VERSION "HNNBNNNYNNNNNNNNNNNNNNNNNNNNNNNNNNNNNNNNNN/4/%%%/4/'%**4NNN///"

NS_ :

BS_:

BU_: BAP_Tester BedienDisp_vo BedienSG_hi CGS DDA Gateway Gateway_PAG GurtMikrofon OTA_FC ZR_High ZR_LIMU ZR_MIB_TOP_ab_Gen3 ZR_Standard

BO_ 2589283621 Klima_17: 8 Gateway
 SG_ KL_NV_Energie_Anf : 12|8@1+ (10,0) [0|2530] "Unit_WattHour"  Vector__XXX
 SG_ KL_FlHz_Soll_VL : 20|3@1+ (1,0) [0|6] "Unit_None"  ZR_High
 SG_ KL_FlHz_Soll_HL : 23|3@1+ (1,0) [0|6] "Unit_None"  ZR_High
 SG_ KL_FlHz_Soll_VR : 26|3@1+ (1,0) [0|6] "Unit_None"  ZR_High
 SG_ KL_FlHz_Soll_HR : 29|3@1+ (1,0) [0|6] "Unit_None"  ZR_High
 SG_ KL_Umluft_Connect_status : 32|3@1+ (1.0,0.0) [0.0|7] ""  ZR_High,ZR_Standard
 SG_ KL_ECO_PRO_Aktiv : 35|1@1+ (1.0,0.0) [0.0|1] ""  OTA_FC,ZR_High
 SG_ KL_QBit_Sonnenintensitaet : 36|1@1+ (1.0,0.0) [0.0|1] ""  Vector__XXX
 SG_ KL_ZR_Anforderung : 37|2@1+ (1.0,0.0) [0.0|3] ""  ZR_High,ZR_LIMU,ZR_MIB_TOP_ab_Gen3,ZR_Standard
 SG_ KL_ACmax_Aktiv : 39|1@1+ (1.0,0.0) [0.0|1] ""  OTA_FC,ZR_High
 SG_ KL_Defrost_Aktiv : 40|1@1+ (1.0,0.0) [0.0|1] ""  OTA_FC,ZR_High
 SG_ KL_ECO_Aktiv : 41|1@1+ (1.0,0.0) [0.0|1] ""  OTA_FC,ZR_High
 SG_ KL_Status_Klimastil : 42|2@1+ (1.0,0.0) [0.0|3] ""  OTA_FC,ZR_High
 SG_ KL_Kundeneingriff_Geblaese : 44|1@1+ (1.0,0.0) [0.0|1] ""  OTA_FC,ZR_High
 SG_ KL_Thermischer_Bedarf : 45|3@1+ (1.0,0.0) [0.0|7] ""  Vector__XXX
 SG_ KL_Eps_Innen : 48|8@1+ (0.5,-50) [-50.0|50.0] "Unit_DegreCelsi"  OTA_FC,ZR_High
 SG_ KL_Sonnenintensitaet : 56|8@1+ (10,0) [0|1000] "Unit_WattPerMeterSquar"  OTA_FC,ZR_High

BO_ 992 Klima_hinten_01: 8 Gateway
 SG_ KL_Fond_Fuss_Temp_hl : 0|10@1+ (0.1,-5) [-5.0|97.1] "Unit_DegreCelsi"  ZR_High
 SG_ KL_SL_Soll_hl : 10|3@1+ (1.0,0.0) [0.0|7] ""  ZR_High
 SG_ KL_SL_Soll_hr : 13|3@1+ (1.0,0.0) [0.0|7] ""  ZR_High
 SG_ KL_Fond_Fuss_Temp_hr : 16|10@1+ (0.1,-5) [-5.0|97.1] "Unit_DegreCelsi"  ZR_High
 SG_ KL_SH_Soll_hl : 26|3@1+ (1.0,0.0) [0.0|7] ""  ZR_High
 SG_ KL_SH_Soll_hr : 29|3@1+ (1.0,0.0) [0.0|7] ""  ZR_High
 SG_ KL_MA_Temp_hl : 32|10@1+ (0.1,-5) [-5.0|97.1] "Unit_DegreCelsi"  ZR_High
 SG_ KL_SIH_Takt_hl : 42|1@1+ (1.0,0.0) [0.0|1] ""  Vector__XXX
 SG_ KL_SIH_Takt_hr : 43|1@1+ (1.0,0.0) [0.0|1] ""  Vector__XXX
 SG_ KL_Fehler_Umluft : 44|1@1+ (1.0,0.0) [0.0|1] ""  ZR_High
 SG_ KL_RAB : 45|1@1+ (1.0,0.0) [0.0|1] ""  Vector__XXX
 SG_ KL_Fond_Absperrventil : 46|1@1+ (1.0,0.0) [0.0|1] ""  Vector__XXX
 SG_ KL_Fond_KD_Fehler : 47|1@1+ (1.0,0.0) [0.0|1] ""  Vector__XXX
 SG_ KL_MA_Temp_hr : 48|10@1+ (0.1,-5) [-5.0|97.1] "Unit_DegreCelsi"  ZR_High
 SG_ KL_Fehler_Fussraum_Klappen : 58|2@1+ (1.0,0.0) [0.0|3] ""  ZR_High
 SG_ KL_Fehler_Temp_Klappen : 60|2@1+ (1.0,0.0) [0.0|3] ""  ZR_High
 SG_ KL_Fehler_Temp_MA_Klappen : 62|2@1+ (1.0,0.0) [0.0|3] ""  ZR_High

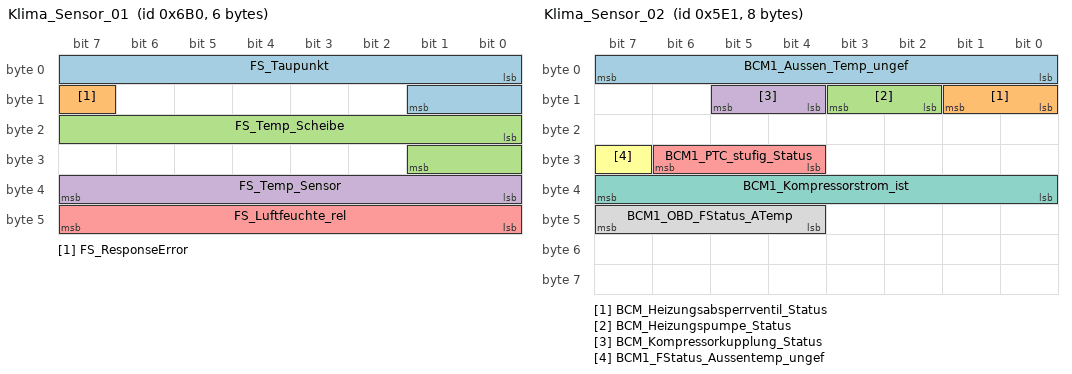
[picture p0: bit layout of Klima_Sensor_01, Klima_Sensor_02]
BO_ 1712 Klima_Sensor_01: 6 Gateway
 SG_ FS_Taupunkt : 0|10@1+ (0.1,-39.6) [-39.5|60.4] "Unit_DegreCelsi"  ZR_High
 SG_ FS_ResponseError : 15|1@1+ (1.0,0.0) [0.0|1] ""  Vector__XXX
 SG_ FS_Temp_Scheibe : 16|10@1+ (0.1,-39.6) [-39.5|60.4] "Unit_DegreCelsi"  OTA_FC,ZR_High
 SG_ FS_Temp_Sensor : 32|8@1+ (0.5,-40) [-39.5|87.0] "Unit_DegreCelsi"  ZR_High
 SG_ FS_Luftfeuchte_rel : 40|8@1+ (0.5,-0.5) [0.0|100.0] "Unit_PerCent"  OTA_FC

BO_ 1505 Klima_Sensor_02: 8 Gateway
 SG_ BCM1_Aussen_Temp_ungef : 0|8@1+ (0.5,-50) [-50.0|76.0] "Unit_DegreCelsi"  ZR_LIMU,ZR_MIB_TOP_ab_Gen3
 SG_ BCM_Heizungsabsperrventil_Status : 8|2@1+ (1.0,0.0) [0.0|3] ""  Vector__XXX
 SG_ BCM_Heizungspumpe_Status : 10|2@1+ (1.0,0.0) [0.0|3] ""  Vector__XXX
 SG_ BCM_Kompressorkupplung_Status : 12|2@1+ (1.0,0.0) [0.0|3] ""  Vector__XXX
 SG_ BCM1_PTC_stufig_Status : 28|3@1+ (1.0,0.0) [0.0|7] ""  Vector__XXX
 SG_ BCM1_FStatus_Aussentemp_ungef : 31|1@1+ (1.0,0.0) [0.0|1] ""  Vector__XXX
 SG_ BCM1_Kompressorstrom_ist : 32|8@1+ (4,0) [0|1000] "Unit_MilliAmper"  Vector__XXX
 SG_ BCM1_OBD_FStatus_ATemp : 44|4@1+ (1.0,0.0) [0.0|15] ""  Vector__XXX

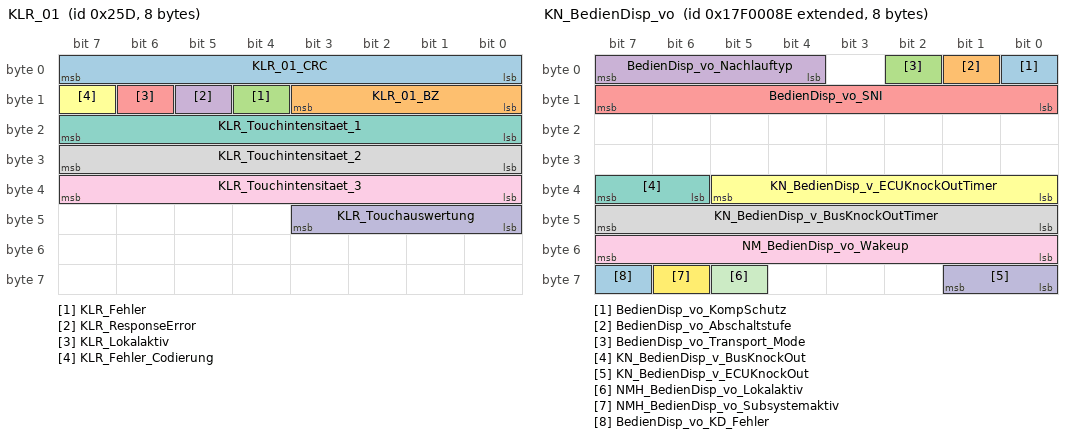
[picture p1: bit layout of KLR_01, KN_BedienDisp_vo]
BO_ 605 KLR_01: 8 Gateway
 SG_ KLR_01_CRC : 0|8@1+ (1,0) [0|255] ""  Vector__XXX
 SG_ KLR_01_BZ : 8|4@1+ (1,0) [0|15] ""  Vector__XXX
 SG_ KLR_Fehler : 12|1@1+ (1.0,0.0) [0.0|1] ""  Vector__XXX
 SG_ KLR_ResponseError : 13|1@1+ (1.0,0.0) [0.0|1] ""  Vector__XXX
 SG_ KLR_Lokalaktiv : 14|1@1+ (1.0,0.0) [0.0|1] ""  Vector__XXX
 SG_ KLR_Fehler_Codierung : 15|1@1+ (1.0,0.0) [0.0|1] ""  Vector__XXX
 SG_ KLR_Touchintensitaet_1 : 16|8@1+ (1,0) [0|250] "Unit_None"  Vector__XXX
 SG_ KLR_Touchintensitaet_2 : 24|8@1+ (1,0) [0|250] "Unit_None"  Vector__XXX
 SG_ KLR_Touchintensitaet_3 : 32|8@1+ (1,0) [0|250] "Unit_None"  Vector__XXX
 SG_ KLR_Touchauswertung : 40|4@1+ (1.0,0.0) [0.0|15] ""  ZR_High

BO_ 2549088398 KN_BedienDisp_vo: 8 BedienDisp_vo
 SG_ BedienDisp_vo_KompSchutz : 0|1@1+ (1.0,0.0) [0.0|1] ""  Vector__XXX
 SG_ BedienDisp_vo_Abschaltstufe : 1|1@1+ (1.0,0.0) [0.0|1] ""  Vector__XXX
 SG_ BedienDisp_vo_Transport_Mode : 2|1@1+ (1.0,0.0) [0.0|1] ""  Vector__XXX
 SG_ BedienDisp_vo_Nachlauftyp : 4|4@1+ (1.0,0.0) [0.0|15] ""  Gateway,Gateway_PAG
 SG_ BedienDisp_vo_SNI : 8|8@1+ (1.0,0.0) [0.0|255] ""  Gateway,Gateway_PAG
 SG_ KN_BedienDisp_v_ECUKnockOutTimer : 32|6@1+ (1,0) [0|62] "Unit_Minut"  Gateway,Gateway_PAG
 SG_ KN_BedienDisp_v_BusKnockOut : 38|2@1+ (1.0,0.0) [0.0|3] ""  Gateway,Gateway_PAG
 SG_ KN_BedienDisp_v_BusKnockOutTimer : 40|8@1+ (1,0) [0|62] "Unit_Minut"  Gateway,Gateway_PAG
 SG_ NM_BedienDisp_vo_Wakeup : 48|8@1+ (1.0,0.0) [0.0|255] ""  Vector__XXX
 SG_ KN_BedienDisp_v_ECUKnockOut : 56|2@1+ (1.0,0.0) [0.0|3] ""  Gateway,Gateway_PAG
 SG_ NMH_BedienDisp_vo_Lokalaktiv : 61|1@1+ (1.0,0.0) [0.0|1] ""  Gateway,Gateway_PAG
 SG_ NMH_BedienDisp_vo_Subsystemaktiv : 62|1@1+ (1.0,0.0) [0.0|1] ""  Vector__XXX
 SG_ BedienDisp_vo_KD_Fehler : 63|1@1+ (1.0,0.0) [0.0|1] ""  Gateway,Gateway_PAG

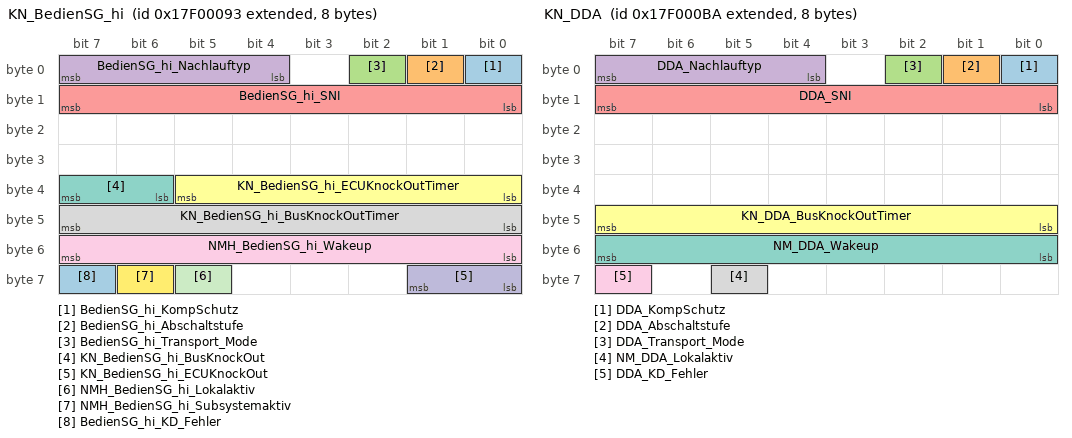
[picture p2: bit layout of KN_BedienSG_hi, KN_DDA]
BO_ 2549088403 KN_BedienSG_hi: 8 BedienSG_hi
 SG_ BedienSG_hi_KompSchutz : 0|1@1+ (1.0,0.0) [0.0|1] ""  Vector__XXX
 SG_ BedienSG_hi_Abschaltstufe : 1|1@1+ (1.0,0.0) [0.0|1] ""  Vector__XXX
 SG_ BedienSG_hi_Transport_Mode : 2|1@1+ (1.0,0.0) [0.0|1] ""  Vector__XXX
 SG_ BedienSG_hi_Nachlauftyp : 4|4@1+ (1.0,0.0) [0.0|15] ""  Gateway,Gateway_PAG
 SG_ BedienSG_hi_SNI : 8|8@1+ (1.0,0.0) [0.0|255] ""  Gateway,Gateway_PAG
 SG_ KN_BedienSG_hi_ECUKnockOutTimer : 32|6@1+ (1,0) [0|62] "Unit_Minut"  Gateway,Gateway_PAG
 SG_ KN_BedienSG_hi_BusKnockOut : 38|2@1+ (1.0,0.0) [0.0|3] ""  Gateway,Gateway_PAG
 SG_ KN_BedienSG_hi_BusKnockOutTimer : 40|8@1+ (1,0) [0|62] "Unit_Minut"  Gateway,Gateway_PAG
 SG_ NMH_BedienSG_hi_Wakeup : 48|8@1+ (1.0,0.0) [0.0|255] ""  Vector__XXX
 SG_ KN_BedienSG_hi_ECUKnockOut : 56|2@1+ (1.0,0.0) [0.0|3] ""  Gateway,Gateway_PAG
 SG_ NMH_BedienSG_hi_Lokalaktiv : 61|1@1+ (1.0,0.0) [0.0|1] ""  Gateway,Gateway_PAG
 SG_ NMH_BedienSG_hi_Subsystemaktiv : 62|1@1+ (1.0,0.0) [0.0|1] ""  Gateway,Gateway_PAG
 SG_ BedienSG_hi_KD_Fehler : 63|1@1+ (1.0,0.0) [0.0|1] ""  Gateway,Gateway_PAG

BO_ 2549088442 KN_DDA: 8 DDA
 SG_ DDA_KompSchutz : 0|1@1+ (1.0,0.0) [0.0|1] ""  Vector__XXX
 SG_ DDA_Abschaltstufe : 1|1@1+ (1.0,0.0) [0.0|1] ""  Vector__XXX
 SG_ DDA_Transport_Mode : 2|1@1+ (1.0,0.0) [0.0|1] ""  Vector__XXX
 SG_ DDA_Nachlauftyp : 4|4@1+ (1.0,0.0) [0.0|15] ""  Gateway,Gateway_PAG
 SG_ DDA_SNI : 8|8@1+ (1.0,0.0) [0.0|255] ""  Gateway,Gateway_PAG
 SG_ KN_DDA_BusKnockOutTimer : 40|8@1+ (1,0) [0|254] ""  Gateway,Gateway_PAG
 SG_ NM_DDA_Wakeup : 48|8@1+ (1.0,0.0) [0.0|255] ""  Vector__XXX
 SG_ NM_DDA_Lokalaktiv : 61|1@1+ (1.0,0.0) [0.0|1] ""  Gateway,Gateway_PAG
 SG_ DDA_KD_Fehler : 63|1@1+ (1.0,0.0) [0.0|1] ""  Gateway,Gateway_PAG

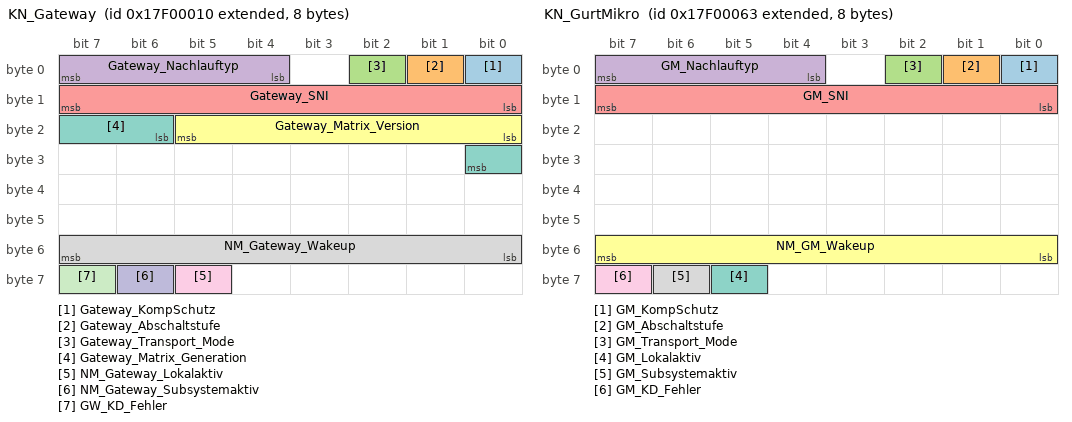
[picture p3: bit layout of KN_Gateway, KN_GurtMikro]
BO_ 2549088272 KN_Gateway: 8 Gateway
 SG_ Gateway_KompSchutz : 0|1@1+ (1.0,0.0) [0.0|1] ""  Vector__XXX
 SG_ Gateway_Abschaltstufe : 1|1@1+ (1.0,0.0) [0.0|1] ""  Vector__XXX
 SG_ Gateway_Transport_Mode : 2|1@1+ (1.0,0.0) [0.0|1] ""  Vector__XXX
 SG_ Gateway_Nachlauftyp : 4|4@1+ (1.0,0.0) [0.0|15] ""  Vector__XXX
 SG_ Gateway_SNI : 8|8@1+ (1.0,0.0) [0.0|255] ""  Vector__XXX
 SG_ Gateway_Matrix_Version : 16|6@1+ (1,0) [0|63] "Unit_None"  Vector__XXX
 SG_ Gateway_Matrix_Generation : 22|3@1+ (1,0) [0|7] "Unit_None"  Vector__XXX
 SG_ NM_Gateway_Wakeup : 48|8@1+ (1.0,0.0) [0.0|255] ""  Vector__XXX
 SG_ NM_Gateway_Lokalaktiv : 61|1@1+ (1.0,0.0) [0.0|1] ""  Vector__XXX
 SG_ NM_Gateway_Subsystemaktiv : 62|1@1+ (1.0,0.0) [0.0|1] ""  Vector__XXX
 SG_ GW_KD_Fehler : 63|1@1+ (1.0,0.0) [0.0|1] ""  Vector__XXX

BO_ 2549088355 KN_GurtMikro: 8 GurtMikrofon
 SG_ GM_KompSchutz : 0|1@1+ (1.0,0.0) [0.0|1] ""  Vector__XXX
 SG_ GM_Abschaltstufe : 1|1@1+ (1.0,0.0) [0.0|1] ""  Vector__XXX
 SG_ GM_Transport_Mode : 2|1@1+ (1.0,0.0) [0.0|1] ""  Vector__XXX
 SG_ GM_Nachlauftyp : 4|4@1+ (1.0,0.0) [0.0|15] ""  Gateway
 SG_ GM_SNI : 8|8@1+ (1.0,0.0) [0.0|255] ""  Gateway
 SG_ NM_GM_Wakeup : 48|8@1+ (1.0,0.0) [0.0|255] ""  Vector__XXX
 SG_ GM_Lokalaktiv : 61|1@1+ (1.0,0.0) [0.0|1] ""  Gateway
 SG_ GM_Subsystemaktiv : 62|1@1+ (1.0,0.0) [0.0|1] ""  Vector__XXX
 SG_ GM_KD_Fehler : 63|1@1+ (1.0,0.0) [0.0|1] ""  Gateway

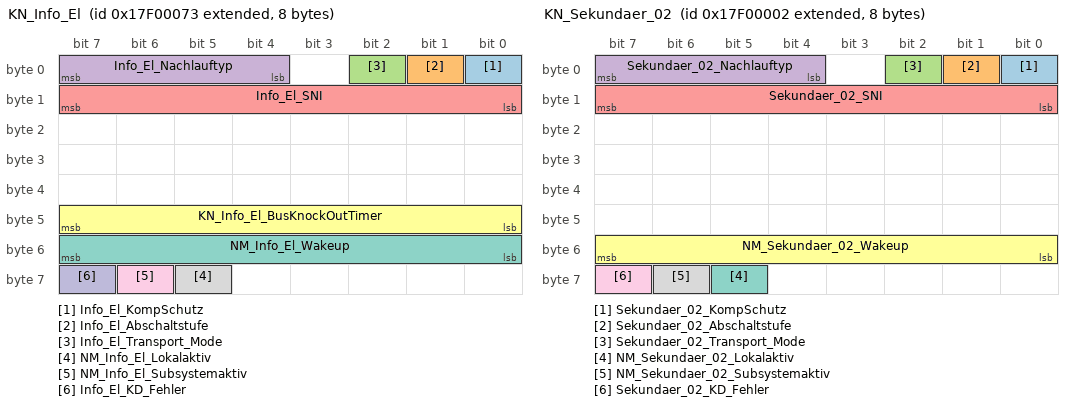
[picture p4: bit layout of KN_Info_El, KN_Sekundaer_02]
BO_ 2549088371 KN_Info_El: 8 ZR_High
 SG_ Info_El_KompSchutz : 0|1@1+ (1.0,0.0) [0.0|1] ""  Vector__XXX
 SG_ Info_El_Abschaltstufe : 1|1@1+ (1.0,0.0) [0.0|1] ""  Vector__XXX
 SG_ Info_El_Transport_Mode : 2|1@1+ (1.0,0.0) [0.0|1] ""  Vector__XXX
 SG_ Info_El_Nachlauftyp : 4|4@1+ (1.0,0.0) [0.0|15] ""  Gateway,Gateway_PAG
 SG_ Info_El_SNI : 8|8@1+ (1.0,0.0) [0.0|255] ""  Gateway,Gateway_PAG
 SG_ KN_Info_El_BusKnockOutTimer : 40|8@1+ (1,0) [0|254] "Unit_Minut"  Gateway
 SG_ NM_Info_El_Wakeup : 48|8@1+ (1.0,0.0) [0.0|255] ""  Vector__XXX
 SG_ NM_Info_El_Lokalaktiv : 61|1@1+ (1.0,0.0) [0.0|1] ""  Gateway,Gateway_PAG
 SG_ NM_Info_El_Subsystemaktiv : 62|1@1+ (1.0,0.0) [0.0|1] ""  Gateway,Gateway_PAG
 SG_ Info_El_KD_Fehler : 63|1@1+ (1.0,0.0) [0.0|1] ""  Gateway,Gateway_PAG

BO_ 2549088258 KN_Sekundaer_02: 8 OTA_FC
 SG_ Sekundaer_02_KompSchutz : 0|1@1+ (1.0,0.0) [0.0|1] ""  Vector__XXX
 SG_ Sekundaer_02_Abschaltstufe : 1|1@1+ (1.0,0.0) [0.0|1] ""  Vector__XXX
 SG_ Sekundaer_02_Transport_Mode : 2|1@1+ (1.0,0.0) [0.0|1] ""  Vector__XXX
 SG_ Sekundaer_02_Nachlauftyp : 4|4@1+ (1.0,0.0) [0.0|15] ""  Gateway_PAG
 SG_ Sekundaer_02_SNI : 8|8@1+ (1.0,0.0) [0.0|255] ""  Gateway_PAG
 SG_ NM_Sekundaer_02_Wakeup : 48|8@1+ (1.0,0.0) [0.0|255] ""  Vector__XXX
 SG_ NM_Sekundaer_02_Lokalaktiv : 61|1@1+ (1.0,0.0) [0.0|1] ""  Vector__XXX
 SG_ NM_Sekundaer_02_Subsystemaktiv : 62|1@1+ (1.0,0.0) [0.0|1] ""  Vector__XXX
 SG_ Sekundaer_02_KD_Fehler : 63|1@1+ (1.0,0.0) [0.0|1] ""  Gateway_PAG

BO_ 779 Kombi_01: 8 Gateway
 SG_ KBI_ABS_Lampe : 0|1@1+ (1.0,0.0) [0.0|1] ""  ZR_High
 SG_ KBI_ESP_Lampe : 1|1@1+ (1.0,0.0) [0.0|1] ""  ZR_High
 SG_ KBI_BKL_Lampe : 2|1@1+ (1.0,0.0) [0.0|1] ""  ZR_High
 SG_ KBI_Airbag_Lampe : 3|1@1+ (1.0,0.0) [0.0|1] ""  ZR_High
 SG_ KBI_SILA_gueltig : 4|1@1+ (1.0,0.0) [0.0|1] ""  Vector__XXX
 SG_ KBI_Lenkung_Lampe : 5|1@1+ (1,0) [0|1] ""  Vector__XXX
 SG_ KBI_Vorglueh_System_Lampe : 6|1@1+ (1.0,0.0) [0.0|1] ""  ZR_High
 SG_ KBI_NV_in_Anzeige : 7|1@1+ (1.0,0.0) [0.0|1] ""  ZR_High
 SG_ Kombi_01_BZ : 8|4@1+ (1,0) [0|15] ""  Vector__XXX
 SG_ KBI_Anzeigestatus_ACC : 12|1@1+ (1.0,0.0) [0.0|1] ""  ZR_High
 SG_ KBI_Anzeigestatus_GRA : 13|2@1+ (1.0,0.0) [0.0|3] ""  ZR_High
 SG_ KBI_Tankwarnung : 16|1@1+ (1.0,0.0) [0.0|1] ""  ZR_High,ZR_LIMU,ZR_MIB_TOP_ab_Gen3,ZR_Standard
 SG_ KBI_MFA_v_Einheit_01 : 17|1@1+ (1.0,0.0) [0.0|1] ""  BedienSG_hi,ZR_High,ZR_LIMU,ZR_MIB_TOP_ab_Gen3,ZR_Standard
 SG_ KBI_im_Stellgliedtest : 18|1@1+ (1.0,0.0) [0.0|1] ""  Vector__XXX
 SG_ KBI_Anzeigefehler_LDW : 19|2@1+ (1.0,0.0) [0.0|3] ""  Vector__XXX
 SG_ KBI_Tankwarnung_ungueltig : 21|1@1+ (1.0,0.0) [0.0|1] ""  ZR_High,ZR_LIMU,ZR_MIB_TOP_ab_Gen3,ZR_Standard
 SG_ KBI_Handbremse : 23|1@1+ (1.0,0.0) [0.0|1] ""  Vector__XXX
 SG_ KBI_V_Digital : 24|9@1+ (1,0) [0|511] ""  BedienSG_hi,ZR_High,ZR_LIMU,ZR_MIB_TOP_ab_Gen3,ZR_Standard
 SG_ KBI_PLA_in_Anzeige : 33|1@1+ (1.0,0.0) [0.0|1] ""  ZR_High
 SG_ KBI_Anzeigefehler_NV : 34|1@1+ (1.0,0.0) [0.0|1] ""  Vector__XXX
 SG_ KBI_Anzeigestatus_LIM : 35|2@1+ (1.0,0.0) [0.0|3] ""  Vector__XXX
 SG_ KBI_ARA_in_Anzeige : 37|1@1+ (1.0,0.0) [0.0|1] ""  ZR_High
 SG_ KBI_Taster_Lift : 38|1@1+ (1.0,0.0) [0.0|1] ""  Vector__XXX
 SG_ KBI_Taster_Fahrwerk : 39|1@1+ (1.0,0.0) [0.0|1] ""  Vector__XXX
 SG_ KBI_GRA_Hauptschalter : 40|2@1+ (1.0,0.0) [0.0|3] ""  Vector__XXX
 SG_ KBI_angez_Geschw : 48|10@1+ (0.32,0) [0.00|325.12] "Unit_KiloMeterPerHour"  BedienSG_hi,OTA_FC,ZR_High,ZR_LIMU,ZR_MIB_TOP_ab_Gen3,ZR_Standard
 SG_ KBI_Einheit_Tacho : 58|1@1+ (1.0,0.0) [0.0|1] ""  BedienSG_hi,ZR_High
 SG_ KBI_Konsistenz_ACC : 59|1@1+ (1.0,0.0) [0.0|1] ""  Vector__XXX
 SG_ KBI_Fehler_Anzeige_ACC : 60|1@1+ (1.0,0.0) [0.0|1] ""  ZR_High
 SG_ KBI_Anzeigefehler_SWA : 61|2@1+ (1.0,0.0) [0.0|3] ""  ZR_High
 SG_ KBI_Systemstatus : 63|1@1+ (1.0,0.0) [0.0|1] ""  Vector__XXX

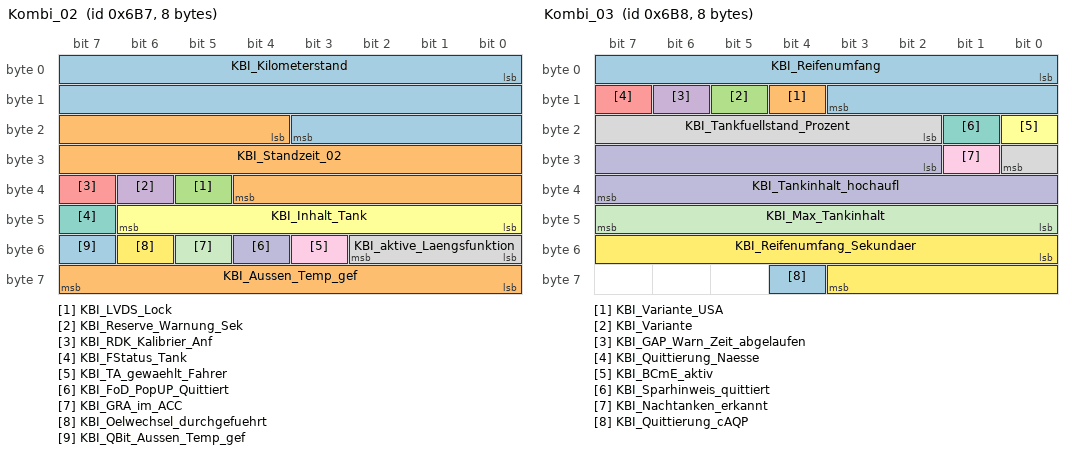
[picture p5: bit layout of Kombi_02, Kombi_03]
BO_ 1719 Kombi_02: 8 Gateway
 SG_ KBI_Kilometerstand : 0|20@1+ (1,0) [0|1048573] "Unit_KiloMeter"  Vector__XXX
 SG_ KBI_Standzeit_02 : 20|17@1+ (1,0) [0|131068] "Unit_Secon"  BedienDisp_vo,BedienSG_hi,ZR_High,ZR_Standard
 SG_ KBI_LVDS_Lock : 37|1@1+ (1.0,0.0) [0.0|1] ""  ZR_High
 SG_ KBI_Reserve_Warnung_Sek : 38|1@1+ (1.0,0.0) [0.0|1] ""  ZR_High,ZR_LIMU,ZR_MIB_TOP_ab_Gen3,ZR_Standard
 SG_ KBI_RDK_Kalibrier_Anf : 39|1@1+ (1.0,0.0) [0.0|1] ""  Vector__XXX
 SG_ KBI_Inhalt_Tank : 40|7@1+ (1,0) [0|125] "Unit_Liter"  Vector__XXX
 SG_ KBI_FStatus_Tank : 47|1@1+ (1.0,0.0) [0.0|1] ""  ZR_High,ZR_LIMU,ZR_MIB_TOP_ab_Gen3,ZR_Standard
 SG_ KBI_aktive_Laengsfunktion : 48|3@1+ (1.0,0.0) [0.0|7] ""  OTA_FC,ZR_High
 SG_ KBI_TA_gewaehlt_Fahrer : 51|1@1+ (1.0,0.0) [0.0|1] ""  Vector__XXX
 SG_ KBI_FoD_PopUP_Quittiert : 52|1@1+ (1.0,0.0) [0.0|1] ""  Vector__XXX
 SG_ KBI_GRA_im_ACC : 53|1@1+ (1.0,0.0) [0.0|1] ""  Vector__XXX
 SG_ KBI_Oelwechsel_durchgefuehrt : 54|1@1+ (1.0,0.0) [0.0|1] ""  ZR_High
 SG_ KBI_QBit_Aussen_Temp_gef : 55|1@1+ (1.0,0.0) [0.0|1] ""  BedienDisp_vo,BedienSG_hi,ZR_High
 SG_ KBI_Aussen_Temp_gef : 56|8@1+ (0.5,-50) [-50.0|75.0] "Unit_DegreCelsi"  BedienDisp_vo,BedienSG_hi,OTA_FC,ZR_Standard

BO_ 1720 Kombi_03: 8 Gateway
 SG_ KBI_Reifenumfang : 0|12@1+ (1,0) [0|4095] "Unit_MilliMeter"  ZR_High,ZR_Standard
 SG_ KBI_Variante_USA : 12|1@1+ (1.0,0.0) [0.0|1] ""  BedienSG_hi,ZR_High
 SG_ KBI_Variante : 13|1@1+ (1.0,0.0) [0.0|1] ""  BedienSG_hi
 SG_ KBI_GAP_Warn_Zeit_abgelaufen : 14|1@1+ (1.0,0.0) [0.0|1] ""  Vector__XXX
 SG_ KBI_Quittierung_Naesse : 15|1@1+ (1.0,0.0) [0.0|1] ""  Vector__XXX
 SG_ KBI_BCmE_aktiv : 16|1@1+ (1.0,0.0) [0.0|1] ""  Vector__XXX
 SG_ KBI_Sparhinweis_quittiert : 17|1@1+ (1.0,0.0) [0.0|1] ""  Vector__XXX
 SG_ KBI_Tankfuellstand_Prozent : 18|7@1+ (1,0) [0|100] "Unit_PerCent"  BedienSG_hi,ZR_High
 SG_ KBI_Nachtanken_erkannt : 25|1@1+ (1.0,0.0) [0.0|1] ""  ZR_High,ZR_MIB_TOP_ab_Gen3
 SG_ KBI_Tankinhalt_hochaufl : 26|14@1+ (0.01,0) [0.00|163.81] "Unit_Liter"  Vector__XXX
 SG_ KBI_Max_Tankinhalt : 40|8@1+ (0.5,0) [0.0|126.5] ""  ZR_High
 SG_ KBI_Reifenumfang_Sekundaer : 48|12@1+ (1,0) [0|4095] "Unit_MilliMeter"  Vector__XXX
 SG_ KBI_Quittierung_cAQP : 60|1@1+ (1.0,0.0) [0.0|1] ""  Vector__XXX

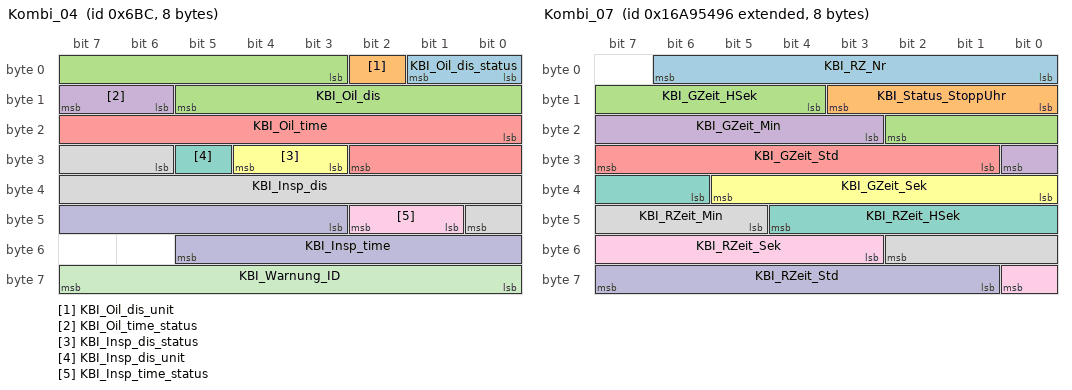
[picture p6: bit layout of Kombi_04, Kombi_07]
BO_ 1724 Kombi_04: 8 Gateway
 SG_ KBI_Oil_dis_status : 0|2@1+ (1.0,0.0) [0.0|3] ""  ZR_High
 SG_ KBI_Oil_dis_unit : 2|1@1+ (1.0,0.0) [0.0|1] ""  ZR_High
 SG_ KBI_Oil_dis : 3|11@1+ (100,0) [0|204700] ""  ZR_High
 SG_ KBI_Oil_time_status : 14|2@1+ (1.0,0.0) [0.0|3] ""  ZR_High
 SG_ KBI_Oil_time : 16|11@1+ (1,0) [0|2047] ""  ZR_High
 SG_ KBI_Insp_dis_status : 27|2@1+ (1.0,0.0) [0.0|3] ""  ZR_High
 SG_ KBI_Insp_dis_unit : 29|1@1+ (1.0,0.0) [0.0|1] ""  ZR_High
 SG_ KBI_Insp_dis : 30|11@1+ (100,0) [0|204700] ""  ZR_High
 SG_ KBI_Insp_time_status : 41|2@1+ (1.0,0.0) [0.0|3] ""  ZR_High
 SG_ KBI_Insp_time : 43|11@1+ (1,0) [0|2047] ""  ZR_High
 SG_ KBI_Warnung_ID : 56|8@1+ (1,0) [0|255] ""  ZR_High

BO_ 2527679638 Kombi_07: 8 Gateway
 SG_ KBI_RZ_Nr : 0|7@1+ (1,0) [0|99] ""  ZR_High,ZR_LIMU,ZR_MIB_TOP_ab_Gen3
 SG_ KBI_Status_StoppUhr : 8|4@1+ (1.0,0.0) [0.0|15] ""  BedienDisp_vo,ZR_High,ZR_LIMU,ZR_MIB_TOP_ab_Gen3
 SG_ KBI_GZeit_HSek : 12|7@1+ (1,0) [0|99] "Unit_MilliSecon"  BedienDisp_vo,ZR_High,ZR_LIMU,ZR_MIB_TOP_ab_Gen3
 SG_ KBI_GZeit_Min : 19|6@1+ (1,0) [0|59] "Unit_Minut"  BedienDisp_vo,ZR_High,ZR_LIMU,ZR_MIB_TOP_ab_Gen3
 SG_ KBI_GZeit_Std : 25|7@1+ (1,0) [0|99] "Unit_Hours"  BedienDisp_vo,ZR_High,ZR_LIMU,ZR_MIB_TOP_ab_Gen3
 SG_ KBI_GZeit_Sek : 32|6@1+ (1,0) [0|59] "Unit_Secon"  BedienDisp_vo,ZR_High,ZR_LIMU,ZR_MIB_TOP_ab_Gen3
 SG_ KBI_RZeit_HSek : 38|7@1+ (1,0) [0|99] ""  ZR_High,ZR_LIMU,ZR_MIB_TOP_ab_Gen3
 SG_ KBI_RZeit_Min : 45|6@1+ (1,0) [0|59] "Unit_Minut"  ZR_High,ZR_LIMU,ZR_MIB_TOP_ab_Gen3
 SG_ KBI_RZeit_Sek : 51|6@1+ (1,0) [0|59] "Unit_Secon"  ZR_High,ZR_LIMU,ZR_MIB_TOP_ab_Gen3
 SG_ KBI_RZeit_Std : 57|7@1+ (1,0) [0|99] "Unit_Hours"  ZR_High,ZR_LIMU,ZR_MIB_TOP_ab_Gen3

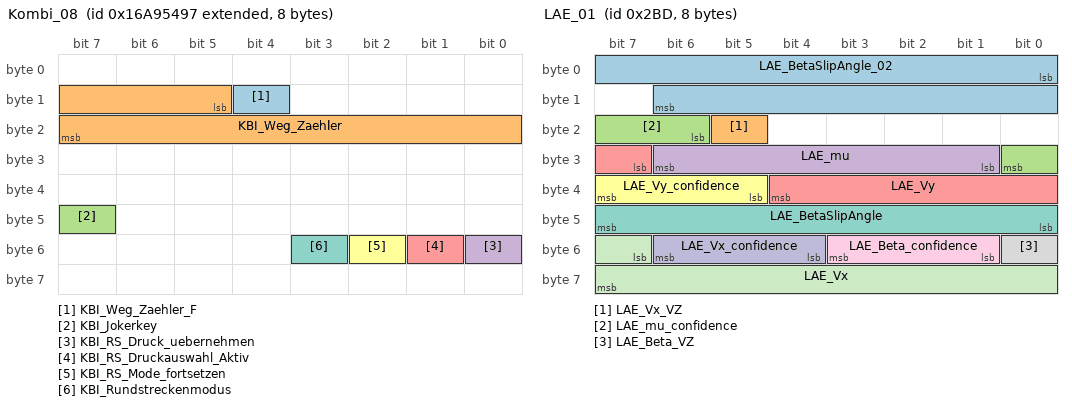
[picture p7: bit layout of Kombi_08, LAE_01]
BO_ 2527679639 Kombi_08: 8 Gateway
 SG_ KBI_Weg_Zaehler_F : 12|1@1+ (1.0,0.0) [0.0|1] ""  ZR_High,ZR_LIMU,ZR_MIB_TOP_ab_Gen3
 SG_ KBI_Weg_Zaehler : 13|11@1+ (1,0) [0|2047] "Unit_Meter"  ZR_High,ZR_LIMU,ZR_MIB_TOP_ab_Gen3
 SG_ KBI_Jokerkey : 47|1@1+ (1.0,0.0) [0.0|1] ""  ZR_LIMU,ZR_MIB_TOP_ab_Gen3
 SG_ KBI_RS_Druck_uebernehmen : 48|1@1+ (1.0,0.0) [0.0|1] ""  Vector__XXX
 SG_ KBI_RS_Druckauswahl_Aktiv : 49|1@1+ (1.0,0.0) [0.0|1] ""  Vector__XXX
 SG_ KBI_RS_Mode_fortsetzen : 50|1@1+ (1.0,0.0) [0.0|1] ""  Vector__XXX
 SG_ KBI_Rundstreckenmodus : 51|1@1+ (1.0,0.0) [0.0|1] ""  Vector__XXX

BO_ 2527679656 Kombi_23: 8 Gateway
 SG_ KBI_StartupAnimation : 61|3@1+ (1.0,0.0) [0.0|7] ""  ZR_High

BO_ 2549875055 KS_AMP_Req: 8 Gateway
 SG_ KS_AMP_Req_Data : 0|64@1+ (1.0,0.0) [0.0|18446744073709551615] ""  ZR_High,ZR_MIB_TOP_ab_Gen3,ZR_Standard

BO_ 2550006127 KS_AMP_Resp: 8 ZR_High
 SG_ KS_AMP_Resp_Data : 0|64@1+ (1.0,0.0) [0.0|18446744073709551615] ""  Gateway,Gateway_PAG

BO_ 2549875059 KS_Info_El_Req: 8 Gateway
 SG_ KS_Info_El_Req_Data : 0|64@1+ (1.0,0.0) [0.0|18446744073709551615] ""  ZR_High,ZR_MIB_TOP_ab_Gen3,ZR_Standard

BO_ 2550006131 KS_Info_El_Resp: 8 ZR_High
 SG_ KS_Info_El_Resp_Data : 0|64@1+ (1.0,0.0) [0.0|18446744073709551615] ""  Gateway,Gateway_PAG

BO_ 2549875056 KS_Laufwerke_Req: 8 Gateway
 SG_ KS_Laufwerke_Req_Data : 0|64@1+ (1.0,0.0) [0.0|18446744073709551615] ""  ZR_High,ZR_MIB_TOP_ab_Gen3,ZR_Standard

BO_ 2550006128 KS_Laufwerke_Resp: 8 ZR_High
 SG_ KS_Laufwerke_Resp_Data : 0|64@1+ (1.0,0.0) [0.0|18446744073709551615] ""  Gateway,Gateway_PAG

BO_ 2549875053 KS_TV_Tuner_Req: 8 Gateway
 SG_ KS_TV_Tuner_Req_Data : 0|64@1+ (1.0,0.0) [0.0|18446744073709551615] ""  ZR_High,ZR_MIB_TOP_ab_Gen3,ZR_Standard

BO_ 2550006125 KS_TV_Tuner_Resp: 8 ZR_High
 SG_ KS_TV_Tuner_Resp_Data : 0|64@1+ (1.0,0.0) [0.0|18446744073709551615] ""  Gateway,Gateway_PAG

BO_ 701 LAE_01: 8 Gateway
 SG_ LAE_BetaSlipAngle_02 : 0|15@1+ (0.01,0) [0.00|327.65] "Unit_DegreOfArc"  ZR_LIMU
 SG_ LAE_Vx_VZ : 21|1@1+ (1.0,0.0) [0.0|1] ""  ZR_LIMU
 SG_ LAE_mu_confidence : 22|3@1+ (1.0,0.0) [0.0|7] ""  ZR_LIMU
 SG_ LAE_mu : 25|6@1+ (0.05,0) [0.00|3.05] "Unit_None"  ZR_LIMU
 SG_ LAE_Vy : 31|6@1+ (0.491803,0) [0.000000|29.999983] "Unit_MeterPerSecon"  ZR_LIMU
 SG_ LAE_Vy_confidence : 37|3@1+ (1.0,0.0) [0.0|7] ""  ZR_LIMU
 SG_ LAE_BetaSlipAngle : 40|8@1+ (0.711462451,0) [0E-9|180.000000103] "Unit_DegreOfArc"  ZR_LIMU
 SG_ LAE_Beta_VZ : 48|1@1+ (1.0,0.0) [0.0|1] ""  ZR_LIMU
 SG_ LAE_Beta_confidence : 49|3@1+ (1.0,0.0) [0.0|7] ""  ZR_LIMU
 SG_ LAE_Vx_confidence : 52|3@1+ (1.0,0.0) [0.0|7] ""  ZR_LIMU
 SG_ LAE_Vx : 55|9@1+ (0.25540275,0) [0E-8|129.99999975] "Unit_MeterPerSecon"  ZR_LIMU

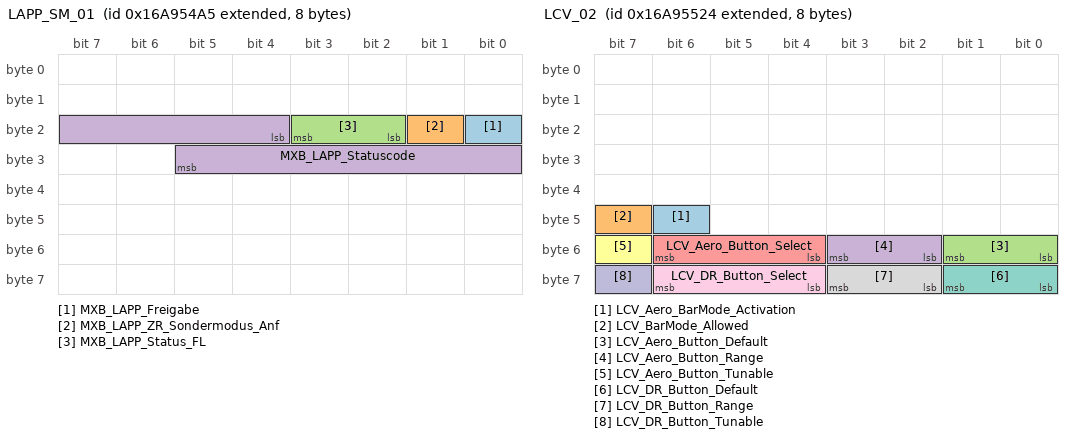
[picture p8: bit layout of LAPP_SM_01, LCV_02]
BO_ 2527679653 LAPP_SM_01: 8 Gateway
 SG_ MXB_LAPP_Freigabe : 16|1@1+ (1.0,0.0) [0.0|1] ""  DDA
 SG_ MXB_LAPP_ZR_Sondermodus_Anf : 17|1@1+ (1.0,0.0) [0.0|1] ""  DDA,ZR_High,ZR_Standard
 SG_ MXB_LAPP_Status_FL : 18|2@1+ (1.0,0.0) [0.0|3] ""  DDA
 SG_ MXB_LAPP_Statuscode : 20|10@1+ (1,0) [0|1023] "Unit_None"  DDA

BO_ 2463978818 LCV_01: 8 Gateway
 SG_ LCV_01_CRC : 0|8@1+ (1,0) [0|255] ""  Vector__XXX
 SG_ LCV_01_BZ : 8|4@1+ (1,0) [0|15] ""  Vector__XXX
 SG_ LCV_ESP_Zuschaltung : 12|1@1+ (1.0,0.0) [0.0|1] ""  Vector__XXX
 SG_ LCV_BrakeGongTemp : 13|1@1+ (1.0,0.0) [0.0|1] ""  Vector__XXX
 SG_ BTM_BrakeSystem_Status : 14|4@1+ (1.0,0.0) [0.0|15] ""  ZR_LIMU
 SG_ BTM_BrakeSystem_Text : 18|4@1+ (1.0,0.0) [0.0|15] ""  ZR_LIMU
 SG_ BTM_BrakeSystem_Warnlampe : 22|1@1+ (1.0,0.0) [0.0|1] ""  ZR_LIMU
 SG_ LCV_Aero_EngineBay_Cooling : 23|1@1+ (1.0,0.0) [0.0|1] ""  Vector__XXX
 SG_ LCV_Aero_Front_System_Status : 24|3@1+ (1.0,0.0) [0.0|7] ""  Vector__XXX
 SG_ LCV_Aero_Rear_System_Status : 27|3@1+ (1.0,0.0) [0.0|7] ""  Vector__XXX
 SG_ LCV_DR_Systemstatus : 30|3@1+ (1.0,0.0) [0.0|7] ""  Vector__XXX
 SG_ LCV_DR_Text : 33|3@1+ (1.0,0.0) [0.0|7] ""  Vector__XXX
 SG_ LCV_DR_Warnlampe : 36|2@1+ (1.0,0.0) [0.0|3] ""  Vector__XXX
 SG_ LCV_Lift_Status : 38|4@1+ (1.0,0.0) [0.0|15] ""  ZR_LIMU
 SG_ LCV_Lift_Text : 42|3@1+ (1.0,0.0) [0.0|7] ""  Vector__XXX
 SG_ LCV_Lift_Warnlampe_Status : 45|2@1+ (1.0,0.0) [0.0|3] ""  Vector__XXX
 SG_ LCV_Aero_Perf_Limit_Speed : 47|8@1+ (1,100) [100|353] "Unit_KiloMeterPerHour"  Vector__XXX
 SG_ LCV_Aero_Perf_Limit : 55|1@1+ (1.0,0.0) [0.0|1] ""  Vector__XXX
 SG_ LCV_HD_offen : 56|1@1+ (1.0,0.0) [0.0|1] ""  ZR_LIMU

BO_ 2527679780 LCV_02: 8 Gateway
 SG_ LCV_Aero_BarMode_Activation : 46|1@1+ (1.0,0.0) [0.0|1] ""  ZR_LIMU
 SG_ LCV_BarMode_Allowed : 47|1@1+ (1.0,0.0) [0.0|1] ""  Vector__XXX
 SG_ LCV_Aero_Button_Default : 48|2@1+ (1.0,0.0) [0.0|3] ""  ZR_LIMU
 SG_ LCV_Aero_Button_Range : 50|2@1+ (1.0,0.0) [0.0|3] ""  ZR_LIMU
 SG_ LCV_Aero_Button_Select : 52|3@1+ (1.0,0.0) [0.0|7] ""  ZR_LIMU
 SG_ LCV_Aero_Button_Tunable : 55|1@1+ (1.0,0.0) [0.0|1] ""  ZR_LIMU
 SG_ LCV_DR_Button_Default : 56|2@1+ (1.0,0.0) [0.0|3] ""  ZR_LIMU
 SG_ LCV_DR_Button_Range : 58|2@1+ (1.0,0.0) [0.0|3] ""  ZR_LIMU
 SG_ LCV_DR_Button_Select : 60|3@1+ (1.0,0.0) [0.0|7] ""  ZR_LIMU
 SG_ LCV_DR_Button_Tunable : 63|1@1+ (1.0,0.0) [0.0|1] ""  ZR_LIMU

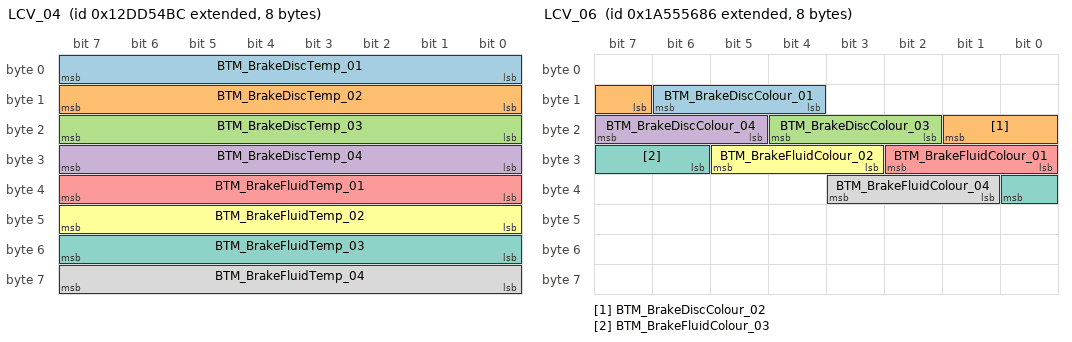
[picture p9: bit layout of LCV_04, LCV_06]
BO_ 2463978684 LCV_04: 8 Gateway
 SG_ BTM_BrakeDiscTemp_01 : 0|8@1+ (10,-30) [-30|2500] "Unit_DegreCelsi"  ZR_LIMU
 SG_ BTM_BrakeDiscTemp_02 : 8|8@1+ (10,-30) [-30|2500] "Unit_DegreCelsi"  ZR_LIMU
 SG_ BTM_BrakeDiscTemp_03 : 16|8@1+ (10,-30) [-30|2500] "Unit_DegreCelsi"  ZR_LIMU
 SG_ BTM_BrakeDiscTemp_04 : 24|8@1+ (10,-30) [-30|2500] "Unit_DegreCelsi"  ZR_LIMU
 SG_ BTM_BrakeFluidTemp_01 : 32|8@1+ (2,-30) [-30|476] "Unit_DegreCelsi"  ZR_LIMU
 SG_ BTM_BrakeFluidTemp_02 : 40|8@1+ (2,-30) [-30|476] "Unit_DegreCelsi"  ZR_LIMU
 SG_ BTM_BrakeFluidTemp_03 : 48|8@1+ (2,-30) [-30|476] "Unit_DegreCelsi"  ZR_LIMU
 SG_ BTM_BrakeFluidTemp_04 : 56|8@1+ (2,-30) [-30|476] "Unit_DegreCelsi"  ZR_LIMU

BO_ 548 LCV_05: 8 Gateway
 SG_ LCV_Aero_Front_Ratio : 12|7@1+ (1,0) [0|125] "Unit_None"  ZR_LIMU
 SG_ LCV_Aero_Long_Ratio : 19|7@1+ (1,0) [0|125] "Unit_None"  ZR_LIMU

BO_ 2589283974 LCV_06: 8 Gateway
 SG_ BTM_BrakeDiscColour_01 : 12|3@1+ (1.0,0.0) [0.0|7] ""  ZR_LIMU
 SG_ BTM_BrakeDiscColour_02 : 15|3@1+ (1.0,0.0) [0.0|7] ""  ZR_LIMU
 SG_ BTM_BrakeDiscColour_03 : 18|3@1+ (1.0,0.0) [0.0|7] ""  ZR_LIMU
 SG_ BTM_BrakeDiscColour_04 : 21|3@1+ (1.0,0.0) [0.0|7] ""  ZR_LIMU
 SG_ BTM_BrakeFluidColour_01 : 24|3@1+ (1.0,0.0) [0.0|7] ""  ZR_LIMU
 SG_ BTM_BrakeFluidColour_02 : 27|3@1+ (1.0,0.0) [0.0|7] ""  ZR_LIMU
 SG_ BTM_BrakeFluidColour_03 : 30|3@1+ (1.0,0.0) [0.0|7] ""  ZR_LIMU
 SG_ BTM_BrakeFluidColour_04 : 33|3@1+ (1.0,0.0) [0.0|7] ""  ZR_LIMU

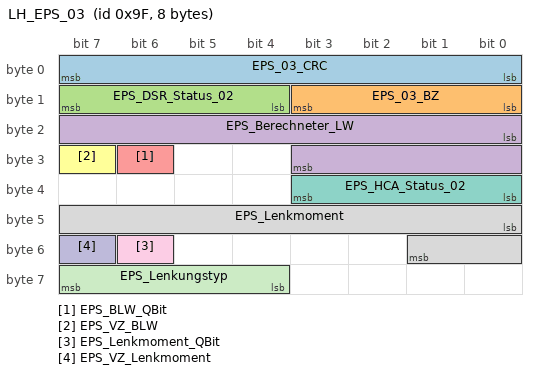
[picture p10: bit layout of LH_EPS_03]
BO_ 159 LH_EPS_03: 8 Gateway
 SG_ EPS_03_CRC : 0|8@1+ (1,0) [0|255] ""  Vector__XXX
 SG_ EPS_03_BZ : 8|4@1+ (1,0) [0|15] ""  Vector__XXX
 SG_ EPS_DSR_Status_02 : 12|4@1+ (1.0,0.0) [0.0|15] ""  Vector__XXX
 SG_ EPS_Berechneter_LW : 16|12@1+ (0.15,0) [0.00|613.95] "Unit_DegreOfArc"  ZR_MIB_TOP_ab_Gen3
 SG_ EPS_BLW_QBit : 30|1@1+ (1.0,0.0) [0.0|1] ""  Vector__XXX
 SG_ EPS_VZ_BLW : 31|1@1+ (1.0,0.0) [0.0|1] ""  Vector__XXX
 SG_ EPS_HCA_Status_02 : 32|4@1+ (1.0,0.0) [0.0|15] ""  Vector__XXX
 SG_ EPS_Lenkmoment : 40|10@1+ (0.01,0) [0.00|8.00] "Unit_NewtoMeter"  Vector__XXX
 SG_ EPS_Lenkmoment_QBit : 54|1@1+ (1.0,0.0) [0.0|1] ""  Vector__XXX
 SG_ EPS_VZ_Lenkmoment : 55|1@1+ (1.0,0.0) [0.0|1] ""  Vector__XXX
 SG_ EPS_Lenkungstyp : 60|4@1+ (1.0,0.0) [0.0|15] ""  Vector__XXX

BO_ 981 Licht_Anf_01: 8 Gateway
 SG_ Licht_Anf_01_CRC : 0|8@1+ (1,0) [0|255] ""  Vector__XXX
 SG_ Licht_Anf_01_BZ : 8|4@1+ (1,0) [0|15] ""  Vector__XXX
 SG_ BCM1_Kurvenlicht_links_Anf : 12|1@1+ (1.0,0.0) [0.0|1] ""  ZR_High
 SG_ BCM1_Kurvenlicht_rechts_Anf : 13|1@1+ (1.0,0.0) [0.0|1] ""  ZR_High
 SG_ BCM1_Standlicht_Anf : 14|1@1+ (1.0,0.0) [0.0|1] ""  ZR_High
 SG_ BCM1_Abblendlicht_Anf : 15|1@1+ (1.0,0.0) [0.0|1] ""  OTA_FC,ZR_High
 SG_ BCM1_Fernlicht_Anf : 16|1@1+ (1.0,0.0) [0.0|1] ""  ZR_High
 SG_ BCM1_Nebellicht_Anf : 17|1@1+ (1.0,0.0) [0.0|1] ""  ZR_High
 SG_ BCM1_Parklicht_li_Anf : 18|1@1+ (1.0,0.0) [0.0|1] ""  ZR_High
 SG_ BCM1_Parklicht_re_Anf : 19|1@1+ (1.0,0.0) [0.0|1] ""  ZR_High
 SG_ BCM1_Nebelschluss_Ahg_Anf : 20|1@1+ (1.0,0.0) [0.0|1] ""  ZR_High
 SG_ BCM1_Nebelschluss_Fzg_Anf : 21|1@1+ (1.0,0.0) [0.0|1] ""  ZR_High
 SG_ BCM1_Schlusslicht_Anf : 22|1@1+ (1.0,0.0) [0.0|1] ""  ZR_High
 SG_ BCM_Rueckfahrlicht_Anf : 23|1@1+ (1.0,0.0) [0.0|1] ""  ZR_High,ZR_MIB_TOP_ab_Gen3,ZR_Standard
 SG_ BCM1_Signaturlicht_Anf : 24|1@1+ (1.0,0.0) [0.0|1] ""  Vector__XXX
 SG_ BCM1_Umfeldleuchten_Anf : 25|1@1+ (1.0,0.0) [0.0|1] ""  ZR_High
 SG_ BCM1_Tagfahrlicht_Anf : 26|1@1+ (1.0,0.0) [0.0|1] ""  ZR_High
 SG_ BCM1_Regenlicht_Anf : 27|1@1+ (1.0,0.0) [0.0|1] ""  ZR_High
 SG_ BCM1_Autobahnlicht_Anf : 28|1@1+ (1.0,0.0) [0.0|1] ""  ZR_High
 SG_ BCM1_Touristen_Licht_Anf : 29|1@1+ (1.0,0.0) [0.0|1] ""  ZR_High
 SG_ BCM1_CH_aktiv : 30|1@1+ (1.0,0.0) [0.0|1] ""  ZR_High
 SG_ BCM1_LH_aktiv : 31|1@1+ (1.0,0.0) [0.0|1] ""  ZR_High
 SG_ BCM1_Gleitende_Leuchtw_Anf : 32|1@1+ (1.0,0.0) [0.0|1] ""  ZR_High
 SG_ BCM1_GLW_Fernlicht_Anf : 33|1@1+ (1.0,0.0) [0.0|1] ""  ZR_High
 SG_ BCM1_Adaptive_Lichtvert_Anf : 34|1@1+ (1.0,0.0) [0.0|1] ""  ZR_High
 SG_ BCM1_FoD_Sperrung_WiBli : 35|2@1+ (1.0,0.0) [0.0|3] ""  Vector__XXX
 SG_ BCM1_FOD_Sperrung_Animationen_HL : 37|2@1+ (1.0,0.0) [0.0|3] ""  Vector__XXX
 SG_ BCM1_Animationssperrung : 39|1@1+ (1.0,0.0) [0.0|1] ""  Vector__XXX
 SG_ BCM1_CH_LH_aktiv : 40|1@1+ (1.0,0.0) [0.0|1] ""  ZR_High
 SG_ BCM1_Allwetterlicht_Anf : 41|1@1+ (1.0,0.0) [0.0|1] ""  ZR_High
 SG_ BCM1_Schlusslicht_Signatur : 60|4@1+ (1.0,0.0) [0.0|15] ""  Vector__XXX

BO_TX_BU_ 2589283621 :Gateway,Gateway_PAG;
BO_TX_BU_ 992 :Gateway,Gateway_PAG;
BO_TX_BU_ 1712 :Gateway,Gateway_PAG;
BO_TX_BU_ 1505 :Gateway,Gateway_PAG;
BO_TX_BU_ 605 :Gateway,Gateway_PAG;
BO_TX_BU_ 2549088272 :Gateway,Gateway_PAG;
BO_TX_BU_ 2549088371 :ZR_High,ZR_LIMU,ZR_MIB_TOP_ab_Gen3,ZR_Standard;
BO_TX_BU_ 779 :Gateway,Gateway_PAG;
BO_TX_BU_ 1719 :Gateway,Gateway_PAG;
BO_TX_BU_ 1720 :Gateway,Gateway_PAG;
BO_TX_BU_ 1724 :Gateway,Gateway_PAG;
BO_TX_BU_ 2527679638 :Gateway,Gateway_PAG;
BO_TX_BU_ 2527679639 :Gateway,Gateway_PAG;
BO_TX_BU_ 2527679656 :Gateway,Gateway_PAG;
BO_TX_BU_ 2549875055 :Gateway,Gateway_PAG;
BO_TX_BU_ 2550006127 :ZR_High,ZR_MIB_TOP_ab_Gen3,ZR_Standard;
BO_TX_BU_ 2549875059 :Gateway,Gateway_PAG;
BO_TX_BU_ 2550006131 :ZR_High,ZR_MIB_TOP_ab_Gen3,ZR_Standard;
BO_TX_BU_ 2549875056 :Gateway,Gateway_PAG;
BO_TX_BU_ 2550006128 :ZR_High,ZR_MIB_TOP_ab_Gen3,ZR_Standard;
BO_TX_BU_ 2549875053 :Gateway,Gateway_PAG;
BO_TX_BU_ 2550006125 :ZR_High,ZR_MIB_TOP_ab_Gen3,ZR_Standard;
BO_TX_BU_ 2527679653 :Gateway,Gateway_PAG;
BO_TX_BU_ 2589283974 :Gateway,Gateway_PAG;
BO_TX_BU_ 159 :Gateway,Gateway_PAG;
BO_TX_BU_ 981 :Gateway,Gateway_PAG;
CM_ BO_ 1712 "D4 und B8-PA

1:1 LIN-CAN Botschaft, nur bei Kl.15 EIN gesendet";
CM_ BO_ 1505 "ab MQB 7.3";
CM_ BO_ 779 "MQB";
CM_ BO_ 159 "C7 und B8

Zykluszeit 10ms zyklisch";

CM_ SG_ 2589283621 KL_ACmax_Aktiv "Funktion ACmax durch Kundeneingriff aktiviert";
CM_ SG_ 2589283621 KL_Defrost_Aktiv "Funktion Defrost durch Kundeneingriff aktiviert";
CM_ SG_ 2589283621 KL_ECO_Aktiv "Funktion Eco durch Kundeneingriff aktiviert";
CM_ SG_ 2589283621 KL_ECO_PRO_Aktiv "Funktion ECO-PRO durch Kundeneingriff aktiviert";
CM_ SG_ 2589283621 KL_Eps_Innen "mittlerer Wert der Klima Regelabweichung";
CM_ SG_ 2589283621 KL_FlHz_Soll_HL "Sollwertvorgabe für Flächenheizung hinten links";
CM_ SG_ 2589283621 KL_FlHz_Soll_HR "Sollwertvorgabe für Flächenheizung hinten rechts";
CM_ SG_ 2589283621 KL_FlHz_Soll_VL "Sollwertvorgabe für Flächenheizung vorne links";
CM_ SG_ 2589283621 KL_FlHz_Soll_VR "Sollwertvorgabe für Flächenheizung vorne rechts";
CM_ SG_ 2589283621 KL_Kundeneingriff_Geblaese "Manueller Kundeneingriff in die Geblaeseregelung";
CM_ SG_ 2589283621 KL_NV_Energie_Anf "Benötigte Energie (12V) für die Erweiterte Vorkonditionierung";
CM_ SG_ 2589283621 KL_QBit_Sonnenintensitaet "Gültigkeitsbit für Signal KL_Sonenintensität
Gesetzt bei Ersatzwert, Init oder Fehler.";
CM_ SG_ 2589283621 KL_Sonnenintensitaet "gemittelte eingestrahlte Leistung in W/m2";
CM_ SG_ 2589283621 KL_Status_Klimastil "Signal für aktuelles Programm des KBT";
CM_ SG_ 2589283621 KL_Thermischer_Bedarf "Temperierungsbedarf zur Innenraumklimatisierung";
CM_ SG_ 2589283621 KL_Umluft_Connect_status "Umluft Status zum Backend Server";
CM_ SG_ 2589283621 KL_ZR_Anforderung "Anforderung an MIB die Displays zu aktivieren";

CM_ SG_ 992 KL_Fehler_Fussraum_Klappen "Fehler in den Fußraumklappen werden gemeldet";
CM_ SG_ 992 KL_Fehler_Temp_Klappen "Fehler in den Temperaturklappen werden gemeldet";
CM_ SG_ 992 KL_Fehler_Temp_MA_Klappen "Fehler in den MA-Klappen werden gemeldet";
CM_ SG_ 992 KL_Fehler_Umluft "Status Umluftklappe";
CM_ SG_ 992 KL_Fond_Absperrventil "Absperrventil";
CM_ SG_ 992 KL_Fond_Fuss_Temp_hl "Fussraumtemperatur hinten links";
CM_ SG_ 992 KL_Fond_Fuss_Temp_hr "Fussraumtemperatur hinten rechts";
CM_ SG_ 992 KL_Fond_KD_Fehler "Status Kundendienstfehlerspeichereinträge

";
CM_ SG_ 992 KL_MA_Temp_hl "Mannanstroemer hinten links Temperatur";
CM_ SG_ 992 KL_MA_Temp_hr "Mannanstroemer hinten rechts Temperatur";
CM_ SG_ 992 KL_RAB "Risiko-Abschätzungs- und Bewertungs-Bit";
CM_ SG_ 992 KL_SH_Soll_hl "Einstellung Sitzheizung hinten links (0...6)";
CM_ SG_ 992 KL_SH_Soll_hr "Einstellung Sitzheizung hinten rechts (0...6)";
CM_ SG_ 992 KL_SIH_Takt_hl "Ein-Aus Taktung Sitzheizung hinten links";
CM_ SG_ 992 KL_SIH_Takt_hr "Ein-Aus Taktung Sitzheizung hinten rechts";
CM_ SG_ 992 KL_SL_Soll_hl "Einstellung Sitzlüftung hinten links (0...6)";
CM_ SG_ 992 KL_SL_Soll_hr "Einstellung Sitzlüftung hinten rechts (0...6)";

CM_ SG_ 1712 FS_Luftfeuchte_rel "gemessene relative Luftfeuchte";
CM_ SG_ 1712 FS_ResponseError "siehe LIN2.0-Specification
(Darf nicht über ein Fehlergueltigkeitsbit abgesichtert werden!)";
CM_ SG_ 1712 FS_Taupunkt "berechneter Taupunkt";
CM_ SG_ 1712 FS_Temp_Scheibe "gemessene Frontscheibentemperatur";
CM_ SG_ 1712 FS_Temp_Sensor "gemessene Sensortemperatur";

CM_ SG_ 1505 BCM1_Aussen_Temp_ungef "ungefilterter Wert des Aussentemperatursensors
";
CM_ SG_ 1505 BCM1_FStatus_Aussentemp_ungef "Fehlerstatus für Aussentemperatur (Kombianzeige)";
CM_ SG_ 1505 BCM1_Kompressorstrom_ist "IST-Strom vom Klima-Kompressor";
CM_ SG_ 1505 BCM1_OBD_FStatus_ATemp "Fehlerstatus Umgebungstemperatursensor (OBD relevanter Sensor)
";
CM_ SG_ 1505 BCM1_PTC_stufig_Status "Status des BCM1-Heizverbrauchers PTC (stufig)";
CM_ SG_ 1505 BCM_Heizungsabsperrventil_Status "Das Signal beschreibt den Zustand des Heizungsabsperrventils, welches als Portexpander vom BCM1 elektrisch angesteuert wird.";
CM_ SG_ 1505 BCM_Heizungspumpe_Status "Das Signal beschreibt den Zustand der Heizungspumpe, welche als Portexpander vom BCM1 elektrisch angesteuert wird.";
CM_ SG_ 1505 BCM_Kompressorkupplung_Status "Das Signal beschreibt den Zustand der Klimakompressorkupplung, welche als Portexpander vom BCM1 elektrisch angesteuert wird.";

CM_ SG_ 605 KLR_01_BZ "Botschaftszähler
Botschaft asynchron geroutet. Zählerwert kann springen.";
CM_ SG_ 605 KLR_01_CRC "'Berechnung siehe Lastenheft 'End-to-End Kommunikationsabsicherung''

Endwerte siehe Begleitdokument 'S-PDU Kennungsfolgen'";
CM_ SG_ 605 KLR_Fehler "Fehler im KLR System";
CM_ SG_ 605 KLR_Fehler_Codierung "Erkennung eines Fehlers in der Codierung der Datensatzauswahl im KLR";
CM_ SG_ 605 KLR_Lokalaktiv "Zeigt an ob das SG nach Klemme15 AUS und nach entsprechender MAX Aktivzeit noch aktiv war";
CM_ SG_ 605 KLR_ResponseError "siehe LIN2.0-Specification
(Darf nicht über ein Fehlergueltigkeitsbit abgesichtert werden!)";
CM_ SG_ 605 KLR_Touchauswertung "Touchauswertung der KLR-Elektronik";
CM_ SG_ 605 KLR_Touchintensitaet_1 "Diskreter Wert der Touchintensität von 0 bis 250 für Sensor 1";
CM_ SG_ 605 KLR_Touchintensitaet_2 "Diskreter Wert der Touchintensität von 0 bis 250 für Sensor 2";
CM_ SG_ 605 KLR_Touchintensitaet_3 "Diskreter Wert der Touchintensität von 0 bis 250 für Sensor 3";

CM_ SG_ 2549088398 BedienDisp_vo_Abschaltstufe "Funktionseinschränkung aufgrund aktiver Abschaltstufe";
CM_ SG_ 2549088398 BedienDisp_vo_KD_Fehler "Status Kundendienstfehlerspeichereinträge";
CM_ SG_ 2549088398 BedienDisp_vo_KompSchutz "Funktionseinschränkung aufgrund Komponentenschutz aktiv";
CM_ SG_ 2549088398 BedienDisp_vo_Nachlauftyp "Abgebildet wird die von der Hardware vorgegebene Möglichkeit, die Kommunikation nach Klemme 15 = AUS aufrecht zu erhalten. Es wird ein Init-Wert gesendet.
0 = Kommunikation nur bei KL15=EIN (kein Nachlauf, nicht weckfähig)
1 = Kommunikation nach KL15=AU";
CM_ SG_ 2549088398 BedienDisp_vo_SNI "Das Signal beinhaltet den Source Node Identifier (Knotenadresse, die auch in der Abbildungsvorschrift zur CAN-ID für die NM-High Botschaft verwendet wird).";
CM_ SG_ 2549088398 BedienDisp_vo_Transport_Mode "Funktionseinschränkung aufgrund aktivem Transport Mode und/oder Transport Schutz";
CM_ SG_ 2549088398 KN_BedienDisp_v_BusKnockOut "Ausgabe des BusKnockout-Status in der Knotenbotschaft";
CM_ SG_ 2549088398 KN_BedienDisp_v_BusKnockOutTimer "Ausgabe des BusKnockOut-Timer in der Knotenbotschaft";
CM_ SG_ 2549088398 KN_BedienDisp_v_ECUKnockOut "Ausgabe des ECUKnockout-Status in der Knotenbotschaft";
CM_ SG_ 2549088398 KN_BedienDisp_v_ECUKnockOutTimer "Ausgabe des ECUKnockOut-Timer in der Knotenbotschaft";
CM_ SG_ 2549088398 NM_BedienDisp_vo_Wakeup "enthält die Weckursache; stehen mehrere Weckursachen parallel an, dann muss der kleinste Wert übertragen werden";
CM_ SG_ 2549088398 NMH_BedienDisp_vo_Lokalaktiv "Zeigt an ob das SG nach Klemme15 AUS und nach entsprechender MAX Aktivzeit noch aktiv war";
CM_ SG_ 2549088398 NMH_BedienDisp_vo_Subsystemaktiv "Zeigt an ob ein Subsystem des SGs nach Klemme15 AUS und nach entsprechender MAX Aktivzeit noch aktiv war";

CM_ SG_ 2549088403 BedienSG_hi_Abschaltstufe "Funktionseinschränkung aufgrund aktiver Abschaltstufe";
CM_ SG_ 2549088403 BedienSG_hi_KD_Fehler "Status Kundendienstfehlerspeichereinträge";
CM_ SG_ 2549088403 BedienSG_hi_KompSchutz "Funktionseinschränkung aufgrund Komponentenschutz aktiv";
CM_ SG_ 2549088403 BedienSG_hi_Nachlauftyp "Abgebildet wird die von der Hardware vorgegebene Möglichkeit, die Kommunikation nach Klemme 15 = AUS aufrecht zu erhalten. Es wird ein Init-Wert gesendet.
0 = Kommunikation nur bei KL15=EIN (kein Nachlauf, nicht weckfähig)
1 = Kommunikation nach KL15=AU";
CM_ SG_ 2549088403 BedienSG_hi_SNI "Das Signal beinhaltet den Source Node Identifier (Knotenadresse, die auch in der Abbildungsvorschrift zur CAN-ID für die NM-High Botschaft verwendet wird).";
CM_ SG_ 2549088403 BedienSG_hi_Transport_Mode "Funktionseinschränkung aufgrund aktivem Transport Mode und/oder Transport Schutz";
CM_ SG_ 2549088403 KN_BedienSG_hi_BusKnockOut "Ausgabe des BusKnockout-Status in der Knotenbotschaft";
CM_ SG_ 2549088403 KN_BedienSG_hi_BusKnockOutTimer "Ausgabe des BusKnockOut-Timer in der Knotenbotschaft";
CM_ SG_ 2549088403 KN_BedienSG_hi_ECUKnockOut "Ausgabe des ECUKnockout-Status in der Knotenbotschaft";
CM_ SG_ 2549088403 KN_BedienSG_hi_ECUKnockOutTimer "Ausgabe des ECUKnockOut-Timer in der Knotenbotschaft";
CM_ SG_ 2549088403 NMH_BedienSG_hi_Lokalaktiv "Zeigt an ob das SG nach Klemme15 AUS und nach entsprechender MAX Aktivzeit noch aktiv war";
CM_ SG_ 2549088403 NMH_BedienSG_hi_Subsystemaktiv "Zeigt an ob ein Subsystem des SGs nach Klemme15 AUS und nach entsprechender MAX Aktivzeit noch aktiv war";
CM_ SG_ 2549088403 NMH_BedienSG_hi_Wakeup "enthält die Weckursache; stehen mehrere Weckursachen parallel an, dann muss der kleinste Wert übertragen werden";

CM_ SG_ 2549088442 DDA_Abschaltstufe "Funktionseinschränkung aufgrund aktiver Abschaltstufe";
CM_ SG_ 2549088442 DDA_KD_Fehler "Bei gesetztem Bit ist mindestens ein Kundendienstfehler eingetragen";
CM_ SG_ 2549088442 DDA_KompSchutz "Funktionseinschränkung aufgrund Komponentenschutz aktiv";
CM_ SG_ 2549088442 DDA_Nachlauftyp "Abgebildet wird die von der Hardware vorgegebene Möglichkeit, die Kommunikation nach Klemme 15 = AUS aufrecht zu erhalten. Es wird ein Init-Wert gesendet.
0 = Kommunikation nur bei KL15=EIN (kein Nachlauf, nicht weckfähig)
1 = Kommunikation nach KL15=AU";
CM_ SG_ 2549088442 DDA_SNI "Das Signal beinhaltet den Source Node Identifier (Knotenadresse, die auch in der Abbildungsvorschrift zur CAN-ID für die NM-High Botschaft verwendet wird).";
CM_ SG_ 2549088442 DDA_Transport_Mode "Funktionseinschränkung aufgrund aktivem Transport Mode und/oder Transport Schutz";
CM_ SG_ 2549088442 KN_DDA_BusKnockOutTimer "Ausgabe des BusKnockOut-Timer in der Knotenbotschaft";
CM_ SG_ 2549088442 NM_DDA_Lokalaktiv "Zeigt an, ob das SG nach Klemme15 AUS noch aktiv war. LAH.DUM.907.T.1_Abschaltungen Ruhestrommgm MLBevo";
CM_ SG_ 2549088442 NM_DDA_Wakeup "enthält die Weckursache; stehen mehrere Weckursachen parallel an, dann muss der kleinste Wert übertragen werden";

CM_ SG_ 2549088272 Gateway_Abschaltstufe "Funktionseinschränkung aufgrund aktiver Abschaltstufe";
CM_ SG_ 2549088272 Gateway_KompSchutz "Funktionseinschränkung aufgrund Komponentenschutz aktiv";
CM_ SG_ 2549088272 Gateway_Matrix_Generation "Signal gibt an welche Matrix-Generation umgesetzt ist";
CM_ SG_ 2549088272 Gateway_Matrix_Version "Signal gibt an welche Matrix-Version des Baukasten umgesetzt ist.
z.B. V.08.xx, das Signal gibt den Wert für xx an";
CM_ SG_ 2549088272 Gateway_Nachlauftyp "Abgebildet wird die von der Hardware vorgegebene Möglichkeit, die Kommunikation nach Klemme 15 = AUS aufrecht zu erhalten. Es wird ein Init-Wert gesendet.";
CM_ SG_ 2549088272 Gateway_SNI "Das Signal beinhaltet den Source Node Identifier (Knotenadresse, die auch in der Abbildungsvorschrift zur CAN-ID für die NM-High Botschaft verwendet wird).";
CM_ SG_ 2549088272 Gateway_Transport_Mode "Funktionseinschränkung aufgrund aktivem Transport Mode und/oder Transport Schutz";
CM_ SG_ 2549088272 GW_KD_Fehler "Kundendienstfehlerbit Gateway zur Anzeige eines im Gateway abgelegten Fehlerspeichereintrages.";
CM_ SG_ 2549088272 NM_Gateway_Lokalaktiv "Zeigt an ob das SG nach Klemme15 AUS und nach entsprechender MAX Aktivzeit noch aktiv war.";
CM_ SG_ 2549088272 NM_Gateway_Subsystemaktiv "Zeigt an ob ein Subsystem des SGs nach Klemme15 AUS und nach entsprechender MAX Aktivzeit noch aktiv war";
CM_ SG_ 2549088272 NM_Gateway_Wakeup "enthält die Weckursache; stehen mehrere Weckursachen parallel an, dann muss der kleinste Wert übertragen werden";

CM_ SG_ 2549088355 GM_Abschaltstufe "Funktionseinschränkung aufgrund aktiver Abschaltstufe";
CM_ SG_ 2549088355 GM_KD_Fehler "Bei gesetztem Bit ist mindestens ein Kundendienstfehler eingetragen
";
CM_ SG_ 2549088355 GM_KompSchutz "Funktionseinschränkung aufgrund Komponentenschutz aktiv";
CM_ SG_ 2549088355 GM_Lokalaktiv "Zeigt an ob das SG nach Klemme15 AUS und nach entsprechender MAX Aktivzeit noch aktiv war";
CM_ SG_ 2549088355 GM_Nachlauftyp "Abgebildet wird die von der Hardware vorgegebene Möglichkeit, die Kommunikation nach Klemme 15 = AUS aufrecht zu erhalten. Es wird ein Init-Wert gesendet.
0 = Kommunikation nur bei KL15=EIN (kein Nachlauf, nicht weckfähig)
1 = Kommunikation nach KL15=AU";
CM_ SG_ 2549088355 GM_SNI "Das Signal beinhaltet den Source Node Identifier (Knotenadresse, die auch in der Abbildungsvorschrift zur CAN-ID für die NM-High Botschaft verwendet wird).";
CM_ SG_ 2549088355 GM_Subsystemaktiv "Zeigt an ob ein Subsystem des SGs nach Klemme15 AUS und nach entsprechender MAX Aktivzeit noch aktiv war";
CM_ SG_ 2549088355 GM_Transport_Mode "Funktionseinschränkung aufgrund aktivem Transport Mode und/oder Transport Schutz";
CM_ SG_ 2549088355 NM_GM_Wakeup "enthält die Weckursache; stehen mehrere Weckursachen parallel an, dann muss der kleinste Wert übertragen werden";

CM_ SG_ 2549088371 Info_El_Abschaltstufe "Funktionseinschränkung aufgrund aktiver Abschaltstufe";
CM_ SG_ 2549088371 Info_El_KD_Fehler "Bei gesetztem Bit ist mindestens ein Kundendienstfehler eingetragen";
CM_ SG_ 2549088371 Info_El_KompSchutz "Funktionseinschränkung aufgrund Komponentenschutz aktiv";
CM_ SG_ 2549088371 Info_El_Nachlauftyp "Abgebildet wird die von der Hardware vorgegebene Möglichkeit, die Kommunikation nach Klemme 15 = AUS aufrecht zu erhalten. Es wird ein Init-Wert gesendet.";
CM_ SG_ 2549088371 Info_El_SNI "Das Signal beinhaltet den Source Node Identifier (Knotenadresse, die auch in der Abbildungsvorschrift zur CAN-ID für die NM-High Botschaft verwendet wird).";
CM_ SG_ 2549088371 Info_El_Transport_Mode "Funktionseinschränkung aufgrund aktivem Transport Mode und/oder Transport Schutz";
CM_ SG_ 2549088371 KN_Info_El_BusKnockOutTimer "Ausgabe des BusKnockOut-Timer";
CM_ SG_ 2549088371 NM_Info_El_Lokalaktiv "Zeigt an ob das SG nach Klemme15 AUS und nach entsprechender MAX Aktivzeit noch aktiv war.";
CM_ SG_ 2549088371 NM_Info_El_Subsystemaktiv "Zeigt an ob ein Subsystem des SGs nach Klemme15 AUS und nach entsprechender MAX Aktivzeit noch aktiv war";
CM_ SG_ 2549088371 NM_Info_El_Wakeup "enthält die Weckursache; stehen mehrere Weckursachen parallel an, dann muss der kleinste Wert übertragen werden";

CM_ SG_ 2549088258 NM_Sekundaer_02_Lokalaktiv "Zeigt an ob das SG nach Klemme15 AUS und nach entsprechender MAX Aktivzeit noch aktiv war";
CM_ SG_ 2549088258 NM_Sekundaer_02_Subsystemaktiv "Zeigt an ob ein Subsystem des SGs nach Klemme15 AUS und nach entsprechender MAX Aktivzeit noch aktiv war";
CM_ SG_ 2549088258 NM_Sekundaer_02_Wakeup "enthält die Weckursache; stehen mehrere Weckursachen parallel an, dann muss der kleinste Wert übertragen werden";
CM_ SG_ 2549088258 Sekundaer_02_Abschaltstufe "Funktionseinschränkung aufgrund aktiver Abschaltstufe";
CM_ SG_ 2549088258 Sekundaer_02_KD_Fehler "Status Kundendienst-Fehlerspeicher";
CM_ SG_ 2549088258 Sekundaer_02_KompSchutz "Funktionseinschränkung aufgrund Komponentenschutz aktiv";
CM_ SG_ 2549088258 Sekundaer_02_Nachlauftyp "Abgebildet wird die von der Hardware vorgegebene Möglichkeit, die Kommunikation nach Klemme 15 = AUS aufrecht zu erhalten. Es wird ein Init-Wert gesendet.
0 = Kommunikation nur bei KL15=EIN (kein Nachlauf, nicht weckfähig)
1 = Kommunikation nach KL15=AU";
CM_ SG_ 2549088258 Sekundaer_02_SNI "Das Signal beinhaltet den Source Node Identifier (Knotenadresse, die auch in der Abbildungsvorschrift zur CAN-ID für die NM-High Botschaft verwendet wird).";
CM_ SG_ 2549088258 Sekundaer_02_Transport_Mode "Funktionseinschränkung aufgrund aktivem Transport Mode und/oder Transport Schutz";

CM_ SG_ 779 KBI_ABS_Lampe "ABS-Sicherheits-Lampe wurde eingeschaltet.";
CM_ SG_ 779 KBI_Airbag_Lampe "Airbag Sicherheits-Lampe wurde eingeschaltet ";
CM_ SG_ 779 KBI_angez_Geschw "Im Tacho angezeigte Geschwindigkeit inklusive der Voreilung

";
CM_ SG_ 779 KBI_Anzeigefehler_NV "Über dieses Signal teilt das Kombiinstrument dem Nightvision-Steuergerät mit, dass ein Fehler vom Kombiinstrument diagnostiziert wurde, der zur Abschaltung der Nightvision-Funktion führen muss.";
CM_ SG_ 779 KBI_Anzeigefehler_SWA "Signal bezieht sich nur auf die SWA-Lampe, Vorhalt für Kombis mit SWA-Lampe. ";
CM_ SG_ 779 KBI_Anzeigestatus_ACC "Status der ACC-Anzeige im nicht permanenten Displaybereich";
CM_ SG_ 779 KBI_Anzeigestatus_GRA "Anzeigestatus der GRA High Wunschgeschwindigkeitsanzeige im Kombiinstrument.
Bei VW bedeutet 'nicht vorhanden' GRA-low fähig (LED immer verbaut).
0 = nicht vorhanden
1 = Wunschgeschwindigkeits-Anzeigemöglichkeit vorhanden
2 = reserviert
3 = Fehler (B";
CM_ SG_ 779 KBI_Anzeigestatus_LIM "Anzeigestatus der Speedlimiter Wunschgeschwindigkeitsanzeige im Kombiinstrument (permanenter Anzeigebereich)
0 = nicht vorhanden
1 = Wunschgeschwindigkeits-Anzeigemöglichkeit vorhanden
2 = reserviert
3 = Fehler (Botschaftsüberwachung, Timeout, Akustik";
CM_ SG_ 779 KBI_ARA_in_Anzeige "Anzeige von ARA im Kombi aktiv";
CM_ SG_ 779 KBI_BKL_Lampe "Sicherheits-Lampe Bremskontrolle wurde eingeschaltet;
";
CM_ SG_ 779 KBI_Einheit_Tacho "Information, ob es sich um Meilen- oder Kmh-Kombi handelt, Einheit des Tachos entspricht dem Zifferblatt, Grösse ist nicht veränderlich";
CM_ SG_ 779 KBI_ESP_Lampe "ESP-Sicherheits-Lampe wurde eingeschaltet ";
CM_ SG_ 779 KBI_Fehler_Anzeige_ACC "Rückmeldung an ACC, dass mindestens eine der ACC-relevanten Anzeigen -rote Fahrerübernahme, Mitteldisplay, Gong - fehlerhaft sind.";
CM_ SG_ 779 KBI_GRA_Hauptschalter "Hauptschalter der Fahrerassistenzsysteme basierend auf dem FAS-Menu im Kombi.";
CM_ SG_ 779 KBI_Handbremse "Handbremsen-Information vom Kombi.
Das Signal bezieht sich ausschließlich auf den Zustand der konventionellen Handbremse.";
CM_ SG_ 779 KBI_im_Stellgliedtest "Kombi im Stellgliedtest, Signal muss eingelesen werden, um Fehlfunktion aufgrund der Bewegung der Stellglieder (Drehzahlmesser, Tacho) des Kombis zu verhindern";
CM_ SG_ 779 KBI_Konsistenz_ACC "Rückmeldung an ACC, dass die Botschaften zur Ansteuerung von Anzeigen nicht bzw. nicht konsistent empfangen wurden (Timeout-, BZ-, CHK- und DLC-Fehler)                                                                                                        ";
CM_ SG_ 779 KBI_Lenkung_Lampe "Sicherheits-Lampe der Lenkung (Lenkhilfe EPS, Audi-Dynamic-Steering ...) wurde eingeschaltet.

0x0 = Lenkungs-Lampe aus
0x1 = Lenkungs-Lampe ein";
CM_ SG_ 779 KBI_MFA_v_Einheit_01 "Einheit der Geschwindigkeit, die vom Fahrer im Car-Menü gewählt wurde. Veränderliche Grösse, im Gegensatz zur Einheit des Tachokranzes.";
CM_ SG_ 779 KBI_NV_in_Anzeige "Das Bit gibt dem NV die Information, ob NV-Bild im Kombi in der Anzeige ist. (Information ist notwendig um Kontrasverstellungen nur dann zuzulassen, wenn der Fahrer das Feedback über das  Kombidisplay bekommt.)";
CM_ SG_ 779 KBI_PLA_in_Anzeige "Das Signal wird als aktive Rückmeldung genutzt, ob die Info des PLA im Kombi angezeigt wird. Wenn nach Anforderung des Displays das Signal zweimal auf 0 ist, wird der Parkvorgang abgebrochen.
Ein Kombi, dass PLA Anzeige nicht unterstützt, schickt dauerha";
CM_ SG_ 779 KBI_SILA_gueltig "Rückmeldeinformation (Bit 1-6) ist gültig";
CM_ SG_ 779 KBI_Systemstatus "Signalisiert erkannte FuSi-relevante Fehler im Kombi
(keinen Ausfall der Akustik oder des Displays)";
CM_ SG_ 779 KBI_Tankwarnung "Fahrer wird gewarnt, dass er den Reservebereich erreicht hat. Fzg.spezifische Warnschwelle";
CM_ SG_ 779 KBI_Tankwarnung_ungueltig "Validiert den Inhalt des Signales KBI_Tankwarnung";
CM_ SG_ 779 KBI_Taster_Fahrwerk "Betätigung Taster 'Fahrwerk' im Kombi";
CM_ SG_ 779 KBI_Taster_Lift "Betätigung Taster 'Lift' im Kombi J1 zur Verarbeitung im Porsche EFP Steuergerät";
CM_ SG_ 779 KBI_V_Digital "Ausgabe der im Kombi angezeigten digitalen Geschwindigkeit.

Einheit ist im KBI_MFA_v_Einheit_01 definiert";
CM_ SG_ 779 KBI_Vorglueh_System_Lampe "Rückmeldung der Vorglühlampe bzw. Motor Systemlampe (MO_Systemlampe) an den Motor (bei Diesel und Otto!). Hardwaremässig gleiche LED im Kombi (EPC- oder Glühwendel), Unterscheidung nur über Ziffernblatt.";

CM_ SG_ 1719 KBI_aktive_Laengsfunktion "Auswahl, der vom Fahrer gewünschten Laengsregelfunktion";
CM_ SG_ 1719 KBI_FoD_PopUP_Quittiert "Angezeigte FoD-Warnung im Kombi wurde vom Fahrer quittiert; 
Signal wird für die Dauer von 2 Sekunden gesendet";
CM_ SG_ 1719 KBI_FStatus_Tank "Signal wird gesetzt:

a) Während der Fehlerentprellzeit (20 s Entprellung)

b) Bei erkanntem Fehler wird der Tankinhalt während der laufenden KL15-Phase über den 
    Verbrauch zurückgerechnet. In dieser Zeit ist das Bit ebenfalls gesetzt. Nach einem";
CM_ SG_ 1719 KBI_GRA_im_ACC "Gibt den vom Fahrer ausgewählten Modus (ACC oder GRA_im_ACC) an.";
CM_ SG_ 1719 KBI_Inhalt_Tank "Restmenge 2 bzw. 2,5l nicht auflösbar

";
CM_ SG_ 1719 KBI_Kilometerstand "Fehler wird ausgegeben, falls Kilometerstand nicht restaurierbar
";
CM_ SG_ 1719 KBI_LVDS_Lock "Dient zur Synchronisation der Anzeige zwischen Kombi und ZR";
CM_ SG_ 1719 KBI_Oelwechsel_durchgefuehrt "Nach einen Ölwechsel (Service) ist die Ethanol Warmfahrwarnung zu unterdrücken.";
CM_ SG_ 1719 KBI_QBit_Aussen_Temp_gef "0x0 = gültiger Wert
0x1 = Ersatz-, Init- oder Fehlerwert";
CM_ SG_ 1719 KBI_RDK_Kalibrier_Anf "Bei gesetztem Bit soll die RDK die aktuellen Istdrücke zu Solldrücken übernehmen (nur bei Nichtverbau einer Headunit erforderlich).";
CM_ SG_ 1719 KBI_Reserve_Warnung_Sek "Signalisiert die Reservewarnung für die Energiespeicher CNG, LPG, HV-Batterie.
Fahrer wird gewarnt, dass er den Reservebereich erreicht hat. Fzg.spezifische Warnschwelle.";
CM_ SG_ 1719 KBI_Standzeit_02 "Zähler welcher die Standzeit des Motors wiedergibt.
Das Signal beschreibt den Anteil der Motor-Standzeit zwischen Zündung aus und nächstem Motorstart.";
CM_ SG_ 1719 KBI_TA_gewaehlt_Fahrer "Rueckmeldung, dass der TA vom Fahrer gewaehlt wurde";

CM_ SG_ 1720 KBI_BCmE_aktiv "Anzeige BCmE aktiv (BCmE-Screen oder Einsparhinweis in der Anzeige)";
CM_ SG_ 1720 KBI_GAP_Warn_Zeit_abgelaufen "Die Zeit, z.B. 1460 Tage, bis zur finalen Warnstufe der Gasanlagenprüfung wurde berechnet. Berechnung erfolgt auf Basis der aktuellen Uhrzeit mit einem Tageszähler. Keine Berechnung des Zählers bei Kl.30 AUS.";
CM_ SG_ 1720 KBI_Max_Tankinhalt "Mitteilung des maximalen Tankinhalts an das Reichweitenmodul";
CM_ SG_ 1720 KBI_Nachtanken_erkannt "Statusinformation Nachtankmodus";
CM_ SG_ 1720 KBI_Quittierung_cAQP "Quittierungsbestätigung vom Fahrer für Funktion cAQP";
CM_ SG_ 1720 KBI_Quittierung_Naesse "Quittierungsbestätigung vom Fahrer";
CM_ SG_ 1720 KBI_Reifenumfang "Mittlerer Radumfang aus der K-Zahl gerechnet in Millimeter.  Byte 2 Bit 5,4 reserviert, Byte 2 Bit 3..0 und Byte 1 Bit 7..0; Wertebereich 0..4096 mm
";
CM_ SG_ 1720 KBI_Reifenumfang_Sekundaer "Fahrzeuge mit unterschiedlichen Reifenumfängen Vorderachse / Hinterachse:

Primärachse: KBI_Reifenumfang
Sekundärachse: KBI_Reifenumfang_Sekundaer
";
CM_ SG_ 1720 KBI_Sparhinweis_quittiert "angezeigter Sparhinweis ist quittiert. Signal wird nach zwei Sendebotschaften wieder auf '0' gesetzt.";
CM_ SG_ 1720 KBI_Tankfuellstand_Prozent "Tankfüllstand in %";
CM_ SG_ 1720 KBI_Tankinhalt_hochaufl "angezeigter Tankinhalt hochauflösend zur Restreichweitenberechnung";
CM_ SG_ 1720 KBI_Variante "Zeigt an ob es sich um ein konventionelles Zeiger-Kombiinstrument handelt oder um eine Volldisplay-Kombiinstrument";
CM_ SG_ 1720 KBI_Variante_USA "In diesem Signal wird die HW-Variante des Kombis ausgegeben, ACC plausibilisiert auf dieses Signal hin seine US-Codierung";

CM_ SG_ 1724 KBI_Insp_dis "Distanz bis zur Inspektion:

Einheitenloser Wert. Einheit im Signal 'KBI_Inspection_distance_unit'";
CM_ SG_ 1724 KBI_Insp_dis_status "Einheit Distanz bis zur Inspektion:";
CM_ SG_ 1724 KBI_Insp_dis_unit "Einheit Distanz bis zur Inspektion:";
CM_ SG_ 1724 KBI_Insp_time "Zeit bis zur Inspektion:

Angabe in Tagen";
CM_ SG_ 1724 KBI_Insp_time_status "Inspektionsstatus Zeit:";
CM_ SG_ 1724 KBI_Oil_dis "Distanz bis zum Ölwechsel:

Einheitenloser Wert. Einheit im Signal 'KBI_Oil_distance_unit'";
CM_ SG_ 1724 KBI_Oil_dis_status "Ölwechselstatus Distanz:";
CM_ SG_ 1724 KBI_Oil_dis_unit "Einheit Distanz bis zum Ölwechsel:";
CM_ SG_ 1724 KBI_Oil_time "Zeit bis zum Ölwechsel:

Angabe in Tagen";
CM_ SG_ 1724 KBI_Oil_time_status "Ölwechselstatus Zeit:";
CM_ SG_ 1724 KBI_Warnung_ID "ID, die einer Warnung im Kombi entspricht und entsprechend der Anzeige im Kombi gesetzt wird.";

CM_ SG_ 2527679638 KBI_GZeit_HSek "Stoppuhr-Gesamtzeit laufend - 1/100 Sekunden


PAG-Plattform:
Sendeart: Cyclic
Zykluszeit: 20ms

MLBevo_Konzern:
Sendeart: OnChange
Zykluszeit: 1000ms
Inhibitzeit: 100ms";
CM_ SG_ 2527679638 KBI_GZeit_Min "Stoppuhr-Gesamtzeit laufend Minuten

PAG-Plattform:
Sendeart: Cyclic
Zykluszeit: 20ms

MLBevo_Konzern:
Sendeart: OnChange
Zykluszeit: 1000ms
Inhibitzeit: 100ms";
CM_ SG_ 2527679638 KBI_GZeit_Sek "Stoppuhr-Gesamtzeit laufend - Sekunden

PAG-Plattform:
Sendeart: Cyclic
Zykluszeit: 20ms

MLBevo_Konzern:
Sendeart: OnChange
Zykluszeit: 1000ms
Inhibitzeit: 100ms";
CM_ SG_ 2527679638 KBI_GZeit_Std "Stoppuhr-Gesamtzeit laufend - Stunden

PAG-Plattform:
Sendeart: Cyclic
Zykluszeit: 20ms

MLBevo_Konzern:
Sendeart: OnChange
Zykluszeit: 1000ms
Inhibitzeit: 100ms
";
CM_ SG_ 2527679638 KBI_RZ_Nr "Nr. der aktuellen Runde

PAG-Plattform:
Sendeart: Cyclic
Zykluszeit: 250ms

MLBevo_Konzern:
Sendeart: OnChange
Zykluszeit: 1000ms
Inhibitzeit: 100ms";
CM_ SG_ 2527679638 KBI_RZeit_HSek "Stoppuhr -Rundenzeit - 1/100 Sekunden

PAG-Plattform:
Sendeart: Cyclic
Zykluszeit: 250ms

MLBevo_Konzern:
Sendeart: OnChange
Zykluszeit: 1000ms
Inhibitzeit: 100ms
";
CM_ SG_ 2527679638 KBI_RZeit_Min "Stoppuhr - Rundenzeit - Minuten

PAG-Plattform:
Sendeart: Cyclic
Zykluszeit: 250ms

MLBevo_Konzern:
Sendeart: OnChange
Zykluszeit: 1000ms
Inhibitzeit: 100ms
";
CM_ SG_ 2527679638 KBI_RZeit_Sek "Stoppuhr - Rundenzeit - Sekunden

PAG-Plattform:
Sendeart: Cyclic
Zykluszeit: 250ms

MLBevo_Konzern:
Sendeart: OnChange
Zykluszeit: 1000ms
Inhibitzeit: 100ms";
CM_ SG_ 2527679638 KBI_RZeit_Std "Stoppuhr - Rundenzeit - Stunden

PAG-Plattform:
Sendeart: Cyclic
Zykluszeit: 250ms

MLBevo_Konzern:
Sendeart: OnChange
Zykluszeit: 1000ms
Inhibitzeit: 100ms
";
CM_ SG_ 2527679638 KBI_Status_StoppUhr "This signal contains the status of the laptimer.";

CM_ SG_ 2527679639 KBI_Jokerkey "Betaetigung KBI Jokertaste";
CM_ SG_ 2527679639 KBI_RS_Druck_uebernehmen "Druck für Rundstreckenmodus übernehmen";
CM_ SG_ 2527679639 KBI_RS_Druckauswahl_Aktiv "Menue Druckauswahl aktiv";
CM_ SG_ 2527679639 KBI_RS_Mode_fortsetzen "Kombi fordert Fortsetzung des Rundstreckenmodus";
CM_ SG_ 2527679639 KBI_Rundstreckenmodus "Rundstreckenmodus Anforderung";
CM_ SG_ 2527679639 KBI_Weg_Zaehler "Inkrementaler Zähler des Kombis

PAG-Plattform:
Sendeart: Cyclic
Zykluszeit: 100ms

MLBevo_Konzern:
Sendeart: OnChange
Zykluszeit: 1000ms
Inhibitzeit: 100ms
";
CM_ SG_ 2527679639 KBI_Weg_Zaehler_F "Fehlerbit für den Inkrementalzähler Weg

PAG-Plattform:
Sendeart: Cyclic
Zykluszeit: 100ms

MLBevo_Konzern:
Sendeart: OnChange
Zykluszeit: 1000ms
Inhibitzeit: 100ms";

CM_ SG_ 2527679656 KBI_StartupAnimation "Synchronisierung der StartupAnimation zwischen Kombi und MMI.";

CM_ SG_ 2549875055 KS_AMP_Req_Data "Komponentenschutz (Funktion 01h). Request mit NA des Slaves.";

CM_ SG_ 2550006127 KS_AMP_Resp_Data "Komponentenschutz (Funktion 01h). Response mit eigener NA.";

CM_ SG_ 2549875059 KS_Info_El_Req_Data "Komponentenschutz (Funktion 01h). Request mit NA des Slaves.";

CM_ SG_ 2550006131 KS_Info_El_Resp_Data "Komponentenschutz (Funktion 01h). Response mit eigener NA.";

CM_ SG_ 2549875056 KS_Laufwerke_Req_Data "Komponentenschutz (Funktion 01h). Request mit NA des Slaves.";

CM_ SG_ 2550006128 KS_Laufwerke_Resp_Data "Komponentenschutz (Funktion 01h). Response mit eigener NA.";

CM_ SG_ 2549875053 KS_TV_Tuner_Req_Data "Komponentenschutz (Funktion 01h). Request mit NA des Slaves.";

CM_ SG_ 2550006125 KS_TV_Tuner_Resp_Data "Komponentenschutz (Funktion 01h). Response mit eigener NA.";

CM_ SG_ 701 LAE_Beta_confidence "Confidence factor for Beta";
CM_ SG_ 701 LAE_Beta_VZ "Sign of Beta angle";
CM_ SG_ 701 LAE_BetaSlipAngle "Estimated vehicle side slip angle
by LAE controller";
CM_ SG_ 701 LAE_BetaSlipAngle_02 "Estimated side slip angle by LAE controller";
CM_ SG_ 701 LAE_mu "Estimated grip coefficient
unsigned value";
CM_ SG_ 701 LAE_mu_confidence "Confidence factor for estimated grip
unsigned Value";
CM_ SG_ 701 LAE_Vx "Estimated longitudinal vehicle speed (m/s)";
CM_ SG_ 701 LAE_Vx_confidence "Confidence factor for longitudinal vehicle speed";
CM_ SG_ 701 LAE_Vx_VZ "Sign of longitudinal vehicle speed";
CM_ SG_ 701 LAE_Vy "Estimated lateral vehicle speed (m/s)";
CM_ SG_ 701 LAE_Vy_confidence "Confidence factor for lateral vehicle speed";

CM_ SG_ 2527679653 MXB_LAPP_Freigabe "Freigabe des Advertising durch die DDA";
CM_ SG_ 2527679653 MXB_LAPP_Status_FL "Gibt den Aktivierungsstatus des Fernlichts (FL) durch die Licht-App an.";
CM_ SG_ 2527679653 MXB_LAPP_Statuscode "Gibt den Bereitschaftsstatus der Licht-App an.

Der Wert des Signals ergibt sich aus den Stati der fahrzeugspezifischen Vorbedingungen und dient der Licht-App als Grundlage für Anweisungen an den Kunden.";
CM_ SG_ 2527679653 MXB_LAPP_ZR_Sondermodus_Anf "Anforderung des ZR Sondermodus (BT-Abschaltung)";

CM_ SG_ 2463978818 BTM_BrakeSystem_Status "Brake_system_status for Brake temperature estimation function:
includes status of brake disc and fluid overheating and aged fluid status";
CM_ SG_ 2463978818 BTM_BrakeSystem_Text "Brake temperature management text message to be visualized on kombi";
CM_ SG_ 2463978818 BTM_BrakeSystem_Warnlampe "Activation of warning lamp for brake temperature management";
CM_ SG_ 2463978818 LCV_01_BZ "4bit Botschaftszähler, wird mit jeder Sendebotschaft inkrementiert";
CM_ SG_ 2463978818 LCV_01_CRC "Für MLB:
Berechnung siehe Lastenheft 'Kommunikationsabsicherung für FlexRay und CAN'
Ab MQB und MLBevo:
Berechnung siehe Lastenheft 'End-to-End Kommunikationsabsicherung'

Endwerte siehe Begleitdokument 'S-PDU Kennungsfolgen'";
CM_ SG_ 2463978818 LCV_Aero_EngineBay_Cooling "Status of Engine Bay Cooling strategy";
CM_ SG_ 2463978818 LCV_Aero_Front_System_Status "Status of the front active aerodinamic system";
CM_ SG_ 2463978818 LCV_Aero_Perf_Limit "Status of Performance Limiter strategy";
CM_ SG_ 2463978818 LCV_Aero_Perf_Limit_Speed "Speed value for Performance Limiter strategy";
CM_ SG_ 2463978818 LCV_Aero_Rear_System_Status "Status of the rear active aerodinamic system";
CM_ SG_ 2463978818 LCV_BrakeGongTemp "Brake temperature management gong activation";
CM_ SG_ 2463978818 LCV_DR_Systemstatus "Status of Damper Control system";
CM_ SG_ 2463978818 LCV_DR_Text "Pop-Up Text on Kombi for Damper Control";
CM_ SG_ 2463978818 LCV_DR_Warnlampe "Operative and warning lamps on the Kombi for Damper Control";
CM_ SG_ 2463978818 LCV_ESP_Zuschaltung "Zwangsweise Aktivierung ESP-Funktionalität durch die Dämpferregelung, Anforderung erfolgt auch bei Passivtastung.";
CM_ SG_ 2463978818 LCV_HD_offen "Status Heckdeckel";
CM_ SG_ 2463978818 LCV_Lift_Status "Status of Lifting System";
CM_ SG_ 2463978818 LCV_Lift_Text "Pop-Up Text on Kombi for Lifting System";
CM_ SG_ 2463978818 LCV_Lift_Warnlampe_Status "Operative and warning lamps on the Kombi for Lifting System";

CM_ SG_ 2527679780 LCV_Aero_BarMode_Activation "Status of the Aero Bar Mode";
CM_ SG_ 2527679780 LCV_Aero_Button_Default "Default value for aero tuning switch";
CM_ SG_ 2527679780 LCV_Aero_Button_Range "Number of available choices of the Aero switch that shall be active";
CM_ SG_ 2527679780 LCV_Aero_Button_Select "Feedback from LCV to LIMU for button selection of Aero";
CM_ SG_ 2527679780 LCV_Aero_Button_Tunable "Aero Tuning switch active or not";
CM_ SG_ 2527679780 LCV_BarMode_Allowed "Bar Mode button availability";
CM_ SG_ 2527679780 LCV_DR_Button_Default "Default value for damper tuning switch";
CM_ SG_ 2527679780 LCV_DR_Button_Range "Number of available choices of the DC switch that shall be active";
CM_ SG_ 2527679780 LCV_DR_Button_Select "Feedback from LCV to LIMU for button selection of Damper Control";
CM_ SG_ 2527679780 LCV_DR_Button_Tunable "DC Tuning switch active or not";

CM_ SG_ 2463978684 BTM_BrakeDiscTemp_01 "Brake disc temperature 01 estimation.";
CM_ SG_ 2463978684 BTM_BrakeDiscTemp_02 "Brake disc temperature 02 estimation.";
CM_ SG_ 2463978684 BTM_BrakeDiscTemp_03 "Brake disc temperature 03 estimation.";
CM_ SG_ 2463978684 BTM_BrakeDiscTemp_04 "Brake disc temperature 04 estimation.";
CM_ SG_ 2463978684 BTM_BrakeFluidTemp_01 "Brake fluid temperature 01 estimation.";
CM_ SG_ 2463978684 BTM_BrakeFluidTemp_02 "Brake fluid temperature 02 estimation.";
CM_ SG_ 2463978684 BTM_BrakeFluidTemp_03 "Brake fluid temperature 03 estimation.";
CM_ SG_ 2463978684 BTM_BrakeFluidTemp_04 "Brake fluid temperature 04 estimation.";

CM_ SG_ 548 LCV_Aero_Front_Ratio "Front ratio of the aerodynamic load distribution ( value indicates the percentage of front left/right)";
CM_ SG_ 548 LCV_Aero_Long_Ratio "Longitudinal ratio of the aerodynamic load distribution ( value indicates the percentage of rear )";

CM_ SG_ 2589283974 BTM_BrakeDiscColour_01 "Brake disc visualization colour";
CM_ SG_ 2589283974 BTM_BrakeDiscColour_02 "Brake disc visualization colour";
CM_ SG_ 2589283974 BTM_BrakeDiscColour_03 "Brake disc visualization colour";
CM_ SG_ 2589283974 BTM_BrakeDiscColour_04 "Brake disc visualization colour";
CM_ SG_ 2589283974 BTM_BrakeFluidColour_01 "Brake fluid visualization colour";
CM_ SG_ 2589283974 BTM_BrakeFluidColour_02 "Brake fluid visualization colour";
CM_ SG_ 2589283974 BTM_BrakeFluidColour_03 "Brake fluid visualization colour";
CM_ SG_ 2589283974 BTM_BrakeFluidColour_04 "Brake fluid visualization colour";

CM_ SG_ 159 EPS_03_BZ "Botschaft asynchron geroutet. Zählerwert kann springen.";
CM_ SG_ 159 EPS_03_CRC "Für MLB:
'Berechnung siehe Lastenheft 'Kommunikationsabsicherung für FlexRay und CAN''

Ab MQB und MLBevo:
'Berechnung siehe Lastenheft 'End-to-End Kommunikationsabsicherung''

Endwerte siehe Begleitdokument 'S-PDU Kennungsfolgen'";
CM_ SG_ 159 EPS_Berechneter_LW "Berechneter Lenkradwinkel (BLW)
MLB: Ausgabe des berechneten Lenkwinkels mit Geradeauslaufkorrektur aus der Position des Lenkmotors (Absolutwert)
MQB: Ausgabe des berechneten Lenkwinkels aus der Position des Lenkmotors (Absolutwert) und ggf. unter Berüc";
CM_ SG_ 159 EPS_BLW_QBit "beschreibt die Qualität/Vertrauenswürdigkeit des berechneten LW";
CM_ SG_ 159 EPS_DSR_Status_02 "0 DSR deaktiviert;
1 DSR Anforderung nicht ausführbar (ESP Fehlerstatus);
2 Kommunikation zum ESP-SG gestört;
3 EPS bzgl. DSR funktionsbereit;
4 DSR Anforderung abgewiesen;
5 externer Momenteneingriff aktiv;
6 externer Lenkwinkeleingriff aktiv;
7 e";
CM_ SG_ 159 EPS_HCA_Status_02 "beschreibt den Status der HCA-Funktion im EPS-Steuergerät.

Bedeutung der Status-Indices:
0: HCA in der EPS deaktiviert;
1: HCA Anforderung nicht ausführbar (HCA Fehlerstatus, Initialisierung, Ausschaltphase);
2: Kommunikation zum HCA-SG gestört;
3:";
CM_ SG_ 159 EPS_Lenkmoment "Gibt das durch den Momentensensor detektiertes Lenkhandmoment (Absolutmoment) aus

Wertebereich von 0x321 - 0x3FD reserviert (z.Zt. nicht bedient)";
CM_ SG_ 159 EPS_Lenkungstyp "Signal beschreibt den eingebauten Lenkungstyp. Enthält z. B. implizit auch die Information, welche Ritzelübersetzung verbaut ist. Wichtig für die Regelsysteme HCA und DSR.
Im MQB gilt das 'EPS LH CAN-Schnittstelle'.";
CM_ SG_ 159 EPS_VZ_BLW "Vorzeichen Berechneter Lenkwinkel

(für EPS_Berechneter_LW)";
CM_ SG_ 159 EPS_VZ_Lenkmoment "Vorzeichen Lenkhandmoment";

CM_ SG_ 981 BCM1_Abblendlicht_Anf "Anforderung Abblendlicht
";
CM_ SG_ 981 BCM1_Adaptive_Lichtvert_Anf "Funktion 'Adaptive Lichtverteilung' im AFS-SG  Ein- und Ausschalten";
CM_ SG_ 981 BCM1_Allwetterlicht_Anf "Anforderung eines Allwetterlichts (über AFS-SG realisiert): Licht für schlechte Sichtverhältnisse";
CM_ SG_ 981 BCM1_Animationssperrung "Sperrung der Scheinwerfer- und Heckleuchten-Animationen. Grund für Sperrung sind allgemeine Rahmenbedingungen, wie beispielseweise eine LDS-Stellung ungleich 'Auto'";
CM_ SG_ 981 BCM1_Autobahnlicht_Anf "Anforderung Autobahnlicht
";
CM_ SG_ 981 BCM1_CH_aktiv "Coming Home (zusätzlich zum Signal 'BCM1_CH_LH_aktiv' in der Botschaft BCM1_01)";
CM_ SG_ 981 BCM1_CH_LH_aktiv "Status Comming / Leaving Home
";
CM_ SG_ 981 BCM1_Fernlicht_Anf "Anforderung Fernlicht
";
CM_ SG_ 981 BCM1_FOD_Sperrung_Animationen_HL "Sperrung Heckleuchten-Animationen durch FoD.";
CM_ SG_ 981 BCM1_FoD_Sperrung_WiBli "Sperrung Wischeffekt des dynamischen Blinkers (Front & Heck) durch FoD";
CM_ SG_ 981 BCM1_Gleitende_Leuchtw_Anf "Funktion 'Gleitende Leuchtweite' im AFS-SG  freischalten";
CM_ SG_ 981 BCM1_GLW_Fernlicht_Anf "Harte Fernlichtanforderung von BCM1 an die Funktion 'gleitende Leuchtweite' im AFS-SG";
CM_ SG_ 981 BCM1_Kurvenlicht_links_Anf "Ansteuerung linkes Kurvenlicht/Abbiegelicht duch BCM1";
CM_ SG_ 981 BCM1_Kurvenlicht_rechts_Anf "Ansteuerung rechtes Kurvenlicht/Abbiegelicht duch BCM1";
CM_ SG_ 981 BCM1_LH_aktiv "Leaving Home (zusätzlich zum Signal 'BCM1_CH_LH_aktiv' in der Botschaft BCM1_01)";
CM_ SG_ 981 BCM1_Nebellicht_Anf "Anforderung Nebellicht
";
CM_ SG_ 981 BCM1_Nebelschluss_Ahg_Anf "Anforderung: Nebelschlusslicht Anhänger (Sollzustand)
";
CM_ SG_ 981 BCM1_Nebelschluss_Fzg_Anf "Anforderung: Nebelschlusslicht Fahrzeug (Sollzustand)
";
CM_ SG_ 981 BCM1_Parklicht_li_Anf "Anforderung: Parklicht links (Sollzustand)
";
CM_ SG_ 981 BCM1_Parklicht_re_Anf "Anforderung: Parklicht rechts (Sollzustand)
";
CM_ SG_ 981 BCM1_Regenlicht_Anf "Anforderung: Regenlicht (Sollzustand)
";
CM_ SG_ 981 BCM1_Schlusslicht_Anf "Anforderung: Schlusslicht Fahrzeug (Sollzustand)
";
CM_ SG_ 981 BCM1_Schlusslicht_Signatur "Anforderung der Umschaltung der Schlusslicht-Signatur";
CM_ SG_ 981 BCM1_Signaturlicht_Anf "Signal zur Anforderung des Signaturlichts";
CM_ SG_ 981 BCM1_Standlicht_Anf "Anforderung: Schlusslicht (Sollzustand)";
CM_ SG_ 981 BCM1_Tagfahrlicht_Anf "Anforderung: Tagfahrlicht (Sollzustand)";
CM_ SG_ 981 BCM1_Touristen_Licht_Anf "Anforderung: Touristenlicht (Sollzustand)";
CM_ SG_ 981 BCM1_Umfeldleuchten_Anf "Anforderung für Umfeldleuchten";
CM_ SG_ 981 BCM_Rueckfahrlicht_Anf "Anforderung Rückfahrlicht (Sollzustand). 
Das Signal wird entprellt (typisch 400ms) und bei KL15EIN gesendet. Das Signal ist unabhängig von der Position des Heckdeckels (kein Überhitzungsschutz).";
CM_ SG_ 981 Licht_Anf_01_BZ "4bit Botschaftszaehler, wird mit jeder Sendebotschaft inkrementiert";
CM_ SG_ 981 Licht_Anf_01_CRC "Für MLB:
'Berechnung siehe Lastenheft 'Kommunikationsabsicherung für FlexRay und CAN''

Ab MQB und MLBevo:
'Berechnung siehe Lastenheft 'End-to-End Kommunikationsabsicherung''

Endwerte siehe Begleitdokument 'S-PDU Kennungsfolgen'";
BA_DEF_REL_ BU_SG_REL_  "GenSigTimeoutTime" INT 0 65535;
BA_DEF_ BO_  "DiagRequest" ENUM "No", "Yes";
BA_DEF_ BO_  "DiagResponse" ENUM "No", "Yes";
BA_DEF_ BO_  "DiagState" ENUM "No", "Yes";
BA_DEF_ BO_  "GenMsgChkConstant" HEX 0 4095;
BA_DEF_ BO_  "GenMsgCycleTime" INT 0 65535;
BA_DEF_ BO_  "GenMsgCycleTimeFast" INT 0 65535;
BA_DEF_ BO_  "GenMsgDelayTime" INT 0 100000;
BA_DEF_ BO_  "GenMsgILSupport" ENUM "No", "Yes";
BA_DEF_ BO_  "GenMsgNrOfRepetition" INT 0 100;
BA_DEF_ BO_  "GenMsgPDUConstants" STRING;
BA_DEF_ BO_  "GenMsgSendType" ENUM "Cyclic", "not_used", "not_used", "not_used", "not_used", "not_used", "not_used", "IfActive", "NoMsgSendType";
BA_DEF_ BO_  "GenMsgStartDelayTime" INT 0 100000;
BA_DEF_ BO_  "NmMessage" ENUM "No", "Yes";
BA_DEF_ BO_  "NmhMessage" ENUM "No", "Yes";
BA_DEF_ BO_  "MsgType" ENUM "Application", "NM ", "NMH", "TP2.0", "ISO-TP ", "BAP", "EID", "KS", "XCP_PRE_CONFIGURED", "XCP_RUNTIME_CONFIGURED";
BA_DEF_ BO_  "VAGTP20_API" HEX 0 255;
BA_DEF_ BO_  "VAGTP20_DynConnection" ENUM "No", "Yes";
BA_DEF_ BO_  "VAGTP20_DynSetup" ENUM "No", "Yes";
BA_DEF_ BO_  "VAGTP20_StatConnection" ENUM "No", "Yes";
BA_DEF_ SG_  "GenSigActiveRepetitions" INT -2147483648 2147483647;
BA_DEF_ SG_  "GenSigInactiveValue" INT -2147483648 2147483647;
BA_DEF_ SG_  "GenSigSendType" ENUM "Cyclic", "OnWrite", "OnWriteWithRepetition", "OnChange", "OnChangeWithRepetition", "IfActive", "IfActiveWithRepetition", "NoSigSendType", "OnChangeAndIfActive", "OnChangeAndIfActiveWithRepetition";
BA_DEF_ SG_  "GenSigStartValue" INT -2147483648 2147483647;
BA_DEF_ SG_  "NWM-WakeupAllowed" ENUM "No", "Yes";
BA_DEF_ SG_  "GenSigFuncType" ENUM "NoFunction", "MsgCounter", "CRC-8", "XOR", "XOR-2", "DatedBit", "SW-Kl15", "CHK", "Constant", "Protocol", "CRC-8-SAE_J1850", "CRC-32", "DataLength", "DataID", "MsgCounter16", "SOK-Signatur", "Cluster";
BA_DEF_ SG_  "GenSigSwitchedByIgnition" ENUM "No", "Yes";
BA_DEF_ SG_  "Fehlerwert" HEX 0 2147483647;
BA_DEF_ SG_  "GenSigMissingSourceValue" HEX 0 2147483647;
BA_DEF_DEF_REL_  "GenSigTimeoutTime" 0;
BA_DEF_DEF_  "DiagRequest" "No";
BA_DEF_DEF_  "DiagResponse" "No";
BA_DEF_DEF_  "DiagState" "No";
BA_DEF_DEF_  "GenMsgChkConstant" 0;
BA_DEF_DEF_  "GenMsgCycleTime" 0;
BA_DEF_DEF_  "GenMsgCycleTimeFast" 0;
BA_DEF_DEF_  "GenMsgDelayTime" 0;
BA_DEF_DEF_  "GenMsgILSupport" "No";
BA_DEF_DEF_  "GenMsgNrOfRepetition" 0;
BA_DEF_DEF_  "GenMsgPDUConstants" "";
BA_DEF_DEF_  "GenMsgSendType" "NoMsgSendType";
BA_DEF_DEF_  "GenMsgStartDelayTime" 0;
BA_DEF_DEF_  "NmMessage" "No";
BA_DEF_DEF_  "NmhMessage" "No";
BA_DEF_DEF_  "MsgType" "Application";
BA_DEF_DEF_  "VAGTP20_API" 0;
BA_DEF_DEF_  "VAGTP20_DynConnection" "No";
BA_DEF_DEF_  "VAGTP20_DynSetup" "No";
BA_DEF_DEF_  "VAGTP20_StatConnection" "No";
BA_DEF_DEF_  "GenSigActiveRepetitions" 0;
BA_DEF_DEF_  "GenSigInactiveValue" 0;
BA_DEF_DEF_  "GenSigSendType" "NoSigSendType";
BA_DEF_DEF_  "GenSigStartValue" 0;
BA_DEF_DEF_  "NWM-WakeupAllowed" "No";
BA_DEF_DEF_  "GenSigFuncType" "NoFunction";
BA_DEF_DEF_  "GenSigSwitchedByIgnition" "Yes";
BA_DEF_DEF_  "Fehlerwert" 0;
BA_DEF_DEF_  "GenSigMissingSourceValue" 0;
BA_ "GenMsgCycleTime" BO_ 2589283621 1000;
BA_ "GenMsgDelayTime" BO_ 2589283621 100;
BA_ "GenMsgILSupport" BO_ 2589283621 1;
BA_ "GenMsgSendType" BO_ 2589283621 0;
BA_ "GenMsgCycleTime" BO_ 992 100;
BA_ "GenMsgILSupport" BO_ 992 1;
BA_ "GenMsgSendType" BO_ 992 0;
BA_ "GenMsgCycleTime" BO_ 1712 500;
BA_ "GenMsgILSupport" BO_ 1712 1;
BA_ "GenMsgSendType" BO_ 1712 0;
BA_ "GenMsgCycleTime" BO_ 1505 1000;
BA_ "GenMsgILSupport" BO_ 1505 1;
BA_ "GenMsgSendType" BO_ 1505 0;
BA_ "GenMsgStartDelayTime" BO_ 1505 410;
BA_ "GenMsgCycleTime" BO_ 605 1000;
BA_ "GenMsgILSupport" BO_ 605 1;
BA_ "GenMsgPDUConstants" BO_ 605 "0xda,0x6b,0x0e,0xb2,0x78,0xbd,0x5a,0x81,0x7b,0xd6,0x41,0x39,0x76,0xb6,0xd7,0x35";
BA_ "GenMsgSendType" BO_ 605 0;
BA_ "GenMsgStartDelayTime" BO_ 605 420;
BA_ "GenMsgCycleTime" BO_ 2549088398 500;
BA_ "GenMsgILSupport" BO_ 2549088398 1;
BA_ "GenMsgSendType" BO_ 2549088398 0;
BA_ "GenMsgCycleTime" BO_ 2549088403 500;
BA_ "GenMsgILSupport" BO_ 2549088403 1;
BA_ "GenMsgSendType" BO_ 2549088403 0;
BA_ "GenMsgCycleTime" BO_ 2549088442 500;
BA_ "GenMsgILSupport" BO_ 2549088442 1;
BA_ "GenMsgSendType" BO_ 2549088442 0;
BA_ "GenMsgCycleTime" BO_ 2549088272 500;
BA_ "GenMsgILSupport" BO_ 2549088272 1;
BA_ "GenMsgSendType" BO_ 2549088272 0;
BA_ "GenMsgStartDelayTime" BO_ 2549088272 75;
BA_ "GenMsgCycleTime" BO_ 2549088355 500;
BA_ "GenMsgILSupport" BO_ 2549088355 1;
BA_ "GenMsgSendType" BO_ 2549088355 0;
BA_ "GenMsgCycleTime" BO_ 2549088371 500;
BA_ "GenMsgILSupport" BO_ 2549088371 1;
BA_ "GenMsgSendType" BO_ 2549088371 0;
BA_ "GenMsgCycleTime" BO_ 2549088258 500;
BA_ "GenMsgILSupport" BO_ 2549088258 1;
BA_ "GenMsgSendType" BO_ 2549088258 0;
BA_ "GenMsgCycleTime" BO_ 779 50;
BA_ "GenMsgILSupport" BO_ 779 1;
BA_ "GenMsgSendType" BO_ 779 0;
BA_ "GenMsgCycleTime" BO_ 1719 1000;
BA_ "GenMsgDelayTime" BO_ 1719 100;
BA_ "GenMsgILSupport" BO_ 1719 1;
BA_ "GenMsgSendType" BO_ 1719 0;
BA_ "GenMsgCycleTime" BO_ 1720 500;
BA_ "GenMsgILSupport" BO_ 1720 1;
BA_ "GenMsgSendType" BO_ 1720 0;
BA_ "GenMsgCycleTime" BO_ 1724 1000;
BA_ "GenMsgILSupport" BO_ 1724 1;
BA_ "GenMsgSendType" BO_ 1724 0;
BA_ "GenMsgCycleTime" BO_ 2527679638 1000;
BA_ "GenMsgDelayTime" BO_ 2527679638 100;
BA_ "GenMsgILSupport" BO_ 2527679638 1;
BA_ "GenMsgSendType" BO_ 2527679638 0;
BA_ "GenMsgCycleTime" BO_ 2527679639 1000;
BA_ "GenMsgCycleTimeFast" BO_ 2527679639 100;
BA_ "GenMsgDelayTime" BO_ 2527679639 100;
BA_ "GenMsgILSupport" BO_ 2527679639 1;
BA_ "GenMsgSendType" BO_ 2527679639 0;
BA_ "GenMsgCycleTime" BO_ 2527679656 1000;
BA_ "GenMsgDelayTime" BO_ 2527679656 50;
BA_ "GenMsgILSupport" BO_ 2527679656 1;
BA_ "GenMsgSendType" BO_ 2527679656 0;
BA_ "GenMsgStartDelayTime" BO_ 2527679656 450;
BA_ "MsgType" BO_ 2549875055 4;
BA_ "MsgType" BO_ 2550006127 4;
BA_ "MsgType" BO_ 2549875059 4;
BA_ "MsgType" BO_ 2550006131 4;
BA_ "MsgType" BO_ 2549875056 4;
BA_ "MsgType" BO_ 2550006128 4;
BA_ "MsgType" BO_ 2549875053 4;
BA_ "MsgType" BO_ 2550006125 4;
BA_ "GenMsgCycleTime" BO_ 701 40;
BA_ "GenMsgILSupport" BO_ 701 1;
BA_ "GenMsgSendType" BO_ 701 0;
BA_ "GenMsgCycleTime" BO_ 2527679653 960;
BA_ "GenMsgDelayTime" BO_ 2527679653 80;
BA_ "GenMsgILSupport" BO_ 2527679653 1;
BA_ "GenMsgSendType" BO_ 2527679653 0;
BA_ "GenMsgCycleTime" BO_ 2463978818 320;
BA_ "GenMsgDelayTime" BO_ 2463978818 20;
BA_ "GenMsgILSupport" BO_ 2463978818 1;
BA_ "GenMsgPDUConstants" BO_ 2463978818 "0x96,0xb2,0xc5,0x01,0x2d,0x0c,0xe0,0xf8,0x50,0x8a,0x08,0xd7,0x62,0xf2,0xf5,0x33";
BA_ "GenMsgSendType" BO_ 2463978818 0;
BA_ "GenMsgCycleTime" BO_ 2527679780 1000;
BA_ "GenMsgDelayTime" BO_ 2527679780 50;
BA_ "GenMsgILSupport" BO_ 2527679780 1;
BA_ "GenMsgSendType" BO_ 2527679780 0;
BA_ "GenMsgCycleTime" BO_ 2463978684 100;
BA_ "GenMsgILSupport" BO_ 2463978684 1;
BA_ "GenMsgSendType" BO_ 2463978684 0;
BA_ "GenMsgCycleTime" BO_ 548 20;
BA_ "GenMsgILSupport" BO_ 548 1;
BA_ "GenMsgSendType" BO_ 548 0;
BA_ "GenMsgCycleTime" BO_ 2589283974 1000;
BA_ "GenMsgILSupport" BO_ 2589283974 1;
BA_ "GenMsgSendType" BO_ 2589283974 0;
BA_ "GenMsgChkConstant" BO_ 159 245;
BA_ "GenMsgCycleTime" BO_ 159 100;
BA_ "GenMsgILSupport" BO_ 159 1;
BA_ "GenMsgPDUConstants" BO_ 159 "0xf5,0xf5,0xf5,0xf5,0xf5,0xf5,0xf5,0xf5,0xf5,0xf5,0xf5,0xf5,0xf5,0xf5,0xf5,0xf5";
BA_ "GenMsgSendType" BO_ 159 0;
BA_ "GenMsgCycleTime" BO_ 981 100;
BA_ "GenMsgDelayTime" BO_ 981 50;
BA_ "GenMsgILSupport" BO_ 981 1;
BA_ "GenMsgPDUConstants" BO_ 981 "0xc5,0x39,0xc7,0xf9,0x92,0xd8,0x24,0xce,0xf1,0xb5,0x7a,0xc4,0xbc,0x60,0xe3,0xd1";
BA_ "GenMsgSendType" BO_ 981 0;
BA_ "GenSigSendType" SG_ 2589283621 KL_ACmax_Aktiv 3;
BA_ "GenSigSwitchedByIgnition" SG_ 2589283621 KL_ACmax_Aktiv 0;
BA_ "GenSigSendType" SG_ 2589283621 KL_Defrost_Aktiv 3;
BA_ "GenSigSwitchedByIgnition" SG_ 2589283621 KL_Defrost_Aktiv 0;
BA_ "GenSigSendType" SG_ 2589283621 KL_ECO_Aktiv 3;
BA_ "GenSigSwitchedByIgnition" SG_ 2589283621 KL_ECO_Aktiv 0;
BA_ "GenSigSendType" SG_ 2589283621 KL_ECO_PRO_Aktiv 3;
BA_ "GenSigSwitchedByIgnition" SG_ 2589283621 KL_ECO_PRO_Aktiv 0;
BA_ "GenSigSendType" SG_ 2589283621 KL_Eps_Innen 3;
BA_ "GenSigStartValue" SG_ 2589283621 KL_Eps_Innen 254;
BA_ "GenSigSwitchedByIgnition" SG_ 2589283621 KL_Eps_Innen 0;
BA_ "Fehlerwert" SG_ 2589283621 KL_Eps_Innen 255;
BA_ "GenSigSendType" SG_ 2589283621 KL_FlHz_Soll_HL 3;
BA_ "GenSigSwitchedByIgnition" SG_ 2589283621 KL_FlHz_Soll_HL 0;
BA_ "GenSigSendType" SG_ 2589283621 KL_FlHz_Soll_HR 3;
BA_ "GenSigSwitchedByIgnition" SG_ 2589283621 KL_FlHz_Soll_HR 0;
BA_ "GenSigSendType" SG_ 2589283621 KL_FlHz_Soll_VL 3;
BA_ "GenSigSwitchedByIgnition" SG_ 2589283621 KL_FlHz_Soll_VL 0;
BA_ "GenSigSendType" SG_ 2589283621 KL_FlHz_Soll_VR 3;
BA_ "GenSigSwitchedByIgnition" SG_ 2589283621 KL_FlHz_Soll_VR 0;
BA_ "GenSigSendType" SG_ 2589283621 KL_Kundeneingriff_Geblaese 3;
BA_ "GenSigSwitchedByIgnition" SG_ 2589283621 KL_Kundeneingriff_Geblaese 0;
BA_ "GenSigSendType" SG_ 2589283621 KL_NV_Energie_Anf 3;
BA_ "GenSigStartValue" SG_ 2589283621 KL_NV_Energie_Anf 254;
BA_ "GenSigSwitchedByIgnition" SG_ 2589283621 KL_NV_Energie_Anf 0;
BA_ "Fehlerwert" SG_ 2589283621 KL_NV_Energie_Anf 255;
BA_ "GenSigSendType" SG_ 2589283621 KL_QBit_Sonnenintensitaet 3;
BA_ "GenSigStartValue" SG_ 2589283621 KL_QBit_Sonnenintensitaet 1;
BA_ "GenSigSwitchedByIgnition" SG_ 2589283621 KL_QBit_Sonnenintensitaet 0;
BA_ "GenSigSendType" SG_ 2589283621 KL_Sonnenintensitaet 0;
BA_ "GenSigSwitchedByIgnition" SG_ 2589283621 KL_Sonnenintensitaet 0;
BA_ "Fehlerwert" SG_ 2589283621 KL_Sonnenintensitaet 255;
BA_ "GenSigSendType" SG_ 2589283621 KL_Status_Klimastil 3;
BA_ "GenSigSwitchedByIgnition" SG_ 2589283621 KL_Status_Klimastil 0;
BA_ "GenSigSendType" SG_ 2589283621 KL_Thermischer_Bedarf 3;
BA_ "GenSigStartValue" SG_ 2589283621 KL_Thermischer_Bedarf 6;
BA_ "GenSigSwitchedByIgnition" SG_ 2589283621 KL_Thermischer_Bedarf 0;
BA_ "Fehlerwert" SG_ 2589283621 KL_Thermischer_Bedarf 7;
BA_ "GenSigSendType" SG_ 2589283621 KL_Umluft_Connect_status 3;
BA_ "GenSigSwitchedByIgnition" SG_ 2589283621 KL_Umluft_Connect_status 0;
BA_ "GenSigSendType" SG_ 2589283621 KL_ZR_Anforderung 3;
BA_ "GenSigSwitchedByIgnition" SG_ 2589283621 KL_ZR_Anforderung 0;
BA_ "GenSigSendType" SG_ 992 KL_Fehler_Fussraum_Klappen 0;
BA_ "GenSigSwitchedByIgnition" SG_ 992 KL_Fehler_Fussraum_Klappen 0;
BA_ "GenSigSendType" SG_ 992 KL_Fehler_Temp_Klappen 0;
BA_ "GenSigSwitchedByIgnition" SG_ 992 KL_Fehler_Temp_Klappen 0;
BA_ "GenSigSendType" SG_ 992 KL_Fehler_Temp_MA_Klappen 0;
BA_ "GenSigSwitchedByIgnition" SG_ 992 KL_Fehler_Temp_MA_Klappen 0;
BA_ "GenSigSendType" SG_ 992 KL_Fehler_Umluft 0;
BA_ "GenSigSwitchedByIgnition" SG_ 992 KL_Fehler_Umluft 0;
BA_ "GenSigSendType" SG_ 992 KL_Fond_Absperrventil 0;
BA_ "GenSigSwitchedByIgnition" SG_ 992 KL_Fond_Absperrventil 0;
BA_ "GenSigSendType" SG_ 992 KL_Fond_Fuss_Temp_hl 0;
BA_ "GenSigStartValue" SG_ 992 KL_Fond_Fuss_Temp_hl 1022;
BA_ "GenSigSwitchedByIgnition" SG_ 992 KL_Fond_Fuss_Temp_hl 0;
BA_ "Fehlerwert" SG_ 992 KL_Fond_Fuss_Temp_hl 1023;
BA_ "GenSigSendType" SG_ 992 KL_Fond_Fuss_Temp_hr 0;
BA_ "GenSigStartValue" SG_ 992 KL_Fond_Fuss_Temp_hr 1022;
BA_ "GenSigSwitchedByIgnition" SG_ 992 KL_Fond_Fuss_Temp_hr 0;
BA_ "Fehlerwert" SG_ 992 KL_Fond_Fuss_Temp_hr 1023;
BA_ "GenSigSendType" SG_ 992 KL_Fond_KD_Fehler 0;
BA_ "GenSigSwitchedByIgnition" SG_ 992 KL_Fond_KD_Fehler 0;
BA_ "GenSigSendType" SG_ 992 KL_MA_Temp_hl 0;
BA_ "GenSigStartValue" SG_ 992 KL_MA_Temp_hl 1022;
BA_ "GenSigSwitchedByIgnition" SG_ 992 KL_MA_Temp_hl 0;
BA_ "Fehlerwert" SG_ 992 KL_MA_Temp_hl 1023;
BA_ "GenSigSendType" SG_ 992 KL_MA_Temp_hr 0;
BA_ "GenSigStartValue" SG_ 992 KL_MA_Temp_hr 1022;
BA_ "GenSigSwitchedByIgnition" SG_ 992 KL_MA_Temp_hr 0;
BA_ "Fehlerwert" SG_ 992 KL_MA_Temp_hr 1023;
BA_ "GenSigSendType" SG_ 992 KL_RAB 0;
BA_ "GenSigSwitchedByIgnition" SG_ 992 KL_RAB 0;
BA_ "GenSigSendType" SG_ 992 KL_SH_Soll_hl 0;
BA_ "GenSigSwitchedByIgnition" SG_ 992 KL_SH_Soll_hl 0;
BA_ "GenSigSendType" SG_ 992 KL_SH_Soll_hr 0;
BA_ "GenSigSwitchedByIgnition" SG_ 992 KL_SH_Soll_hr 0;
BA_ "GenSigSendType" SG_ 992 KL_SIH_Takt_hl 0;
BA_ "GenSigSwitchedByIgnition" SG_ 992 KL_SIH_Takt_hl 0;
BA_ "GenSigSendType" SG_ 992 KL_SIH_Takt_hr 0;
BA_ "GenSigSwitchedByIgnition" SG_ 992 KL_SIH_Takt_hr 0;
BA_ "GenSigSendType" SG_ 992 KL_SL_Soll_hl 0;
BA_ "GenSigSwitchedByIgnition" SG_ 992 KL_SL_Soll_hl 0;
BA_ "GenSigSendType" SG_ 992 KL_SL_Soll_hr 0;
BA_ "GenSigSwitchedByIgnition" SG_ 992 KL_SL_Soll_hr 0;
BA_ "GenSigSendType" SG_ 1712 FS_Luftfeuchte_rel 0;
BA_ "Fehlerwert" SG_ 1712 FS_Luftfeuchte_rel 255;
BA_ "GenSigMissingSourceValue" SG_ 1712 FS_Luftfeuchte_rel 255;
BA_ "GenSigSendType" SG_ 1712 FS_ResponseError 0;
BA_ "GenSigSwitchedByIgnition" SG_ 1712 FS_ResponseError 0;
BA_ "Fehlerwert" SG_ 1712 FS_ResponseError 1;
BA_ "GenSigSendType" SG_ 1712 FS_Taupunkt 0;
BA_ "Fehlerwert" SG_ 1712 FS_Taupunkt 1023;
BA_ "GenSigMissingSourceValue" SG_ 1712 FS_Taupunkt 1023;
BA_ "GenSigSendType" SG_ 1712 FS_Temp_Scheibe 0;
BA_ "Fehlerwert" SG_ 1712 FS_Temp_Scheibe 1023;
BA_ "GenSigMissingSourceValue" SG_ 1712 FS_Temp_Scheibe 1023;
BA_ "GenSigSendType" SG_ 1712 FS_Temp_Sensor 0;
BA_ "Fehlerwert" SG_ 1712 FS_Temp_Sensor 255;
BA_ "GenSigMissingSourceValue" SG_ 1712 FS_Temp_Sensor 255;
BA_ "GenSigSendType" SG_ 1505 BCM1_Aussen_Temp_ungef 0;
BA_ "GenSigStartValue" SG_ 1505 BCM1_Aussen_Temp_ungef 254;
BA_ "GenSigSwitchedByIgnition" SG_ 1505 BCM1_Aussen_Temp_ungef 0;
BA_ "Fehlerwert" SG_ 1505 BCM1_Aussen_Temp_ungef 255;
BA_ "GenSigSendType" SG_ 1505 BCM1_FStatus_Aussentemp_ungef 0;
BA_ "GenSigStartValue" SG_ 1505 BCM1_FStatus_Aussentemp_ungef 1;
BA_ "GenSigSwitchedByIgnition" SG_ 1505 BCM1_FStatus_Aussentemp_ungef 0;
BA_ "GenSigSendType" SG_ 1505 BCM1_Kompressorstrom_ist 0;
BA_ "GenSigStartValue" SG_ 1505 BCM1_Kompressorstrom_ist 254;
BA_ "GenSigSwitchedByIgnition" SG_ 1505 BCM1_Kompressorstrom_ist 0;
BA_ "Fehlerwert" SG_ 1505 BCM1_Kompressorstrom_ist 255;
BA_ "GenSigSendType" SG_ 1505 BCM1_OBD_FStatus_ATemp 0;
BA_ "GenSigSwitchedByIgnition" SG_ 1505 BCM1_OBD_FStatus_ATemp 0;
BA_ "GenSigSendType" SG_ 1505 BCM1_PTC_stufig_Status 0;
BA_ "GenSigStartValue" SG_ 1505 BCM1_PTC_stufig_Status 6;
BA_ "GenSigSwitchedByIgnition" SG_ 1505 BCM1_PTC_stufig_Status 0;
BA_ "Fehlerwert" SG_ 1505 BCM1_PTC_stufig_Status 7;
BA_ "GenSigSendType" SG_ 1505 BCM_Heizungsabsperrventil_Status 0;
BA_ "GenSigStartValue" SG_ 1505 BCM_Heizungsabsperrventil_Status 2;
BA_ "GenSigSwitchedByIgnition" SG_ 1505 BCM_Heizungsabsperrventil_Status 0;
BA_ "Fehlerwert" SG_ 1505 BCM_Heizungsabsperrventil_Status 3;
BA_ "GenSigSendType" SG_ 1505 BCM_Heizungspumpe_Status 0;
BA_ "GenSigStartValue" SG_ 1505 BCM_Heizungspumpe_Status 2;
BA_ "GenSigSwitchedByIgnition" SG_ 1505 BCM_Heizungspumpe_Status 0;
BA_ "Fehlerwert" SG_ 1505 BCM_Heizungspumpe_Status 3;
BA_ "GenSigSendType" SG_ 1505 BCM_Kompressorkupplung_Status 0;
BA_ "GenSigStartValue" SG_ 1505 BCM_Kompressorkupplung_Status 2;
BA_ "GenSigSwitchedByIgnition" SG_ 1505 BCM_Kompressorkupplung_Status 0;
BA_ "Fehlerwert" SG_ 1505 BCM_Kompressorkupplung_Status 3;
BA_ "GenSigSendType" SG_ 605 KLR_01_BZ 0;
BA_ "GenSigFuncType" SG_ 605 KLR_01_BZ 1;
BA_ "GenSigSwitchedByIgnition" SG_ 605 KLR_01_BZ 0;
BA_ "GenSigSendType" SG_ 605 KLR_01_CRC 0;
BA_ "GenSigFuncType" SG_ 605 KLR_01_CRC 2;
BA_ "GenSigSwitchedByIgnition" SG_ 605 KLR_01_CRC 0;
BA_ "GenSigSendType" SG_ 605 KLR_Fehler 0;
BA_ "GenSigSwitchedByIgnition" SG_ 605 KLR_Fehler 0;
BA_ "Fehlerwert" SG_ 605 KLR_Fehler 1;
BA_ "GenSigSendType" SG_ 605 KLR_Fehler_Codierung 0;
BA_ "GenSigSwitchedByIgnition" SG_ 605 KLR_Fehler_Codierung 0;
BA_ "Fehlerwert" SG_ 605 KLR_Fehler_Codierung 1;
BA_ "GenSigSendType" SG_ 605 KLR_Lokalaktiv 0;
BA_ "GenSigSwitchedByIgnition" SG_ 605 KLR_Lokalaktiv 0;
BA_ "GenSigSendType" SG_ 605 KLR_ResponseError 0;
BA_ "GenSigSwitchedByIgnition" SG_ 605 KLR_ResponseError 0;
BA_ "Fehlerwert" SG_ 605 KLR_ResponseError 1;
BA_ "GenSigSendType" SG_ 605 KLR_Touchauswertung 0;
BA_ "GenSigStartValue" SG_ 605 KLR_Touchauswertung 14;
BA_ "GenSigSwitchedByIgnition" SG_ 605 KLR_Touchauswertung 0;
BA_ "GenSigSendType" SG_ 605 KLR_Touchintensitaet_1 0;
BA_ "GenSigStartValue" SG_ 605 KLR_Touchintensitaet_1 254;
BA_ "GenSigSwitchedByIgnition" SG_ 605 KLR_Touchintensitaet_1 0;
BA_ "Fehlerwert" SG_ 605 KLR_Touchintensitaet_1 255;
BA_ "GenSigSendType" SG_ 605 KLR_Touchintensitaet_2 0;
BA_ "GenSigStartValue" SG_ 605 KLR_Touchintensitaet_2 254;
BA_ "GenSigSwitchedByIgnition" SG_ 605 KLR_Touchintensitaet_2 0;
BA_ "Fehlerwert" SG_ 605 KLR_Touchintensitaet_2 255;
BA_ "GenSigSendType" SG_ 605 KLR_Touchintensitaet_3 0;
BA_ "GenSigStartValue" SG_ 605 KLR_Touchintensitaet_3 254;
BA_ "GenSigSwitchedByIgnition" SG_ 605 KLR_Touchintensitaet_3 0;
BA_ "Fehlerwert" SG_ 605 KLR_Touchintensitaet_3 255;
BA_ "GenSigSendType" SG_ 2549088398 BedienDisp_vo_Abschaltstufe 0;
BA_ "GenSigSwitchedByIgnition" SG_ 2549088398 BedienDisp_vo_Abschaltstufe 0;
BA_ "GenSigSendType" SG_ 2549088398 BedienDisp_vo_KD_Fehler 0;
BA_ "GenSigSwitchedByIgnition" SG_ 2549088398 BedienDisp_vo_KD_Fehler 0;
BA_ "GenSigSendType" SG_ 2549088398 BedienDisp_vo_KompSchutz 0;
BA_ "GenSigSwitchedByIgnition" SG_ 2549088398 BedienDisp_vo_KompSchutz 0;
BA_ "GenSigSendType" SG_ 2549088398 BedienDisp_vo_Nachlauftyp 0;
BA_ "GenSigStartValue" SG_ 2549088398 BedienDisp_vo_Nachlauftyp 2;
BA_ "GenSigSwitchedByIgnition" SG_ 2549088398 BedienDisp_vo_Nachlauftyp 0;
BA_ "GenSigSendType" SG_ 2549088398 BedienDisp_vo_SNI 0;
BA_ "GenSigStartValue" SG_ 2549088398 BedienDisp_vo_SNI 142;
BA_ "GenSigSwitchedByIgnition" SG_ 2549088398 BedienDisp_vo_SNI 0;
BA_ "GenSigSendType" SG_ 2549088398 BedienDisp_vo_Transport_Mode 0;
BA_ "GenSigSwitchedByIgnition" SG_ 2549088398 BedienDisp_vo_Transport_Mode 0;
BA_ "GenSigSendType" SG_ 2549088398 KN_BedienDisp_v_BusKnockOut 0;
BA_ "GenSigSwitchedByIgnition" SG_ 2549088398 KN_BedienDisp_v_BusKnockOut 0;
BA_ "GenSigSendType" SG_ 2549088398 KN_BedienDisp_v_BusKnockOutTimer 0;
BA_ "GenSigSwitchedByIgnition" SG_ 2549088398 KN_BedienDisp_v_BusKnockOutTimer 0;
BA_ "GenSigSendType" SG_ 2549088398 KN_BedienDisp_v_ECUKnockOut 0;
BA_ "GenSigSwitchedByIgnition" SG_ 2549088398 KN_BedienDisp_v_ECUKnockOut 0;
BA_ "GenSigSendType" SG_ 2549088398 KN_BedienDisp_v_ECUKnockOutTimer 0;
BA_ "GenSigSwitchedByIgnition" SG_ 2549088398 KN_BedienDisp_v_ECUKnockOutTimer 0;
BA_ "GenSigSendType" SG_ 2549088398 NM_BedienDisp_vo_Wakeup 0;
BA_ "GenSigSwitchedByIgnition" SG_ 2549088398 NM_BedienDisp_vo_Wakeup 0;
BA_ "GenSigSendType" SG_ 2549088398 NMH_BedienDisp_vo_Lokalaktiv 0;
BA_ "GenSigSwitchedByIgnition" SG_ 2549088398 NMH_BedienDisp_vo_Lokalaktiv 0;
BA_ "GenSigSendType" SG_ 2549088398 NMH_BedienDisp_vo_Subsystemaktiv 0;
BA_ "GenSigSwitchedByIgnition" SG_ 2549088398 NMH_BedienDisp_vo_Subsystemaktiv 0;
BA_ "GenSigSendType" SG_ 2549088403 BedienSG_hi_Abschaltstufe 0;
BA_ "GenSigSwitchedByIgnition" SG_ 2549088403 BedienSG_hi_Abschaltstufe 0;
BA_ "GenSigSendType" SG_ 2549088403 BedienSG_hi_KD_Fehler 0;
BA_ "GenSigSwitchedByIgnition" SG_ 2549088403 BedienSG_hi_KD_Fehler 0;
BA_ "GenSigSendType" SG_ 2549088403 BedienSG_hi_KompSchutz 0;
BA_ "GenSigSwitchedByIgnition" SG_ 2549088403 BedienSG_hi_KompSchutz 0;
BA_ "GenSigSendType" SG_ 2549088403 BedienSG_hi_Nachlauftyp 0;
BA_ "GenSigStartValue" SG_ 2549088403 BedienSG_hi_Nachlauftyp 2;
BA_ "GenSigSwitchedByIgnition" SG_ 2549088403 BedienSG_hi_Nachlauftyp 0;
BA_ "GenSigSendType" SG_ 2549088403 BedienSG_hi_SNI 0;
BA_ "GenSigStartValue" SG_ 2549088403 BedienSG_hi_SNI 147;
BA_ "GenSigSwitchedByIgnition" SG_ 2549088403 BedienSG_hi_SNI 0;
BA_ "GenSigSendType" SG_ 2549088403 BedienSG_hi_Transport_Mode 0;
BA_ "GenSigSwitchedByIgnition" SG_ 2549088403 BedienSG_hi_Transport_Mode 0;
BA_ "GenSigSendType" SG_ 2549088403 KN_BedienSG_hi_BusKnockOut 0;
BA_ "GenSigSwitchedByIgnition" SG_ 2549088403 KN_BedienSG_hi_BusKnockOut 0;
BA_ "GenSigSendType" SG_ 2549088403 KN_BedienSG_hi_BusKnockOutTimer 0;
BA_ "GenSigSwitchedByIgnition" SG_ 2549088403 KN_BedienSG_hi_BusKnockOutTimer 0;
BA_ "GenSigSendType" SG_ 2549088403 KN_BedienSG_hi_ECUKnockOut 0;
BA_ "GenSigSwitchedByIgnition" SG_ 2549088403 KN_BedienSG_hi_ECUKnockOut 0;
BA_ "GenSigSendType" SG_ 2549088403 KN_BedienSG_hi_ECUKnockOutTimer 0;
BA_ "GenSigSwitchedByIgnition" SG_ 2549088403 KN_BedienSG_hi_ECUKnockOutTimer 0;
BA_ "GenSigSendType" SG_ 2549088403 NMH_BedienSG_hi_Lokalaktiv 0;
BA_ "GenSigSwitchedByIgnition" SG_ 2549088403 NMH_BedienSG_hi_Lokalaktiv 0;
BA_ "GenSigSendType" SG_ 2549088403 NMH_BedienSG_hi_Subsystemaktiv 0;
BA_ "GenSigSwitchedByIgnition" SG_ 2549088403 NMH_BedienSG_hi_Subsystemaktiv 0;
BA_ "GenSigSendType" SG_ 2549088403 NMH_BedienSG_hi_Wakeup 0;
BA_ "GenSigStartValue" SG_ 2549088403 NMH_BedienSG_hi_Wakeup 2;
BA_ "NWM-WakeupAllowed" SG_ 2549088403 NMH_BedienSG_hi_Wakeup 1;
BA_ "GenSigSendType" SG_ 2549088442 DDA_Abschaltstufe 0;
BA_ "GenSigSendType" SG_ 2549088442 DDA_KD_Fehler 0;
BA_ "GenSigSwitchedByIgnition" SG_ 2549088442 DDA_KD_Fehler 0;
BA_ "GenSigSendType" SG_ 2549088442 DDA_KompSchutz 0;
BA_ "GenSigSwitchedByIgnition" SG_ 2549088442 DDA_KompSchutz 0;
BA_ "GenSigSendType" SG_ 2549088442 DDA_Nachlauftyp 0;
BA_ "GenSigStartValue" SG_ 2549088442 DDA_Nachlauftyp 2;
BA_ "GenSigSwitchedByIgnition" SG_ 2549088442 DDA_Nachlauftyp 0;
BA_ "GenSigSendType" SG_ 2549088442 DDA_SNI 0;
BA_ "GenSigStartValue" SG_ 2549088442 DDA_SNI 186;
BA_ "GenSigSwitchedByIgnition" SG_ 2549088442 DDA_SNI 0;
BA_ "GenSigSendType" SG_ 2549088442 DDA_Transport_Mode 0;
BA_ "GenSigSwitchedByIgnition" SG_ 2549088442 DDA_Transport_Mode 0;
BA_ "GenSigSendType" SG_ 2549088442 KN_DDA_BusKnockOutTimer 0;
BA_ "GenSigSwitchedByIgnition" SG_ 2549088442 KN_DDA_BusKnockOutTimer 0;
BA_ "GenSigSendType" SG_ 2549088442 NM_DDA_Lokalaktiv 0;
BA_ "GenSigSwitchedByIgnition" SG_ 2549088442 NM_DDA_Lokalaktiv 0;
BA_ "GenSigSendType" SG_ 2549088442 NM_DDA_Wakeup 0;
BA_ "GenSigSwitchedByIgnition" SG_ 2549088442 NM_DDA_Wakeup 0;
BA_ "GenSigSendType" SG_ 2549088272 Gateway_Abschaltstufe 0;
BA_ "GenSigSwitchedByIgnition" SG_ 2549088272 Gateway_Abschaltstufe 0;
BA_ "GenSigSendType" SG_ 2549088272 Gateway_KompSchutz 0;
BA_ "GenSigSwitchedByIgnition" SG_ 2549088272 Gateway_KompSchutz 0;
BA_ "GenSigSendType" SG_ 2549088272 Gateway_Matrix_Generation 0;
BA_ "GenSigSwitchedByIgnition" SG_ 2549088272 Gateway_Matrix_Generation 0;
BA_ "GenSigSendType" SG_ 2549088272 Gateway_Matrix_Version 0;
BA_ "GenSigSwitchedByIgnition" SG_ 2549088272 Gateway_Matrix_Version 0;
BA_ "GenSigSendType" SG_ 2549088272 Gateway_Nachlauftyp 0;
BA_ "GenSigStartValue" SG_ 2549088272 Gateway_Nachlauftyp 2;
BA_ "GenSigSwitchedByIgnition" SG_ 2549088272 Gateway_Nachlauftyp 0;
BA_ "GenSigSendType" SG_ 2549088272 Gateway_SNI 0;
BA_ "GenSigStartValue" SG_ 2549088272 Gateway_SNI 16;
BA_ "GenSigSwitchedByIgnition" SG_ 2549088272 Gateway_SNI 0;
BA_ "GenSigSendType" SG_ 2549088272 Gateway_Transport_Mode 0;
BA_ "GenSigSwitchedByIgnition" SG_ 2549088272 Gateway_Transport_Mode 0;
BA_ "GenSigSendType" SG_ 2549088272 GW_KD_Fehler 0;
BA_ "GenSigSendType" SG_ 2549088272 NM_Gateway_Lokalaktiv 0;
BA_ "GenSigSwitchedByIgnition" SG_ 2549088272 NM_Gateway_Lokalaktiv 0;
BA_ "GenSigSendType" SG_ 2549088272 NM_Gateway_Subsystemaktiv 0;
BA_ "GenSigSendType" SG_ 2549088272 NM_Gateway_Wakeup 0;
BA_ "NWM-WakeupAllowed" SG_ 2549088272 NM_Gateway_Wakeup 1;
BA_ "GenSigSwitchedByIgnition" SG_ 2549088272 NM_Gateway_Wakeup 0;
BA_ "GenSigSendType" SG_ 2549088355 GM_Abschaltstufe 0;
BA_ "GenSigSendType" SG_ 2549088355 GM_KD_Fehler 0;
BA_ "GenSigSendType" SG_ 2549088355 GM_KompSchutz 0;
BA_ "GenSigSendType" SG_ 2549088355 GM_Lokalaktiv 0;
BA_ "GenSigSendType" SG_ 2549088355 GM_Nachlauftyp 0;
BA_ "GenSigSendType" SG_ 2549088355 GM_SNI 0;
BA_ "GenSigStartValue" SG_ 2549088355 GM_SNI 99;
BA_ "GenSigSendType" SG_ 2549088355 GM_Subsystemaktiv 0;
BA_ "GenSigSendType" SG_ 2549088355 GM_Transport_Mode 0;
BA_ "GenSigSendType" SG_ 2549088355 NM_GM_Wakeup 0;
BA_ "NWM-WakeupAllowed" SG_ 2549088355 NM_GM_Wakeup 1;
BA_ "GenSigSendType" SG_ 2549088371 Info_El_Abschaltstufe 0;
BA_ "GenSigSwitchedByIgnition" SG_ 2549088371 Info_El_Abschaltstufe 0;
BA_ "GenSigSendType" SG_ 2549088371 Info_El_KD_Fehler 0;
BA_ "GenSigSwitchedByIgnition" SG_ 2549088371 Info_El_KD_Fehler 0;
BA_ "GenSigSendType" SG_ 2549088371 Info_El_KompSchutz 0;
BA_ "GenSigSwitchedByIgnition" SG_ 2549088371 Info_El_KompSchutz 0;
BA_ "GenSigSendType" SG_ 2549088371 Info_El_Nachlauftyp 0;
BA_ "GenSigStartValue" SG_ 2549088371 Info_El_Nachlauftyp 2;
BA_ "GenSigSwitchedByIgnition" SG_ 2549088371 Info_El_Nachlauftyp 0;
BA_ "GenSigSendType" SG_ 2549088371 Info_El_SNI 0;
BA_ "GenSigStartValue" SG_ 2549088371 Info_El_SNI 115;
BA_ "GenSigSwitchedByIgnition" SG_ 2549088371 Info_El_SNI 0;
BA_ "GenSigSendType" SG_ 2549088371 Info_El_Transport_Mode 0;
BA_ "GenSigSwitchedByIgnition" SG_ 2549088371 Info_El_Transport_Mode 0;
BA_ "GenSigSendType" SG_ 2549088371 KN_Info_El_BusKnockOutTimer 0;
BA_ "GenSigStartValue" SG_ 2549088371 KN_Info_El_BusKnockOutTimer 255;
BA_ "GenSigSwitchedByIgnition" SG_ 2549088371 KN_Info_El_BusKnockOutTimer 0;
BA_ "GenSigSendType" SG_ 2549088371 NM_Info_El_Lokalaktiv 0;
BA_ "GenSigSwitchedByIgnition" SG_ 2549088371 NM_Info_El_Lokalaktiv 0;
BA_ "GenSigSendType" SG_ 2549088371 NM_Info_El_Subsystemaktiv 0;
BA_ "GenSigSwitchedByIgnition" SG_ 2549088371 NM_Info_El_Subsystemaktiv 0;
BA_ "GenSigSendType" SG_ 2549088371 NM_Info_El_Wakeup 0;
BA_ "NWM-WakeupAllowed" SG_ 2549088371 NM_Info_El_Wakeup 1;
BA_ "GenSigSwitchedByIgnition" SG_ 2549088371 NM_Info_El_Wakeup 0;
BA_ "GenSigSendType" SG_ 2549088258 NM_Sekundaer_02_Lokalaktiv 0;
BA_ "GenSigSwitchedByIgnition" SG_ 2549088258 NM_Sekundaer_02_Lokalaktiv 0;
BA_ "GenSigSendType" SG_ 2549088258 NM_Sekundaer_02_Subsystemaktiv 0;
BA_ "GenSigSwitchedByIgnition" SG_ 2549088258 NM_Sekundaer_02_Subsystemaktiv 0;
BA_ "GenSigSendType" SG_ 2549088258 NM_Sekundaer_02_Wakeup 0;
BA_ "GenSigSwitchedByIgnition" SG_ 2549088258 NM_Sekundaer_02_Wakeup 0;
BA_ "GenSigSendType" SG_ 2549088258 Sekundaer_02_Abschaltstufe 0;
BA_ "GenSigSwitchedByIgnition" SG_ 2549088258 Sekundaer_02_Abschaltstufe 0;
BA_ "GenSigSendType" SG_ 2549088258 Sekundaer_02_KD_Fehler 0;
BA_ "GenSigSwitchedByIgnition" SG_ 2549088258 Sekundaer_02_KD_Fehler 0;
BA_ "GenSigSendType" SG_ 2549088258 Sekundaer_02_KompSchutz 0;
BA_ "GenSigSwitchedByIgnition" SG_ 2549088258 Sekundaer_02_KompSchutz 0;
BA_ "GenSigSendType" SG_ 2549088258 Sekundaer_02_Nachlauftyp 0;
BA_ "GenSigStartValue" SG_ 2549088258 Sekundaer_02_Nachlauftyp 2;
BA_ "GenSigSwitchedByIgnition" SG_ 2549088258 Sekundaer_02_Nachlauftyp 0;
BA_ "GenSigSendType" SG_ 2549088258 Sekundaer_02_SNI 0;
BA_ "GenSigStartValue" SG_ 2549088258 Sekundaer_02_SNI 2;
BA_ "GenSigSwitchedByIgnition" SG_ 2549088258 Sekundaer_02_SNI 0;
BA_ "GenSigSendType" SG_ 2549088258 Sekundaer_02_Transport_Mode 0;
BA_ "GenSigSwitchedByIgnition" SG_ 2549088258 Sekundaer_02_Transport_Mode 0;
BA_ "GenSigSendType" SG_ 779 KBI_ABS_Lampe 0;
BA_ "GenSigSwitchedByIgnition" SG_ 779 KBI_ABS_Lampe 0;
BA_ "GenSigSendType" SG_ 779 KBI_Airbag_Lampe 0;
BA_ "GenSigSwitchedByIgnition" SG_ 779 KBI_Airbag_Lampe 0;
BA_ "GenSigSendType" SG_ 779 KBI_angez_Geschw 0;
BA_ "GenSigSwitchedByIgnition" SG_ 779 KBI_angez_Geschw 0;
BA_ "GenSigSendType" SG_ 779 KBI_Anzeigefehler_LDW 0;
BA_ "GenSigSwitchedByIgnition" SG_ 779 KBI_Anzeigefehler_LDW 0;
BA_ "GenSigSendType" SG_ 779 KBI_Anzeigefehler_NV 0;
BA_ "GenSigSwitchedByIgnition" SG_ 779 KBI_Anzeigefehler_NV 0;
BA_ "GenSigSendType" SG_ 779 KBI_Anzeigefehler_SWA 0;
BA_ "GenSigSwitchedByIgnition" SG_ 779 KBI_Anzeigefehler_SWA 0;
BA_ "GenSigSendType" SG_ 779 KBI_Anzeigestatus_ACC 0;
BA_ "GenSigSwitchedByIgnition" SG_ 779 KBI_Anzeigestatus_ACC 0;
BA_ "GenSigSendType" SG_ 779 KBI_Anzeigestatus_GRA 0;
BA_ "GenSigSwitchedByIgnition" SG_ 779 KBI_Anzeigestatus_GRA 0;
BA_ "Fehlerwert" SG_ 779 KBI_Anzeigestatus_GRA 3;
BA_ "GenSigSendType" SG_ 779 KBI_Anzeigestatus_LIM 0;
BA_ "GenSigSwitchedByIgnition" SG_ 779 KBI_Anzeigestatus_LIM 0;
BA_ "Fehlerwert" SG_ 779 KBI_Anzeigestatus_LIM 3;
BA_ "GenSigSendType" SG_ 779 KBI_ARA_in_Anzeige 0;
BA_ "GenSigSwitchedByIgnition" SG_ 779 KBI_ARA_in_Anzeige 0;
BA_ "GenSigSendType" SG_ 779 KBI_BKL_Lampe 0;
BA_ "GenSigSwitchedByIgnition" SG_ 779 KBI_BKL_Lampe 0;
BA_ "GenSigSendType" SG_ 779 KBI_Einheit_Tacho 0;
BA_ "GenSigSwitchedByIgnition" SG_ 779 KBI_Einheit_Tacho 0;
BA_ "GenSigSendType" SG_ 779 KBI_ESP_Lampe 0;
BA_ "GenSigSwitchedByIgnition" SG_ 779 KBI_ESP_Lampe 0;
BA_ "GenSigSendType" SG_ 779 KBI_Fehler_Anzeige_ACC 0;
BA_ "GenSigSwitchedByIgnition" SG_ 779 KBI_Fehler_Anzeige_ACC 0;
BA_ "GenSigSendType" SG_ 779 KBI_GRA_Hauptschalter 0;
BA_ "GenSigSwitchedByIgnition" SG_ 779 KBI_GRA_Hauptschalter 0;
BA_ "Fehlerwert" SG_ 779 KBI_GRA_Hauptschalter 3;
BA_ "GenSigSendType" SG_ 779 KBI_Handbremse 0;
BA_ "GenSigSwitchedByIgnition" SG_ 779 KBI_Handbremse 0;
BA_ "GenSigSendType" SG_ 779 KBI_im_Stellgliedtest 0;
BA_ "GenSigSwitchedByIgnition" SG_ 779 KBI_im_Stellgliedtest 0;
BA_ "GenSigSendType" SG_ 779 KBI_Konsistenz_ACC 0;
BA_ "GenSigSwitchedByIgnition" SG_ 779 KBI_Konsistenz_ACC 0;
BA_ "GenSigSendType" SG_ 779 KBI_Lenkung_Lampe 0;
BA_ "GenSigSwitchedByIgnition" SG_ 779 KBI_Lenkung_Lampe 0;
BA_ "GenSigSendType" SG_ 779 KBI_MFA_v_Einheit_01 0;
BA_ "GenSigSwitchedByIgnition" SG_ 779 KBI_MFA_v_Einheit_01 0;
BA_ "GenSigSendType" SG_ 779 KBI_NV_in_Anzeige 0;
BA_ "GenSigSwitchedByIgnition" SG_ 779 KBI_NV_in_Anzeige 0;
BA_ "GenSigSendType" SG_ 779 KBI_PLA_in_Anzeige 0;
BA_ "GenSigSwitchedByIgnition" SG_ 779 KBI_PLA_in_Anzeige 0;
BA_ "GenSigSendType" SG_ 779 KBI_SILA_gueltig 0;
BA_ "GenSigSwitchedByIgnition" SG_ 779 KBI_SILA_gueltig 0;
BA_ "GenSigSendType" SG_ 779 KBI_Systemstatus 0;
BA_ "GenSigSwitchedByIgnition" SG_ 779 KBI_Systemstatus 0;
BA_ "GenSigSendType" SG_ 779 KBI_Tankwarnung 0;
BA_ "GenSigSwitchedByIgnition" SG_ 779 KBI_Tankwarnung 0;
BA_ "GenSigSendType" SG_ 779 KBI_Tankwarnung_ungueltig 0;
BA_ "GenSigStartValue" SG_ 779 KBI_Tankwarnung_ungueltig 1;
BA_ "GenSigSwitchedByIgnition" SG_ 779 KBI_Tankwarnung_ungueltig 0;
BA_ "GenSigSendType" SG_ 779 KBI_Taster_Fahrwerk 0;
BA_ "GenSigSwitchedByIgnition" SG_ 779 KBI_Taster_Fahrwerk 0;
BA_ "GenSigSendType" SG_ 779 KBI_Taster_Lift 0;
BA_ "GenSigSwitchedByIgnition" SG_ 779 KBI_Taster_Lift 0;
BA_ "GenSigSendType" SG_ 779 KBI_V_Digital 0;
BA_ "GenSigSwitchedByIgnition" SG_ 779 KBI_V_Digital 0;
BA_ "GenSigSendType" SG_ 779 KBI_Vorglueh_System_Lampe 0;
BA_ "GenSigSwitchedByIgnition" SG_ 779 KBI_Vorglueh_System_Lampe 0;
BA_ "GenSigSendType" SG_ 779 Kombi_01_BZ 0;
BA_ "GenSigFuncType" SG_ 779 Kombi_01_BZ 1;
BA_ "GenSigSwitchedByIgnition" SG_ 779 Kombi_01_BZ 0;
BA_ "GenSigSendType" SG_ 1719 KBI_aktive_Laengsfunktion 3;
BA_ "GenSigSendType" SG_ 1719 KBI_Aussen_Temp_gef 0;
BA_ "GenSigStartValue" SG_ 1719 KBI_Aussen_Temp_gef 254;
BA_ "GenSigSwitchedByIgnition" SG_ 1719 KBI_Aussen_Temp_gef 0;
BA_ "Fehlerwert" SG_ 1719 KBI_Aussen_Temp_gef 255;
BA_ "GenSigSendType" SG_ 1719 KBI_FoD_PopUP_Quittiert 3;
BA_ "GenSigSendType" SG_ 1719 KBI_FStatus_Tank 0;
BA_ "GenSigSwitchedByIgnition" SG_ 1719 KBI_FStatus_Tank 0;
BA_ "GenSigSendType" SG_ 1719 KBI_GRA_im_ACC 3;
BA_ "GenSigSwitchedByIgnition" SG_ 1719 KBI_GRA_im_ACC 0;
BA_ "GenSigSendType" SG_ 1719 KBI_Inhalt_Tank 0;
BA_ "GenSigStartValue" SG_ 1719 KBI_Inhalt_Tank 126;
BA_ "GenSigSwitchedByIgnition" SG_ 1719 KBI_Inhalt_Tank 0;
BA_ "Fehlerwert" SG_ 1719 KBI_Inhalt_Tank 127;
BA_ "GenSigSendType" SG_ 1719 KBI_Kilometerstand 0;
BA_ "GenSigStartValue" SG_ 1719 KBI_Kilometerstand 1048574;
BA_ "GenSigSwitchedByIgnition" SG_ 1719 KBI_Kilometerstand 0;
BA_ "Fehlerwert" SG_ 1719 KBI_Kilometerstand 1048575;
BA_ "GenSigSendType" SG_ 1719 KBI_LVDS_Lock 3;
BA_ "GenSigSwitchedByIgnition" SG_ 1719 KBI_LVDS_Lock 0;
BA_ "GenSigSendType" SG_ 1719 KBI_Oelwechsel_durchgefuehrt 0;
BA_ "GenSigSwitchedByIgnition" SG_ 1719 KBI_Oelwechsel_durchgefuehrt 0;
BA_ "GenSigSendType" SG_ 1719 KBI_QBit_Aussen_Temp_gef 0;
BA_ "GenSigStartValue" SG_ 1719 KBI_QBit_Aussen_Temp_gef 1;
BA_ "GenSigSwitchedByIgnition" SG_ 1719 KBI_QBit_Aussen_Temp_gef 0;
BA_ "GenSigSendType" SG_ 1719 KBI_RDK_Kalibrier_Anf 3;
BA_ "GenSigSwitchedByIgnition" SG_ 1719 KBI_RDK_Kalibrier_Anf 0;
BA_ "GenSigSendType" SG_ 1719 KBI_Reserve_Warnung_Sek 3;
BA_ "GenSigSwitchedByIgnition" SG_ 1719 KBI_Reserve_Warnung_Sek 0;
BA_ "GenSigSendType" SG_ 1719 KBI_Standzeit_02 0;
BA_ "GenSigStartValue" SG_ 1719 KBI_Standzeit_02 131070;
BA_ "GenSigSwitchedByIgnition" SG_ 1719 KBI_Standzeit_02 0;
BA_ "Fehlerwert" SG_ 1719 KBI_Standzeit_02 131071;
BA_ "GenSigSendType" SG_ 1719 KBI_TA_gewaehlt_Fahrer 0;
BA_ "GenSigSendType" SG_ 1720 KBI_BCmE_aktiv 0;
BA_ "GenSigSwitchedByIgnition" SG_ 1720 KBI_BCmE_aktiv 0;
BA_ "GenSigSendType" SG_ 1720 KBI_GAP_Warn_Zeit_abgelaufen 0;
BA_ "GenSigSwitchedByIgnition" SG_ 1720 KBI_GAP_Warn_Zeit_abgelaufen 0;
BA_ "GenSigSendType" SG_ 1720 KBI_Max_Tankinhalt 0;
BA_ "GenSigStartValue" SG_ 1720 KBI_Max_Tankinhalt 254;
BA_ "GenSigSwitchedByIgnition" SG_ 1720 KBI_Max_Tankinhalt 0;
BA_ "Fehlerwert" SG_ 1720 KBI_Max_Tankinhalt 255;
BA_ "GenSigSendType" SG_ 1720 KBI_Nachtanken_erkannt 0;
BA_ "GenSigSwitchedByIgnition" SG_ 1720 KBI_Nachtanken_erkannt 0;
BA_ "GenSigSendType" SG_ 1720 KBI_Quittierung_cAQP 0;
BA_ "GenSigSwitchedByIgnition" SG_ 1720 KBI_Quittierung_cAQP 0;
BA_ "GenSigSendType" SG_ 1720 KBI_Quittierung_Naesse 0;
BA_ "GenSigSwitchedByIgnition" SG_ 1720 KBI_Quittierung_Naesse 0;
BA_ "GenSigSendType" SG_ 1720 KBI_Reifenumfang 0;
BA_ "GenSigFuncType" SG_ 1720 KBI_Reifenumfang 8;
BA_ "GenSigSwitchedByIgnition" SG_ 1720 KBI_Reifenumfang 0;
BA_ "GenSigSendType" SG_ 1720 KBI_Reifenumfang_Sekundaer 0;
BA_ "GenSigSwitchedByIgnition" SG_ 1720 KBI_Reifenumfang_Sekundaer 0;
BA_ "GenSigSendType" SG_ 1720 KBI_Sparhinweis_quittiert 0;
BA_ "GenSigSwitchedByIgnition" SG_ 1720 KBI_Sparhinweis_quittiert 0;
BA_ "GenSigSendType" SG_ 1720 KBI_Tankfuellstand_Prozent 0;
BA_ "GenSigStartValue" SG_ 1720 KBI_Tankfuellstand_Prozent 126;
BA_ "GenSigSwitchedByIgnition" SG_ 1720 KBI_Tankfuellstand_Prozent 0;
BA_ "Fehlerwert" SG_ 1720 KBI_Tankfuellstand_Prozent 127;
BA_ "GenSigSendType" SG_ 1720 KBI_Tankinhalt_hochaufl 0;
BA_ "GenSigStartValue" SG_ 1720 KBI_Tankinhalt_hochaufl 16382;
BA_ "GenSigSwitchedByIgnition" SG_ 1720 KBI_Tankinhalt_hochaufl 0;
BA_ "Fehlerwert" SG_ 1720 KBI_Tankinhalt_hochaufl 16383;
BA_ "GenSigSendType" SG_ 1720 KBI_Variante 0;
BA_ "GenSigSwitchedByIgnition" SG_ 1720 KBI_Variante 0;
BA_ "GenSigSendType" SG_ 1720 KBI_Variante_USA 0;
BA_ "GenSigSwitchedByIgnition" SG_ 1720 KBI_Variante_USA 0;
BA_ "GenSigSendType" SG_ 1724 KBI_Insp_dis 0;
BA_ "GenSigSwitchedByIgnition" SG_ 1724 KBI_Insp_dis 0;
BA_ "GenSigSendType" SG_ 1724 KBI_Insp_dis_status 0;
BA_ "GenSigSwitchedByIgnition" SG_ 1724 KBI_Insp_dis_status 0;
BA_ "GenSigSendType" SG_ 1724 KBI_Insp_dis_unit 0;
BA_ "GenSigSwitchedByIgnition" SG_ 1724 KBI_Insp_dis_unit 0;
BA_ "GenSigSendType" SG_ 1724 KBI_Insp_time 0;
BA_ "GenSigSwitchedByIgnition" SG_ 1724 KBI_Insp_time 0;
BA_ "GenSigSendType" SG_ 1724 KBI_Insp_time_status 0;
BA_ "GenSigSwitchedByIgnition" SG_ 1724 KBI_Insp_time_status 0;
BA_ "GenSigSendType" SG_ 1724 KBI_Oil_dis 0;
BA_ "GenSigSwitchedByIgnition" SG_ 1724 KBI_Oil_dis 0;
BA_ "GenSigSendType" SG_ 1724 KBI_Oil_dis_status 0;
BA_ "GenSigSwitchedByIgnition" SG_ 1724 KBI_Oil_dis_status 0;
BA_ "GenSigSendType" SG_ 1724 KBI_Oil_dis_unit 0;
BA_ "GenSigSwitchedByIgnition" SG_ 1724 KBI_Oil_dis_unit 0;
BA_ "GenSigSendType" SG_ 1724 KBI_Oil_time 0;
BA_ "GenSigSwitchedByIgnition" SG_ 1724 KBI_Oil_time 0;
BA_ "GenSigSendType" SG_ 1724 KBI_Oil_time_status 0;
BA_ "GenSigSwitchedByIgnition" SG_ 1724 KBI_Oil_time_status 0;
BA_ "GenSigSendType" SG_ 1724 KBI_Warnung_ID 0;
BA_ "GenSigSwitchedByIgnition" SG_ 1724 KBI_Warnung_ID 0;
BA_ "GenSigSendType" SG_ 2527679638 KBI_GZeit_HSek 3;
BA_ "GenSigSwitchedByIgnition" SG_ 2527679638 KBI_GZeit_HSek 0;
BA_ "GenSigSendType" SG_ 2527679638 KBI_GZeit_Min 3;
BA_ "GenSigSwitchedByIgnition" SG_ 2527679638 KBI_GZeit_Min 0;
BA_ "GenSigSendType" SG_ 2527679638 KBI_GZeit_Sek 3;
BA_ "GenSigSwitchedByIgnition" SG_ 2527679638 KBI_GZeit_Sek 0;
BA_ "GenSigSendType" SG_ 2527679638 KBI_GZeit_Std 3;
BA_ "GenSigSwitchedByIgnition" SG_ 2527679638 KBI_GZeit_Std 0;
BA_ "GenSigSendType" SG_ 2527679638 KBI_RZ_Nr 3;
BA_ "GenSigSwitchedByIgnition" SG_ 2527679638 KBI_RZ_Nr 0;
BA_ "GenSigSendType" SG_ 2527679638 KBI_RZeit_HSek 3;
BA_ "GenSigSwitchedByIgnition" SG_ 2527679638 KBI_RZeit_HSek 0;
BA_ "GenSigSendType" SG_ 2527679638 KBI_RZeit_Min 3;
BA_ "GenSigSwitchedByIgnition" SG_ 2527679638 KBI_RZeit_Min 0;
BA_ "GenSigSendType" SG_ 2527679638 KBI_RZeit_Sek 3;
BA_ "GenSigSwitchedByIgnition" SG_ 2527679638 KBI_RZeit_Sek 0;
BA_ "GenSigSendType" SG_ 2527679638 KBI_RZeit_Std 3;
BA_ "GenSigSwitchedByIgnition" SG_ 2527679638 KBI_RZeit_Std 0;
BA_ "GenSigSendType" SG_ 2527679638 KBI_Status_StoppUhr 3;
BA_ "GenSigSwitchedByIgnition" SG_ 2527679638 KBI_Status_StoppUhr 0;
BA_ "GenSigSendType" SG_ 2527679639 KBI_Jokerkey 3;
BA_ "GenSigSwitchedByIgnition" SG_ 2527679639 KBI_Jokerkey 0;
BA_ "GenSigSendType" SG_ 2527679639 KBI_RS_Druck_uebernehmen 3;
BA_ "GenSigSwitchedByIgnition" SG_ 2527679639 KBI_RS_Druck_uebernehmen 0;
BA_ "GenSigSendType" SG_ 2527679639 KBI_RS_Druckauswahl_Aktiv 3;
BA_ "GenSigSwitchedByIgnition" SG_ 2527679639 KBI_RS_Druckauswahl_Aktiv 0;
BA_ "GenSigSendType" SG_ 2527679639 KBI_RS_Mode_fortsetzen 3;
BA_ "GenSigSwitchedByIgnition" SG_ 2527679639 KBI_RS_Mode_fortsetzen 0;
BA_ "GenSigSendType" SG_ 2527679639 KBI_Rundstreckenmodus 3;
BA_ "GenSigSwitchedByIgnition" SG_ 2527679639 KBI_Rundstreckenmodus 0;
BA_ "GenSigSendType" SG_ 2527679639 KBI_Weg_Zaehler 3;
BA_ "GenSigSwitchedByIgnition" SG_ 2527679639 KBI_Weg_Zaehler 0;
BA_ "GenSigSendType" SG_ 2527679639 KBI_Weg_Zaehler_F 3;
BA_ "GenSigSwitchedByIgnition" SG_ 2527679639 KBI_Weg_Zaehler_F 0;
BA_ "Fehlerwert" SG_ 2527679639 KBI_Weg_Zaehler_F 1;
BA_ "GenSigSendType" SG_ 2527679656 KBI_StartupAnimation 3;
BA_ "GenSigSwitchedByIgnition" SG_ 2527679656 KBI_StartupAnimation 0;
BA_ "GenSigSendType" SG_ 2549875055 KS_AMP_Req_Data 3;
BA_ "GenSigFuncType" SG_ 2549875055 KS_AMP_Req_Data 9;
BA_ "GenSigSwitchedByIgnition" SG_ 2549875055 KS_AMP_Req_Data 0;
BA_ "GenSigSendType" SG_ 2550006127 KS_AMP_Resp_Data 3;
BA_ "GenSigFuncType" SG_ 2550006127 KS_AMP_Resp_Data 9;
BA_ "GenSigSwitchedByIgnition" SG_ 2550006127 KS_AMP_Resp_Data 0;
BA_ "GenSigSendType" SG_ 2549875059 KS_Info_El_Req_Data 3;
BA_ "GenSigFuncType" SG_ 2549875059 KS_Info_El_Req_Data 9;
BA_ "GenSigSwitchedByIgnition" SG_ 2549875059 KS_Info_El_Req_Data 0;
BA_ "GenSigSendType" SG_ 2550006131 KS_Info_El_Resp_Data 3;
BA_ "GenSigFuncType" SG_ 2550006131 KS_Info_El_Resp_Data 9;
BA_ "GenSigSwitchedByIgnition" SG_ 2550006131 KS_Info_El_Resp_Data 0;
BA_ "GenSigSendType" SG_ 2549875056 KS_Laufwerke_Req_Data 3;
BA_ "GenSigFuncType" SG_ 2549875056 KS_Laufwerke_Req_Data 9;
BA_ "GenSigSwitchedByIgnition" SG_ 2549875056 KS_Laufwerke_Req_Data 0;
BA_ "GenSigSendType" SG_ 2550006128 KS_Laufwerke_Resp_Data 3;
BA_ "GenSigFuncType" SG_ 2550006128 KS_Laufwerke_Resp_Data 9;
BA_ "GenSigSwitchedByIgnition" SG_ 2550006128 KS_Laufwerke_Resp_Data 0;
BA_ "GenSigSendType" SG_ 2549875053 KS_TV_Tuner_Req_Data 3;
BA_ "GenSigFuncType" SG_ 2549875053 KS_TV_Tuner_Req_Data 9;
BA_ "GenSigSwitchedByIgnition" SG_ 2549875053 KS_TV_Tuner_Req_Data 0;
BA_ "GenSigSendType" SG_ 2550006125 KS_TV_Tuner_Resp_Data 3;
BA_ "GenSigFuncType" SG_ 2550006125 KS_TV_Tuner_Resp_Data 9;
BA_ "GenSigSwitchedByIgnition" SG_ 2550006125 KS_TV_Tuner_Resp_Data 0;
BA_ "GenSigSendType" SG_ 701 LAE_Beta_confidence 0;
BA_ "GenSigSendType" SG_ 701 LAE_Beta_VZ 0;
BA_ "GenSigSendType" SG_ 701 LAE_BetaSlipAngle 0;
BA_ "GenSigStartValue" SG_ 701 LAE_BetaSlipAngle 254;
BA_ "GenSigSwitchedByIgnition" SG_ 701 LAE_BetaSlipAngle 0;
BA_ "Fehlerwert" SG_ 701 LAE_BetaSlipAngle 255;
BA_ "GenSigSendType" SG_ 701 LAE_BetaSlipAngle_02 0;
BA_ "GenSigStartValue" SG_ 701 LAE_BetaSlipAngle_02 32766;
BA_ "GenSigSwitchedByIgnition" SG_ 701 LAE_BetaSlipAngle_02 0;
BA_ "Fehlerwert" SG_ 701 LAE_BetaSlipAngle_02 32767;
BA_ "GenSigSendType" SG_ 701 LAE_mu 0;
BA_ "GenSigStartValue" SG_ 701 LAE_mu 62;
BA_ "Fehlerwert" SG_ 701 LAE_mu 63;
BA_ "GenSigSendType" SG_ 701 LAE_mu_confidence 0;
BA_ "GenSigSendType" SG_ 701 LAE_Vx 0;
BA_ "GenSigStartValue" SG_ 701 LAE_Vx 510;
BA_ "Fehlerwert" SG_ 701 LAE_Vx 511;
BA_ "GenSigSendType" SG_ 701 LAE_Vx_confidence 0;
BA_ "GenSigSendType" SG_ 701 LAE_Vx_VZ 0;
BA_ "GenSigSendType" SG_ 701 LAE_Vy 0;
BA_ "GenSigStartValue" SG_ 701 LAE_Vy 62;
BA_ "Fehlerwert" SG_ 701 LAE_Vy 63;
BA_ "GenSigSendType" SG_ 701 LAE_Vy_confidence 0;
BA_ "GenSigSendType" SG_ 2527679653 MXB_LAPP_Freigabe 3;
BA_ "GenSigSendType" SG_ 2527679653 MXB_LAPP_Status_FL 3;
BA_ "GenSigSendType" SG_ 2527679653 MXB_LAPP_Statuscode 3;
BA_ "GenSigStartValue" SG_ 2527679653 MXB_LAPP_Statuscode 1023;
BA_ "GenSigSendType" SG_ 2527679653 MXB_LAPP_ZR_Sondermodus_Anf 3;
BA_ "GenSigSendType" SG_ 2463978818 BTM_BrakeSystem_Status 3;
BA_ "Fehlerwert" SG_ 2463978818 BTM_BrakeSystem_Status 7;
BA_ "GenSigSendType" SG_ 2463978818 BTM_BrakeSystem_Text 3;
BA_ "GenSigSendType" SG_ 2463978818 BTM_BrakeSystem_Warnlampe 3;
BA_ "GenSigSendType" SG_ 2463978818 LCV_01_BZ 0;
BA_ "GenSigFuncType" SG_ 2463978818 LCV_01_BZ 1;
BA_ "GenSigSwitchedByIgnition" SG_ 2463978818 LCV_01_BZ 0;
BA_ "GenSigSendType" SG_ 2463978818 LCV_01_CRC 0;
BA_ "GenSigFuncType" SG_ 2463978818 LCV_01_CRC 2;
BA_ "GenSigSwitchedByIgnition" SG_ 2463978818 LCV_01_CRC 0;
BA_ "GenSigSendType" SG_ 2463978818 LCV_Aero_EngineBay_Cooling 3;
BA_ "GenSigSendType" SG_ 2463978818 LCV_Aero_Front_System_Status 3;
BA_ "GenSigSendType" SG_ 2463978818 LCV_Aero_Perf_Limit 3;
BA_ "GenSigSendType" SG_ 2463978818 LCV_Aero_Perf_Limit_Speed 3;
BA_ "GenSigStartValue" SG_ 2463978818 LCV_Aero_Perf_Limit_Speed 254;
BA_ "Fehlerwert" SG_ 2463978818 LCV_Aero_Perf_Limit_Speed 255;
BA_ "GenSigSendType" SG_ 2463978818 LCV_Aero_Rear_System_Status 3;
BA_ "GenSigSendType" SG_ 2463978818 LCV_BrakeGongTemp 3;
BA_ "GenSigSendType" SG_ 2463978818 LCV_DR_Systemstatus 3;
BA_ "GenSigSwitchedByIgnition" SG_ 2463978818 LCV_DR_Systemstatus 0;
BA_ "GenSigSendType" SG_ 2463978818 LCV_DR_Text 3;
BA_ "GenSigSwitchedByIgnition" SG_ 2463978818 LCV_DR_Text 0;
BA_ "GenSigSendType" SG_ 2463978818 LCV_DR_Warnlampe 3;
BA_ "GenSigSwitchedByIgnition" SG_ 2463978818 LCV_DR_Warnlampe 0;
BA_ "GenSigSendType" SG_ 2463978818 LCV_ESP_Zuschaltung 3;
BA_ "GenSigSendType" SG_ 2463978818 LCV_HD_offen 3;
BA_ "GenSigSwitchedByIgnition" SG_ 2463978818 LCV_HD_offen 0;
BA_ "GenSigSendType" SG_ 2463978818 LCV_Lift_Status 3;
BA_ "GenSigSwitchedByIgnition" SG_ 2463978818 LCV_Lift_Status 0;
BA_ "Fehlerwert" SG_ 2463978818 LCV_Lift_Status 7;
BA_ "GenSigSendType" SG_ 2463978818 LCV_Lift_Text 3;
BA_ "GenSigSendType" SG_ 2463978818 LCV_Lift_Warnlampe_Status 3;
BA_ "GenSigSendType" SG_ 2527679780 LCV_Aero_BarMode_Activation 3;
BA_ "GenSigSendType" SG_ 2527679780 LCV_Aero_Button_Default 3;
BA_ "GenSigSendType" SG_ 2527679780 LCV_Aero_Button_Range 3;
BA_ "GenSigSendType" SG_ 2527679780 LCV_Aero_Button_Select 3;
BA_ "GenSigSendType" SG_ 2527679780 LCV_Aero_Button_Tunable 3;
BA_ "GenSigSendType" SG_ 2527679780 LCV_BarMode_Allowed 3;
BA_ "GenSigSendType" SG_ 2527679780 LCV_DR_Button_Default 3;
BA_ "GenSigSendType" SG_ 2527679780 LCV_DR_Button_Range 3;
BA_ "GenSigSendType" SG_ 2527679780 LCV_DR_Button_Select 3;
BA_ "GenSigSendType" SG_ 2527679780 LCV_DR_Button_Tunable 3;
BA_ "GenSigSendType" SG_ 2463978684 BTM_BrakeDiscTemp_01 0;
BA_ "GenSigStartValue" SG_ 2463978684 BTM_BrakeDiscTemp_01 254;
BA_ "Fehlerwert" SG_ 2463978684 BTM_BrakeDiscTemp_01 255;
BA_ "GenSigSendType" SG_ 2463978684 BTM_BrakeDiscTemp_02 0;
BA_ "GenSigStartValue" SG_ 2463978684 BTM_BrakeDiscTemp_02 254;
BA_ "Fehlerwert" SG_ 2463978684 BTM_BrakeDiscTemp_02 255;
BA_ "GenSigSendType" SG_ 2463978684 BTM_BrakeDiscTemp_03 0;
BA_ "GenSigStartValue" SG_ 2463978684 BTM_BrakeDiscTemp_03 254;
BA_ "Fehlerwert" SG_ 2463978684 BTM_BrakeDiscTemp_03 255;
BA_ "GenSigSendType" SG_ 2463978684 BTM_BrakeDiscTemp_04 0;
BA_ "GenSigStartValue" SG_ 2463978684 BTM_BrakeDiscTemp_04 254;
BA_ "Fehlerwert" SG_ 2463978684 BTM_BrakeDiscTemp_04 255;
BA_ "GenSigSendType" SG_ 2463978684 BTM_BrakeFluidTemp_01 0;
BA_ "GenSigStartValue" SG_ 2463978684 BTM_BrakeFluidTemp_01 254;
BA_ "Fehlerwert" SG_ 2463978684 BTM_BrakeFluidTemp_01 255;
BA_ "GenSigSendType" SG_ 2463978684 BTM_BrakeFluidTemp_02 0;
BA_ "GenSigStartValue" SG_ 2463978684 BTM_BrakeFluidTemp_02 254;
BA_ "Fehlerwert" SG_ 2463978684 BTM_BrakeFluidTemp_02 255;
BA_ "GenSigSendType" SG_ 2463978684 BTM_BrakeFluidTemp_03 0;
BA_ "GenSigStartValue" SG_ 2463978684 BTM_BrakeFluidTemp_03 254;
BA_ "Fehlerwert" SG_ 2463978684 BTM_BrakeFluidTemp_03 255;
BA_ "GenSigSendType" SG_ 2463978684 BTM_BrakeFluidTemp_04 0;
BA_ "GenSigStartValue" SG_ 2463978684 BTM_BrakeFluidTemp_04 254;
BA_ "Fehlerwert" SG_ 2463978684 BTM_BrakeFluidTemp_04 255;
BA_ "GenSigSendType" SG_ 548 LCV_Aero_Front_Ratio 0;
BA_ "GenSigStartValue" SG_ 548 LCV_Aero_Front_Ratio 126;
BA_ "Fehlerwert" SG_ 548 LCV_Aero_Front_Ratio 127;
BA_ "GenSigSendType" SG_ 548 LCV_Aero_Long_Ratio 0;
BA_ "GenSigStartValue" SG_ 548 LCV_Aero_Long_Ratio 126;
BA_ "Fehlerwert" SG_ 548 LCV_Aero_Long_Ratio 127;
BA_ "GenSigSendType" SG_ 2589283974 BTM_BrakeDiscColour_01 0;
BA_ "GenSigSwitchedByIgnition" SG_ 2589283974 BTM_BrakeDiscColour_01 0;
BA_ "Fehlerwert" SG_ 2589283974 BTM_BrakeDiscColour_01 7;
BA_ "GenSigSendType" SG_ 2589283974 BTM_BrakeDiscColour_02 0;
BA_ "GenSigSwitchedByIgnition" SG_ 2589283974 BTM_BrakeDiscColour_02 0;
BA_ "Fehlerwert" SG_ 2589283974 BTM_BrakeDiscColour_02 7;
BA_ "GenSigSendType" SG_ 2589283974 BTM_BrakeDiscColour_03 0;
BA_ "GenSigSwitchedByIgnition" SG_ 2589283974 BTM_BrakeDiscColour_03 0;
BA_ "Fehlerwert" SG_ 2589283974 BTM_BrakeDiscColour_03 7;
BA_ "GenSigSendType" SG_ 2589283974 BTM_BrakeDiscColour_04 0;
BA_ "GenSigSwitchedByIgnition" SG_ 2589283974 BTM_BrakeDiscColour_04 0;
BA_ "Fehlerwert" SG_ 2589283974 BTM_BrakeDiscColour_04 7;
BA_ "GenSigSendType" SG_ 2589283974 BTM_BrakeFluidColour_01 0;
BA_ "GenSigSwitchedByIgnition" SG_ 2589283974 BTM_BrakeFluidColour_01 0;
BA_ "Fehlerwert" SG_ 2589283974 BTM_BrakeFluidColour_01 7;
BA_ "GenSigSendType" SG_ 2589283974 BTM_BrakeFluidColour_02 0;
BA_ "GenSigSwitchedByIgnition" SG_ 2589283974 BTM_BrakeFluidColour_02 0;
BA_ "Fehlerwert" SG_ 2589283974 BTM_BrakeFluidColour_02 7;
BA_ "GenSigSendType" SG_ 2589283974 BTM_BrakeFluidColour_03 0;
BA_ "GenSigSwitchedByIgnition" SG_ 2589283974 BTM_BrakeFluidColour_03 0;
BA_ "Fehlerwert" SG_ 2589283974 BTM_BrakeFluidColour_03 7;
BA_ "GenSigSendType" SG_ 2589283974 BTM_BrakeFluidColour_04 0;
BA_ "GenSigSwitchedByIgnition" SG_ 2589283974 BTM_BrakeFluidColour_04 0;
BA_ "Fehlerwert" SG_ 2589283974 BTM_BrakeFluidColour_04 7;
BA_ "GenSigSendType" SG_ 159 EPS_03_BZ 0;
BA_ "GenSigFuncType" SG_ 159 EPS_03_BZ 1;
BA_ "GenSigSwitchedByIgnition" SG_ 159 EPS_03_BZ 0;
BA_ "GenSigSendType" SG_ 159 EPS_03_CRC 0;
BA_ "GenSigFuncType" SG_ 159 EPS_03_CRC 2;
BA_ "GenSigSwitchedByIgnition" SG_ 159 EPS_03_CRC 0;
BA_ "GenSigSendType" SG_ 159 EPS_Berechneter_LW 0;
BA_ "GenSigStartValue" SG_ 159 EPS_Berechneter_LW 4094;
BA_ "GenSigSwitchedByIgnition" SG_ 159 EPS_Berechneter_LW 0;
BA_ "Fehlerwert" SG_ 159 EPS_Berechneter_LW 4095;
BA_ "GenSigSendType" SG_ 159 EPS_BLW_QBit 0;
BA_ "GenSigSwitchedByIgnition" SG_ 159 EPS_BLW_QBit 0;
BA_ "GenSigSendType" SG_ 159 EPS_DSR_Status_02 0;
BA_ "GenSigStartValue" SG_ 159 EPS_DSR_Status_02 14;
BA_ "GenSigSwitchedByIgnition" SG_ 159 EPS_DSR_Status_02 0;
BA_ "GenSigSendType" SG_ 159 EPS_HCA_Status_02 0;
BA_ "GenSigStartValue" SG_ 159 EPS_HCA_Status_02 14;
BA_ "GenSigSwitchedByIgnition" SG_ 159 EPS_HCA_Status_02 0;
BA_ "GenSigSendType" SG_ 159 EPS_Lenkmoment 0;
BA_ "GenSigStartValue" SG_ 159 EPS_Lenkmoment 1022;
BA_ "GenSigSwitchedByIgnition" SG_ 159 EPS_Lenkmoment 0;
BA_ "Fehlerwert" SG_ 159 EPS_Lenkmoment 1023;
BA_ "GenSigSendType" SG_ 159 EPS_Lenkmoment_QBit 0;
BA_ "GenSigSwitchedByIgnition" SG_ 159 EPS_Lenkmoment_QBit 0;
BA_ "GenSigSendType" SG_ 159 EPS_Lenkungstyp 0;
BA_ "GenSigStartValue" SG_ 159 EPS_Lenkungstyp 15;
BA_ "GenSigSwitchedByIgnition" SG_ 159 EPS_Lenkungstyp 0;
BA_ "GenSigSendType" SG_ 159 EPS_VZ_BLW 0;
BA_ "GenSigSwitchedByIgnition" SG_ 159 EPS_VZ_BLW 0;
BA_ "GenSigSendType" SG_ 159 EPS_VZ_Lenkmoment 0;
BA_ "GenSigSwitchedByIgnition" SG_ 159 EPS_VZ_Lenkmoment 0;
BA_ "GenSigSendType" SG_ 981 BCM1_Abblendlicht_Anf 0;
BA_ "GenSigSwitchedByIgnition" SG_ 981 BCM1_Abblendlicht_Anf 0;
BA_ "GenSigSendType" SG_ 981 BCM1_Adaptive_Lichtvert_Anf 0;
BA_ "GenSigSwitchedByIgnition" SG_ 981 BCM1_Adaptive_Lichtvert_Anf 0;
BA_ "GenSigSendType" SG_ 981 BCM1_Allwetterlicht_Anf 0;
BA_ "GenSigSwitchedByIgnition" SG_ 981 BCM1_Allwetterlicht_Anf 0;
BA_ "GenSigSendType" SG_ 981 BCM1_Animationssperrung 3;
BA_ "GenSigStartValue" SG_ 981 BCM1_Animationssperrung 1;
BA_ "GenSigSwitchedByIgnition" SG_ 981 BCM1_Animationssperrung 0;
BA_ "GenSigSendType" SG_ 981 BCM1_Autobahnlicht_Anf 0;
BA_ "GenSigSwitchedByIgnition" SG_ 981 BCM1_Autobahnlicht_Anf 0;
BA_ "GenSigSendType" SG_ 981 BCM1_CH_aktiv 0;
BA_ "NWM-WakeupAllowed" SG_ 981 BCM1_CH_aktiv 1;
BA_ "GenSigSwitchedByIgnition" SG_ 981 BCM1_CH_aktiv 0;
BA_ "GenSigSendType" SG_ 981 BCM1_CH_LH_aktiv 0;
BA_ "GenSigSwitchedByIgnition" SG_ 981 BCM1_CH_LH_aktiv 0;
BA_ "GenSigSendType" SG_ 981 BCM1_Fernlicht_Anf 0;
BA_ "GenSigSwitchedByIgnition" SG_ 981 BCM1_Fernlicht_Anf 0;
BA_ "GenSigSendType" SG_ 981 BCM1_FOD_Sperrung_Animationen_HL 3;
BA_ "GenSigStartValue" SG_ 981 BCM1_FOD_Sperrung_Animationen_HL 2;
BA_ "GenSigSendType" SG_ 981 BCM1_FoD_Sperrung_WiBli 3;
BA_ "GenSigStartValue" SG_ 981 BCM1_FoD_Sperrung_WiBli 2;
BA_ "GenSigSendType" SG_ 981 BCM1_Gleitende_Leuchtw_Anf 3;
BA_ "GenSigSwitchedByIgnition" SG_ 981 BCM1_Gleitende_Leuchtw_Anf 0;
BA_ "GenSigSendType" SG_ 981 BCM1_GLW_Fernlicht_Anf 3;
BA_ "GenSigSwitchedByIgnition" SG_ 981 BCM1_GLW_Fernlicht_Anf 0;
BA_ "GenSigSendType" SG_ 981 BCM1_Kurvenlicht_links_Anf 0;
BA_ "GenSigSwitchedByIgnition" SG_ 981 BCM1_Kurvenlicht_links_Anf 0;
BA_ "GenSigSendType" SG_ 981 BCM1_Kurvenlicht_rechts_Anf 0;
BA_ "GenSigSwitchedByIgnition" SG_ 981 BCM1_Kurvenlicht_rechts_Anf 0;
BA_ "GenSigSendType" SG_ 981 BCM1_LH_aktiv 0;
BA_ "NWM-WakeupAllowed" SG_ 981 BCM1_LH_aktiv 1;
BA_ "GenSigSwitchedByIgnition" SG_ 981 BCM1_LH_aktiv 0;
BA_ "GenSigSendType" SG_ 981 BCM1_Nebellicht_Anf 0;
BA_ "GenSigSwitchedByIgnition" SG_ 981 BCM1_Nebellicht_Anf 0;
BA_ "GenSigSendType" SG_ 981 BCM1_Nebelschluss_Ahg_Anf 0;
BA_ "GenSigSwitchedByIgnition" SG_ 981 BCM1_Nebelschluss_Ahg_Anf 0;
BA_ "GenSigSendType" SG_ 981 BCM1_Nebelschluss_Fzg_Anf 0;
BA_ "GenSigSwitchedByIgnition" SG_ 981 BCM1_Nebelschluss_Fzg_Anf 0;
BA_ "GenSigSendType" SG_ 981 BCM1_Parklicht_li_Anf 0;
BA_ "GenSigSwitchedByIgnition" SG_ 981 BCM1_Parklicht_li_Anf 0;
BA_ "GenSigSendType" SG_ 981 BCM1_Parklicht_re_Anf 0;
BA_ "GenSigSwitchedByIgnition" SG_ 981 BCM1_Parklicht_re_Anf 0;
BA_ "GenSigSendType" SG_ 981 BCM1_Regenlicht_Anf 0;
BA_ "GenSigSwitchedByIgnition" SG_ 981 BCM1_Regenlicht_Anf 0;
BA_ "GenSigSendType" SG_ 981 BCM1_Schlusslicht_Anf 0;
BA_ "GenSigSwitchedByIgnition" SG_ 981 BCM1_Schlusslicht_Anf 0;
BA_ "GenSigSendType" SG_ 981 BCM1_Schlusslicht_Signatur 0;
BA_ "GenSigSwitchedByIgnition" SG_ 981 BCM1_Schlusslicht_Signatur 0;
BA_ "GenSigSendType" SG_ 981 BCM1_Signaturlicht_Anf 0;
BA_ "GenSigSwitchedByIgnition" SG_ 981 BCM1_Signaturlicht_Anf 0;
BA_ "GenSigSendType" SG_ 981 BCM1_Standlicht_Anf 0;
BA_ "GenSigSwitchedByIgnition" SG_ 981 BCM1_Standlicht_Anf 0;
BA_ "GenSigSendType" SG_ 981 BCM1_Tagfahrlicht_Anf 0;
BA_ "GenSigSwitchedByIgnition" SG_ 981 BCM1_Tagfahrlicht_Anf 0;
BA_ "GenSigSendType" SG_ 981 BCM1_Touristen_Licht_Anf 0;
BA_ "GenSigSwitchedByIgnition" SG_ 981 BCM1_Touristen_Licht_Anf 0;
BA_ "GenSigSendType" SG_ 981 BCM1_Umfeldleuchten_Anf 0;
BA_ "GenSigSwitchedByIgnition" SG_ 981 BCM1_Umfeldleuchten_Anf 0;
BA_ "GenSigSendType" SG_ 981 BCM_Rueckfahrlicht_Anf 0;
BA_ "GenSigSwitchedByIgnition" SG_ 981 BCM_Rueckfahrlicht_Anf 0;
BA_ "GenSigSendType" SG_ 981 Licht_Anf_01_BZ 0;
BA_ "GenSigFuncType" SG_ 981 Licht_Anf_01_BZ 1;
BA_ "GenSigSwitchedByIgnition" SG_ 981 Licht_Anf_01_BZ 0;
BA_ "GenSigSendType" SG_ 981 Licht_Anf_01_CRC 0;
BA_ "GenSigFuncType" SG_ 981 Licht_Anf_01_CRC 2;
BA_ "GenSigSwitchedByIgnition" SG_ 981 Licht_Anf_01_CRC 0;
BA_REL_ "GenSigTimeoutTime" BU_SG_REL_ BedienDisp_vo SG_ 1719 KBI_Standzeit_02 5000;
BA_REL_ "GenSigTimeoutTime" BU_SG_REL_ BedienDisp_vo SG_ 1719 KBI_QBit_Aussen_Temp_gef 5000;
BA_REL_ "GenSigTimeoutTime" BU_SG_REL_ BedienDisp_vo SG_ 1719 KBI_Aussen_Temp_gef 5000;
BA_REL_ "GenSigTimeoutTime" BU_SG_REL_ BedienDisp_vo SG_ 2527679638 KBI_Status_StoppUhr 5000;
BA_REL_ "GenSigTimeoutTime" BU_SG_REL_ BedienDisp_vo SG_ 2527679638 KBI_GZeit_HSek 5000;
BA_REL_ "GenSigTimeoutTime" BU_SG_REL_ BedienDisp_vo SG_ 2527679638 KBI_GZeit_Min 5000;
BA_REL_ "GenSigTimeoutTime" BU_SG_REL_ BedienDisp_vo SG_ 2527679638 KBI_GZeit_Std 5000;
BA_REL_ "GenSigTimeoutTime" BU_SG_REL_ BedienDisp_vo SG_ 2527679638 KBI_GZeit_Sek 5000;
BA_REL_ "GenSigTimeoutTime" BU_SG_REL_ BedienSG_hi SG_ 779 KBI_MFA_v_Einheit_01 500;
BA_REL_ "GenSigTimeoutTime" BU_SG_REL_ BedienSG_hi SG_ 779 KBI_V_Digital 500;
BA_REL_ "GenSigTimeoutTime" BU_SG_REL_ BedienSG_hi SG_ 779 KBI_angez_Geschw 500;
BA_REL_ "GenSigTimeoutTime" BU_SG_REL_ BedienSG_hi SG_ 779 KBI_Einheit_Tacho 500;
BA_REL_ "GenSigTimeoutTime" BU_SG_REL_ BedienSG_hi SG_ 1719 KBI_Standzeit_02 5000;
BA_REL_ "GenSigTimeoutTime" BU_SG_REL_ BedienSG_hi SG_ 1719 KBI_QBit_Aussen_Temp_gef 5000;
BA_REL_ "GenSigTimeoutTime" BU_SG_REL_ BedienSG_hi SG_ 1719 KBI_Aussen_Temp_gef 5000;
BA_REL_ "GenSigTimeoutTime" BU_SG_REL_ BedienSG_hi SG_ 1720 KBI_Variante_USA 5000;
BA_REL_ "GenSigTimeoutTime" BU_SG_REL_ BedienSG_hi SG_ 1720 KBI_Variante 5000;
BA_REL_ "GenSigTimeoutTime" BU_SG_REL_ BedienSG_hi SG_ 1720 KBI_Tankfuellstand_Prozent 5000;
BA_REL_ "GenSigTimeoutTime" BU_SG_REL_ DDA SG_ 2527679653 MXB_LAPP_Freigabe 5000;
BA_REL_ "GenSigTimeoutTime" BU_SG_REL_ DDA SG_ 2527679653 MXB_LAPP_ZR_Sondermodus_Anf 5000;
BA_REL_ "GenSigTimeoutTime" BU_SG_REL_ DDA SG_ 2527679653 MXB_LAPP_Status_FL 5000;
BA_REL_ "GenSigTimeoutTime" BU_SG_REL_ DDA SG_ 2527679653 MXB_LAPP_Statuscode 5000;
BA_REL_ "GenSigTimeoutTime" BU_SG_REL_ Gateway SG_ 2549088398 BedienDisp_vo_Nachlauftyp 5000;
BA_REL_ "GenSigTimeoutTime" BU_SG_REL_ Gateway SG_ 2549088398 BedienDisp_vo_SNI 5000;
BA_REL_ "GenSigTimeoutTime" BU_SG_REL_ Gateway SG_ 2549088398 KN_BedienDisp_v_ECUKnockOutTimer 5000;
BA_REL_ "GenSigTimeoutTime" BU_SG_REL_ Gateway SG_ 2549088398 KN_BedienDisp_v_BusKnockOut 5000;
BA_REL_ "GenSigTimeoutTime" BU_SG_REL_ Gateway SG_ 2549088398 KN_BedienDisp_v_BusKnockOutTimer 5000;
BA_REL_ "GenSigTimeoutTime" BU_SG_REL_ Gateway SG_ 2549088398 KN_BedienDisp_v_ECUKnockOut 5000;
BA_REL_ "GenSigTimeoutTime" BU_SG_REL_ Gateway SG_ 2549088398 NMH_BedienDisp_vo_Lokalaktiv 5000;
BA_REL_ "GenSigTimeoutTime" BU_SG_REL_ Gateway SG_ 2549088398 BedienDisp_vo_KD_Fehler 2500;
BA_REL_ "GenSigTimeoutTime" BU_SG_REL_ Gateway SG_ 2549088403 BedienSG_hi_Nachlauftyp 5000;
BA_REL_ "GenSigTimeoutTime" BU_SG_REL_ Gateway SG_ 2549088403 BedienSG_hi_SNI 5000;
BA_REL_ "GenSigTimeoutTime" BU_SG_REL_ Gateway SG_ 2549088403 KN_BedienSG_hi_ECUKnockOutTimer 5000;
BA_REL_ "GenSigTimeoutTime" BU_SG_REL_ Gateway SG_ 2549088403 KN_BedienSG_hi_BusKnockOut 5000;
BA_REL_ "GenSigTimeoutTime" BU_SG_REL_ Gateway SG_ 2549088403 KN_BedienSG_hi_BusKnockOutTimer 5000;
BA_REL_ "GenSigTimeoutTime" BU_SG_REL_ Gateway SG_ 2549088403 KN_BedienSG_hi_ECUKnockOut 5000;
BA_REL_ "GenSigTimeoutTime" BU_SG_REL_ Gateway SG_ 2549088403 NMH_BedienSG_hi_Lokalaktiv 5000;
BA_REL_ "GenSigTimeoutTime" BU_SG_REL_ Gateway SG_ 2549088403 NMH_BedienSG_hi_Subsystemaktiv 5000;
BA_REL_ "GenSigTimeoutTime" BU_SG_REL_ Gateway SG_ 2549088403 BedienSG_hi_KD_Fehler 2500;
BA_REL_ "GenSigTimeoutTime" BU_SG_REL_ Gateway SG_ 2549088442 DDA_Nachlauftyp 5000;
BA_REL_ "GenSigTimeoutTime" BU_SG_REL_ Gateway SG_ 2549088442 DDA_SNI 5000;
BA_REL_ "GenSigTimeoutTime" BU_SG_REL_ Gateway SG_ 2549088442 KN_DDA_BusKnockOutTimer 5000;
BA_REL_ "GenSigTimeoutTime" BU_SG_REL_ Gateway SG_ 2549088442 NM_DDA_Lokalaktiv 5000;
BA_REL_ "GenSigTimeoutTime" BU_SG_REL_ Gateway SG_ 2549088442 DDA_KD_Fehler 2500;
BA_REL_ "GenSigTimeoutTime" BU_SG_REL_ Gateway SG_ 2549088355 GM_Nachlauftyp 5000;
BA_REL_ "GenSigTimeoutTime" BU_SG_REL_ Gateway SG_ 2549088355 GM_SNI 5000;
BA_REL_ "GenSigTimeoutTime" BU_SG_REL_ Gateway SG_ 2549088355 GM_Lokalaktiv 5000;
BA_REL_ "GenSigTimeoutTime" BU_SG_REL_ Gateway SG_ 2549088355 GM_KD_Fehler 2500;
BA_REL_ "GenSigTimeoutTime" BU_SG_REL_ Gateway SG_ 2549088371 Info_El_Nachlauftyp 5000;
BA_REL_ "GenSigTimeoutTime" BU_SG_REL_ Gateway SG_ 2549088371 Info_El_SNI 5000;
BA_REL_ "GenSigTimeoutTime" BU_SG_REL_ Gateway SG_ 2549088371 KN_Info_El_BusKnockOutTimer 5000;
BA_REL_ "GenSigTimeoutTime" BU_SG_REL_ Gateway SG_ 2549088371 NM_Info_El_Lokalaktiv 5000;
BA_REL_ "GenSigTimeoutTime" BU_SG_REL_ Gateway SG_ 2549088371 NM_Info_El_Subsystemaktiv 5000;
BA_REL_ "GenSigTimeoutTime" BU_SG_REL_ Gateway SG_ 2549088371 Info_El_KD_Fehler 2500;
BA_REL_ "GenSigTimeoutTime" BU_SG_REL_ Gateway_PAG SG_ 2549088398 BedienDisp_vo_Nachlauftyp 5000;
BA_REL_ "GenSigTimeoutTime" BU_SG_REL_ Gateway_PAG SG_ 2549088398 BedienDisp_vo_SNI 5000;
BA_REL_ "GenSigTimeoutTime" BU_SG_REL_ Gateway_PAG SG_ 2549088398 KN_BedienDisp_v_ECUKnockOutTimer 5000;
BA_REL_ "GenSigTimeoutTime" BU_SG_REL_ Gateway_PAG SG_ 2549088398 KN_BedienDisp_v_BusKnockOut 5000;
BA_REL_ "GenSigTimeoutTime" BU_SG_REL_ Gateway_PAG SG_ 2549088398 KN_BedienDisp_v_BusKnockOutTimer 5000;
BA_REL_ "GenSigTimeoutTime" BU_SG_REL_ Gateway_PAG SG_ 2549088398 KN_BedienDisp_v_ECUKnockOut 5000;
BA_REL_ "GenSigTimeoutTime" BU_SG_REL_ Gateway_PAG SG_ 2549088398 NMH_BedienDisp_vo_Lokalaktiv 5000;
BA_REL_ "GenSigTimeoutTime" BU_SG_REL_ Gateway_PAG SG_ 2549088398 BedienDisp_vo_KD_Fehler 2500;
BA_REL_ "GenSigTimeoutTime" BU_SG_REL_ Gateway_PAG SG_ 2549088403 BedienSG_hi_Nachlauftyp 5000;
BA_REL_ "GenSigTimeoutTime" BU_SG_REL_ Gateway_PAG SG_ 2549088403 BedienSG_hi_SNI 5000;
BA_REL_ "GenSigTimeoutTime" BU_SG_REL_ Gateway_PAG SG_ 2549088403 KN_BedienSG_hi_ECUKnockOutTimer 5000;
BA_REL_ "GenSigTimeoutTime" BU_SG_REL_ Gateway_PAG SG_ 2549088403 KN_BedienSG_hi_BusKnockOut 5000;
BA_REL_ "GenSigTimeoutTime" BU_SG_REL_ Gateway_PAG SG_ 2549088403 KN_BedienSG_hi_BusKnockOutTimer 5000;
BA_REL_ "GenSigTimeoutTime" BU_SG_REL_ Gateway_PAG SG_ 2549088403 KN_BedienSG_hi_ECUKnockOut 5000;
BA_REL_ "GenSigTimeoutTime" BU_SG_REL_ Gateway_PAG SG_ 2549088403 NMH_BedienSG_hi_Lokalaktiv 5000;
BA_REL_ "GenSigTimeoutTime" BU_SG_REL_ Gateway_PAG SG_ 2549088403 NMH_BedienSG_hi_Subsystemaktiv 5000;
BA_REL_ "GenSigTimeoutTime" BU_SG_REL_ Gateway_PAG SG_ 2549088403 BedienSG_hi_KD_Fehler 2500;
BA_REL_ "GenSigTimeoutTime" BU_SG_REL_ Gateway_PAG SG_ 2549088442 DDA_Nachlauftyp 5000;
BA_REL_ "GenSigTimeoutTime" BU_SG_REL_ Gateway_PAG SG_ 2549088442 DDA_SNI 5000;
BA_REL_ "GenSigTimeoutTime" BU_SG_REL_ Gateway_PAG SG_ 2549088442 KN_DDA_BusKnockOutTimer 5000;
BA_REL_ "GenSigTimeoutTime" BU_SG_REL_ Gateway_PAG SG_ 2549088442 NM_DDA_Lokalaktiv 5000;
BA_REL_ "GenSigTimeoutTime" BU_SG_REL_ Gateway_PAG SG_ 2549088442 DDA_KD_Fehler 2500;
BA_REL_ "GenSigTimeoutTime" BU_SG_REL_ Gateway_PAG SG_ 2549088371 Info_El_Nachlauftyp 5000;
BA_REL_ "GenSigTimeoutTime" BU_SG_REL_ Gateway_PAG SG_ 2549088371 Info_El_SNI 5000;
BA_REL_ "GenSigTimeoutTime" BU_SG_REL_ Gateway_PAG SG_ 2549088371 NM_Info_El_Lokalaktiv 5000;
BA_REL_ "GenSigTimeoutTime" BU_SG_REL_ Gateway_PAG SG_ 2549088371 NM_Info_El_Subsystemaktiv 5000;
BA_REL_ "GenSigTimeoutTime" BU_SG_REL_ Gateway_PAG SG_ 2549088371 Info_El_KD_Fehler 2500;
BA_REL_ "GenSigTimeoutTime" BU_SG_REL_ Gateway_PAG SG_ 2549088258 Sekundaer_02_Nachlauftyp 5000;
BA_REL_ "GenSigTimeoutTime" BU_SG_REL_ Gateway_PAG SG_ 2549088258 Sekundaer_02_SNI 5000;
BA_REL_ "GenSigTimeoutTime" BU_SG_REL_ Gateway_PAG SG_ 2549088258 Sekundaer_02_KD_Fehler 2500;
BA_REL_ "GenSigTimeoutTime" BU_SG_REL_ OTA_FC SG_ 2589283621 KL_ECO_PRO_Aktiv 5000;
BA_REL_ "GenSigTimeoutTime" BU_SG_REL_ OTA_FC SG_ 2589283621 KL_ACmax_Aktiv 5000;
BA_REL_ "GenSigTimeoutTime" BU_SG_REL_ OTA_FC SG_ 2589283621 KL_Defrost_Aktiv 5000;
BA_REL_ "GenSigTimeoutTime" BU_SG_REL_ OTA_FC SG_ 2589283621 KL_ECO_Aktiv 5000;
BA_REL_ "GenSigTimeoutTime" BU_SG_REL_ OTA_FC SG_ 2589283621 KL_Status_Klimastil 5000;
BA_REL_ "GenSigTimeoutTime" BU_SG_REL_ OTA_FC SG_ 2589283621 KL_Kundeneingriff_Geblaese 5000;
BA_REL_ "GenSigTimeoutTime" BU_SG_REL_ OTA_FC SG_ 2589283621 KL_Eps_Innen 5000;
BA_REL_ "GenSigTimeoutTime" BU_SG_REL_ OTA_FC SG_ 2589283621 KL_Sonnenintensitaet 5000;
BA_REL_ "GenSigTimeoutTime" BU_SG_REL_ OTA_FC SG_ 1712 FS_Temp_Scheibe 5000;
BA_REL_ "GenSigTimeoutTime" BU_SG_REL_ OTA_FC SG_ 1712 FS_Luftfeuchte_rel 5000;
BA_REL_ "GenSigTimeoutTime" BU_SG_REL_ OTA_FC SG_ 779 KBI_angez_Geschw 500;
BA_REL_ "GenSigTimeoutTime" BU_SG_REL_ OTA_FC SG_ 1719 KBI_aktive_Laengsfunktion 5000;
BA_REL_ "GenSigTimeoutTime" BU_SG_REL_ OTA_FC SG_ 1719 KBI_Aussen_Temp_gef 5000;
BA_REL_ "GenSigTimeoutTime" BU_SG_REL_ OTA_FC SG_ 981 BCM1_Abblendlicht_Anf 1000;
BA_REL_ "GenSigTimeoutTime" BU_SG_REL_ ZR_High SG_ 2589283621 KL_FlHz_Soll_VL 5000;
BA_REL_ "GenSigTimeoutTime" BU_SG_REL_ ZR_High SG_ 2589283621 KL_FlHz_Soll_HL 5000;
BA_REL_ "GenSigTimeoutTime" BU_SG_REL_ ZR_High SG_ 2589283621 KL_FlHz_Soll_VR 5000;
BA_REL_ "GenSigTimeoutTime" BU_SG_REL_ ZR_High SG_ 2589283621 KL_FlHz_Soll_HR 5000;
BA_REL_ "GenSigTimeoutTime" BU_SG_REL_ ZR_High SG_ 2589283621 KL_Umluft_Connect_status 5000;
BA_REL_ "GenSigTimeoutTime" BU_SG_REL_ ZR_High SG_ 2589283621 KL_ECO_PRO_Aktiv 5000;
BA_REL_ "GenSigTimeoutTime" BU_SG_REL_ ZR_High SG_ 2589283621 KL_ZR_Anforderung 5000;
BA_REL_ "GenSigTimeoutTime" BU_SG_REL_ ZR_High SG_ 2589283621 KL_ACmax_Aktiv 5000;
BA_REL_ "GenSigTimeoutTime" BU_SG_REL_ ZR_High SG_ 2589283621 KL_Defrost_Aktiv 5000;
BA_REL_ "GenSigTimeoutTime" BU_SG_REL_ ZR_High SG_ 2589283621 KL_ECO_Aktiv 5000;
BA_REL_ "GenSigTimeoutTime" BU_SG_REL_ ZR_High SG_ 2589283621 KL_Status_Klimastil 5000;
BA_REL_ "GenSigTimeoutTime" BU_SG_REL_ ZR_High SG_ 2589283621 KL_Kundeneingriff_Geblaese 5000;
BA_REL_ "GenSigTimeoutTime" BU_SG_REL_ ZR_High SG_ 2589283621 KL_Eps_Innen 5000;
BA_REL_ "GenSigTimeoutTime" BU_SG_REL_ ZR_High SG_ 2589283621 KL_Sonnenintensitaet 5000;
BA_REL_ "GenSigTimeoutTime" BU_SG_REL_ ZR_High SG_ 992 KL_Fond_Fuss_Temp_hl 1000;
BA_REL_ "GenSigTimeoutTime" BU_SG_REL_ ZR_High SG_ 992 KL_SL_Soll_hl 1000;
BA_REL_ "GenSigTimeoutTime" BU_SG_REL_ ZR_High SG_ 992 KL_SL_Soll_hr 1000;
BA_REL_ "GenSigTimeoutTime" BU_SG_REL_ ZR_High SG_ 992 KL_Fond_Fuss_Temp_hr 1000;
BA_REL_ "GenSigTimeoutTime" BU_SG_REL_ ZR_High SG_ 992 KL_SH_Soll_hl 1000;
BA_REL_ "GenSigTimeoutTime" BU_SG_REL_ ZR_High SG_ 992 KL_SH_Soll_hr 1000;
BA_REL_ "GenSigTimeoutTime" BU_SG_REL_ ZR_High SG_ 992 KL_MA_Temp_hl 1000;
BA_REL_ "GenSigTimeoutTime" BU_SG_REL_ ZR_High SG_ 992 KL_Fehler_Umluft 1000;
BA_REL_ "GenSigTimeoutTime" BU_SG_REL_ ZR_High SG_ 992 KL_MA_Temp_hr 1000;
BA_REL_ "GenSigTimeoutTime" BU_SG_REL_ ZR_High SG_ 992 KL_Fehler_Fussraum_Klappen 1000;
BA_REL_ "GenSigTimeoutTime" BU_SG_REL_ ZR_High SG_ 992 KL_Fehler_Temp_Klappen 1000;
BA_REL_ "GenSigTimeoutTime" BU_SG_REL_ ZR_High SG_ 992 KL_Fehler_Temp_MA_Klappen 1000;
BA_REL_ "GenSigTimeoutTime" BU_SG_REL_ ZR_High SG_ 1712 FS_Taupunkt 5000;
BA_REL_ "GenSigTimeoutTime" BU_SG_REL_ ZR_High SG_ 1712 FS_Temp_Scheibe 5000;
BA_REL_ "GenSigTimeoutTime" BU_SG_REL_ ZR_High SG_ 1712 FS_Temp_Sensor 5000;
BA_REL_ "GenSigTimeoutTime" BU_SG_REL_ ZR_High SG_ 605 KLR_Touchauswertung 5000;
BA_REL_ "GenSigTimeoutTime" BU_SG_REL_ ZR_High SG_ 779 KBI_ABS_Lampe 500;
BA_REL_ "GenSigTimeoutTime" BU_SG_REL_ ZR_High SG_ 779 KBI_ESP_Lampe 500;
BA_REL_ "GenSigTimeoutTime" BU_SG_REL_ ZR_High SG_ 779 KBI_BKL_Lampe 500;
BA_REL_ "GenSigTimeoutTime" BU_SG_REL_ ZR_High SG_ 779 KBI_Airbag_Lampe 500;
BA_REL_ "GenSigTimeoutTime" BU_SG_REL_ ZR_High SG_ 779 KBI_Vorglueh_System_Lampe 500;
BA_REL_ "GenSigTimeoutTime" BU_SG_REL_ ZR_High SG_ 779 KBI_NV_in_Anzeige 500;
BA_REL_ "GenSigTimeoutTime" BU_SG_REL_ ZR_High SG_ 779 KBI_Anzeigestatus_ACC 500;
BA_REL_ "GenSigTimeoutTime" BU_SG_REL_ ZR_High SG_ 779 KBI_Anzeigestatus_GRA 500;
BA_REL_ "GenSigTimeoutTime" BU_SG_REL_ ZR_High SG_ 779 KBI_Tankwarnung 500;
BA_REL_ "GenSigTimeoutTime" BU_SG_REL_ ZR_High SG_ 779 KBI_MFA_v_Einheit_01 500;
BA_REL_ "GenSigTimeoutTime" BU_SG_REL_ ZR_High SG_ 779 KBI_Tankwarnung_ungueltig 500;
BA_REL_ "GenSigTimeoutTime" BU_SG_REL_ ZR_High SG_ 779 KBI_V_Digital 500;
BA_REL_ "GenSigTimeoutTime" BU_SG_REL_ ZR_High SG_ 779 KBI_PLA_in_Anzeige 500;
BA_REL_ "GenSigTimeoutTime" BU_SG_REL_ ZR_High SG_ 779 KBI_ARA_in_Anzeige 500;
BA_REL_ "GenSigTimeoutTime" BU_SG_REL_ ZR_High SG_ 779 KBI_angez_Geschw 500;
BA_REL_ "GenSigTimeoutTime" BU_SG_REL_ ZR_High SG_ 779 KBI_Einheit_Tacho 500;
BA_REL_ "GenSigTimeoutTime" BU_SG_REL_ ZR_High SG_ 779 KBI_Fehler_Anzeige_ACC 500;
BA_REL_ "GenSigTimeoutTime" BU_SG_REL_ ZR_High SG_ 779 KBI_Anzeigefehler_SWA 500;
BA_REL_ "GenSigTimeoutTime" BU_SG_REL_ ZR_High SG_ 1719 KBI_Standzeit_02 5000;
BA_REL_ "GenSigTimeoutTime" BU_SG_REL_ ZR_High SG_ 1719 KBI_LVDS_Lock 5000;
BA_REL_ "GenSigTimeoutTime" BU_SG_REL_ ZR_High SG_ 1719 KBI_Reserve_Warnung_Sek 5000;
BA_REL_ "GenSigTimeoutTime" BU_SG_REL_ ZR_High SG_ 1719 KBI_FStatus_Tank 5000;
BA_REL_ "GenSigTimeoutTime" BU_SG_REL_ ZR_High SG_ 1719 KBI_aktive_Laengsfunktion 5000;
BA_REL_ "GenSigTimeoutTime" BU_SG_REL_ ZR_High SG_ 1719 KBI_Oelwechsel_durchgefuehrt 5000;
BA_REL_ "GenSigTimeoutTime" BU_SG_REL_ ZR_High SG_ 1719 KBI_QBit_Aussen_Temp_gef 5000;
BA_REL_ "GenSigTimeoutTime" BU_SG_REL_ ZR_High SG_ 1720 KBI_Reifenumfang 5000;
BA_REL_ "GenSigTimeoutTime" BU_SG_REL_ ZR_High SG_ 1720 KBI_Variante_USA 5000;
BA_REL_ "GenSigTimeoutTime" BU_SG_REL_ ZR_High SG_ 1720 KBI_Tankfuellstand_Prozent 5000;
BA_REL_ "GenSigTimeoutTime" BU_SG_REL_ ZR_High SG_ 1720 KBI_Nachtanken_erkannt 5000;
BA_REL_ "GenSigTimeoutTime" BU_SG_REL_ ZR_High SG_ 1720 KBI_Max_Tankinhalt 5000;
BA_REL_ "GenSigTimeoutTime" BU_SG_REL_ ZR_High SG_ 1724 KBI_Oil_dis_status 5000;
BA_REL_ "GenSigTimeoutTime" BU_SG_REL_ ZR_High SG_ 1724 KBI_Oil_dis_unit 5000;
BA_REL_ "GenSigTimeoutTime" BU_SG_REL_ ZR_High SG_ 1724 KBI_Oil_dis 5000;
BA_REL_ "GenSigTimeoutTime" BU_SG_REL_ ZR_High SG_ 1724 KBI_Oil_time_status 5000;
BA_REL_ "GenSigTimeoutTime" BU_SG_REL_ ZR_High SG_ 1724 KBI_Oil_time 5000;
BA_REL_ "GenSigTimeoutTime" BU_SG_REL_ ZR_High SG_ 1724 KBI_Insp_dis_status 5000;
BA_REL_ "GenSigTimeoutTime" BU_SG_REL_ ZR_High SG_ 1724 KBI_Insp_dis_unit 5000;
BA_REL_ "GenSigTimeoutTime" BU_SG_REL_ ZR_High SG_ 1724 KBI_Insp_dis 5000;
BA_REL_ "GenSigTimeoutTime" BU_SG_REL_ ZR_High SG_ 1724 KBI_Insp_time_status 5000;
BA_REL_ "GenSigTimeoutTime" BU_SG_REL_ ZR_High SG_ 1724 KBI_Insp_time 5000;
BA_REL_ "GenSigTimeoutTime" BU_SG_REL_ ZR_High SG_ 1724 KBI_Warnung_ID 5000;
BA_REL_ "GenSigTimeoutTime" BU_SG_REL_ ZR_High SG_ 2527679638 KBI_RZ_Nr 5000;
BA_REL_ "GenSigTimeoutTime" BU_SG_REL_ ZR_High SG_ 2527679638 KBI_Status_StoppUhr 5000;
BA_REL_ "GenSigTimeoutTime" BU_SG_REL_ ZR_High SG_ 2527679638 KBI_GZeit_HSek 5000;
BA_REL_ "GenSigTimeoutTime" BU_SG_REL_ ZR_High SG_ 2527679638 KBI_GZeit_Min 5000;
BA_REL_ "GenSigTimeoutTime" BU_SG_REL_ ZR_High SG_ 2527679638 KBI_GZeit_Std 5000;
BA_REL_ "GenSigTimeoutTime" BU_SG_REL_ ZR_High SG_ 2527679638 KBI_GZeit_Sek 5000;
BA_REL_ "GenSigTimeoutTime" BU_SG_REL_ ZR_High SG_ 2527679638 KBI_RZeit_HSek 5000;
BA_REL_ "GenSigTimeoutTime" BU_SG_REL_ ZR_High SG_ 2527679638 KBI_RZeit_Min 5000;
BA_REL_ "GenSigTimeoutTime" BU_SG_REL_ ZR_High SG_ 2527679638 KBI_RZeit_Sek 5000;
BA_REL_ "GenSigTimeoutTime" BU_SG_REL_ ZR_High SG_ 2527679638 KBI_RZeit_Std 5000;
BA_REL_ "GenSigTimeoutTime" BU_SG_REL_ ZR_High SG_ 2527679639 KBI_Weg_Zaehler_F 5000;
BA_REL_ "GenSigTimeoutTime" BU_SG_REL_ ZR_High SG_ 2527679639 KBI_Weg_Zaehler 5000;
BA_REL_ "GenSigTimeoutTime" BU_SG_REL_ ZR_High SG_ 2527679656 KBI_StartupAnimation 5000;
BA_REL_ "GenSigTimeoutTime" BU_SG_REL_ ZR_High SG_ 2527679653 MXB_LAPP_ZR_Sondermodus_Anf 5000;
BA_REL_ "GenSigTimeoutTime" BU_SG_REL_ ZR_High SG_ 981 BCM1_Kurvenlicht_links_Anf 1000;
BA_REL_ "GenSigTimeoutTime" BU_SG_REL_ ZR_High SG_ 981 BCM1_Kurvenlicht_rechts_Anf 1000;
BA_REL_ "GenSigTimeoutTime" BU_SG_REL_ ZR_High SG_ 981 BCM1_Standlicht_Anf 1000;
BA_REL_ "GenSigTimeoutTime" BU_SG_REL_ ZR_High SG_ 981 BCM1_Abblendlicht_Anf 1000;
BA_REL_ "GenSigTimeoutTime" BU_SG_REL_ ZR_High SG_ 981 BCM1_Fernlicht_Anf 1000;
BA_REL_ "GenSigTimeoutTime" BU_SG_REL_ ZR_High SG_ 981 BCM1_Nebellicht_Anf 1000;
BA_REL_ "GenSigTimeoutTime" BU_SG_REL_ ZR_High SG_ 981 BCM1_Parklicht_li_Anf 1000;
BA_REL_ "GenSigTimeoutTime" BU_SG_REL_ ZR_High SG_ 981 BCM1_Parklicht_re_Anf 1000;
BA_REL_ "GenSigTimeoutTime" BU_SG_REL_ ZR_High SG_ 981 BCM1_Nebelschluss_Ahg_Anf 1000;
BA_REL_ "GenSigTimeoutTime" BU_SG_REL_ ZR_High SG_ 981 BCM1_Nebelschluss_Fzg_Anf 1000;
BA_REL_ "GenSigTimeoutTime" BU_SG_REL_ ZR_High SG_ 981 BCM1_Schlusslicht_Anf 1000;
BA_REL_ "GenSigTimeoutTime" BU_SG_REL_ ZR_High SG_ 981 BCM_Rueckfahrlicht_Anf 1000;
BA_REL_ "GenSigTimeoutTime" BU_SG_REL_ ZR_High SG_ 981 BCM1_Umfeldleuchten_Anf 1000;
BA_REL_ "GenSigTimeoutTime" BU_SG_REL_ ZR_High SG_ 981 BCM1_Tagfahrlicht_Anf 1000;
BA_REL_ "GenSigTimeoutTime" BU_SG_REL_ ZR_High SG_ 981 BCM1_Regenlicht_Anf 1000;
BA_REL_ "GenSigTimeoutTime" BU_SG_REL_ ZR_High SG_ 981 BCM1_Autobahnlicht_Anf 1000;
BA_REL_ "GenSigTimeoutTime" BU_SG_REL_ ZR_High SG_ 981 BCM1_Touristen_Licht_Anf 1000;
BA_REL_ "GenSigTimeoutTime" BU_SG_REL_ ZR_High SG_ 981 BCM1_CH_aktiv 1000;
BA_REL_ "GenSigTimeoutTime" BU_SG_REL_ ZR_High SG_ 981 BCM1_LH_aktiv 1000;
BA_REL_ "GenSigTimeoutTime" BU_SG_REL_ ZR_High SG_ 981 BCM1_Gleitende_Leuchtw_Anf 1000;
BA_REL_ "GenSigTimeoutTime" BU_SG_REL_ ZR_High SG_ 981 BCM1_GLW_Fernlicht_Anf 1000;
BA_REL_ "GenSigTimeoutTime" BU_SG_REL_ ZR_High SG_ 981 BCM1_Adaptive_Lichtvert_Anf 1000;
BA_REL_ "GenSigTimeoutTime" BU_SG_REL_ ZR_High SG_ 981 BCM1_CH_LH_aktiv 1000;
BA_REL_ "GenSigTimeoutTime" BU_SG_REL_ ZR_High SG_ 981 BCM1_Allwetterlicht_Anf 1000;
BA_REL_ "GenSigTimeoutTime" BU_SG_REL_ ZR_LIMU SG_ 2589283621 KL_ZR_Anforderung 5000;
BA_REL_ "GenSigTimeoutTime" BU_SG_REL_ ZR_LIMU SG_ 1505 BCM1_Aussen_Temp_ungef 5000;
BA_REL_ "GenSigTimeoutTime" BU_SG_REL_ ZR_LIMU SG_ 779 KBI_Tankwarnung 500;
BA_REL_ "GenSigTimeoutTime" BU_SG_REL_ ZR_LIMU SG_ 779 KBI_MFA_v_Einheit_01 500;
BA_REL_ "GenSigTimeoutTime" BU_SG_REL_ ZR_LIMU SG_ 779 KBI_Tankwarnung_ungueltig 500;
BA_REL_ "GenSigTimeoutTime" BU_SG_REL_ ZR_LIMU SG_ 779 KBI_V_Digital 500;
BA_REL_ "GenSigTimeoutTime" BU_SG_REL_ ZR_LIMU SG_ 779 KBI_angez_Geschw 500;
BA_REL_ "GenSigTimeoutTime" BU_SG_REL_ ZR_LIMU SG_ 1719 KBI_Reserve_Warnung_Sek 5000;
BA_REL_ "GenSigTimeoutTime" BU_SG_REL_ ZR_LIMU SG_ 1719 KBI_FStatus_Tank 5000;
BA_REL_ "GenSigTimeoutTime" BU_SG_REL_ ZR_LIMU SG_ 2527679638 KBI_RZ_Nr 5000;
BA_REL_ "GenSigTimeoutTime" BU_SG_REL_ ZR_LIMU SG_ 2527679638 KBI_Status_StoppUhr 5000;
BA_REL_ "GenSigTimeoutTime" BU_SG_REL_ ZR_LIMU SG_ 2527679638 KBI_GZeit_HSek 5000;
BA_REL_ "GenSigTimeoutTime" BU_SG_REL_ ZR_LIMU SG_ 2527679638 KBI_GZeit_Min 5000;
BA_REL_ "GenSigTimeoutTime" BU_SG_REL_ ZR_LIMU SG_ 2527679638 KBI_GZeit_Std 5000;
BA_REL_ "GenSigTimeoutTime" BU_SG_REL_ ZR_LIMU SG_ 2527679638 KBI_GZeit_Sek 5000;
BA_REL_ "GenSigTimeoutTime" BU_SG_REL_ ZR_LIMU SG_ 2527679638 KBI_RZeit_HSek 5000;
BA_REL_ "GenSigTimeoutTime" BU_SG_REL_ ZR_LIMU SG_ 2527679638 KBI_RZeit_Min 5000;
BA_REL_ "GenSigTimeoutTime" BU_SG_REL_ ZR_LIMU SG_ 2527679638 KBI_RZeit_Sek 5000;
BA_REL_ "GenSigTimeoutTime" BU_SG_REL_ ZR_LIMU SG_ 2527679638 KBI_RZeit_Std 5000;
BA_REL_ "GenSigTimeoutTime" BU_SG_REL_ ZR_LIMU SG_ 2527679639 KBI_Weg_Zaehler_F 5000;
BA_REL_ "GenSigTimeoutTime" BU_SG_REL_ ZR_LIMU SG_ 2527679639 KBI_Weg_Zaehler 5000;
BA_REL_ "GenSigTimeoutTime" BU_SG_REL_ ZR_LIMU SG_ 2527679639 KBI_Jokerkey 5000;
BA_REL_ "GenSigTimeoutTime" BU_SG_REL_ ZR_LIMU SG_ 701 LAE_BetaSlipAngle_02 500;
BA_REL_ "GenSigTimeoutTime" BU_SG_REL_ ZR_LIMU SG_ 701 LAE_Vx_VZ 500;
BA_REL_ "GenSigTimeoutTime" BU_SG_REL_ ZR_LIMU SG_ 701 LAE_mu_confidence 500;
BA_REL_ "GenSigTimeoutTime" BU_SG_REL_ ZR_LIMU SG_ 701 LAE_mu 500;
BA_REL_ "GenSigTimeoutTime" BU_SG_REL_ ZR_LIMU SG_ 701 LAE_Vy 500;
BA_REL_ "GenSigTimeoutTime" BU_SG_REL_ ZR_LIMU SG_ 701 LAE_Vy_confidence 500;
BA_REL_ "GenSigTimeoutTime" BU_SG_REL_ ZR_LIMU SG_ 701 LAE_BetaSlipAngle 500;
BA_REL_ "GenSigTimeoutTime" BU_SG_REL_ ZR_LIMU SG_ 701 LAE_Beta_VZ 500;
BA_REL_ "GenSigTimeoutTime" BU_SG_REL_ ZR_LIMU SG_ 701 LAE_Beta_confidence 500;
BA_REL_ "GenSigTimeoutTime" BU_SG_REL_ ZR_LIMU SG_ 701 LAE_Vx_confidence 500;
BA_REL_ "GenSigTimeoutTime" BU_SG_REL_ ZR_LIMU SG_ 701 LAE_Vx 500;
BA_REL_ "GenSigTimeoutTime" BU_SG_REL_ ZR_LIMU SG_ 2463978818 BTM_BrakeSystem_Status 3200;
BA_REL_ "GenSigTimeoutTime" BU_SG_REL_ ZR_LIMU SG_ 2463978818 BTM_BrakeSystem_Text 3200;
BA_REL_ "GenSigTimeoutTime" BU_SG_REL_ ZR_LIMU SG_ 2463978818 BTM_BrakeSystem_Warnlampe 3200;
BA_REL_ "GenSigTimeoutTime" BU_SG_REL_ ZR_LIMU SG_ 2463978818 LCV_Lift_Status 3200;
BA_REL_ "GenSigTimeoutTime" BU_SG_REL_ ZR_LIMU SG_ 2463978818 LCV_HD_offen 3200;
BA_REL_ "GenSigTimeoutTime" BU_SG_REL_ ZR_LIMU SG_ 2527679780 LCV_Aero_BarMode_Activation 5000;
BA_REL_ "GenSigTimeoutTime" BU_SG_REL_ ZR_LIMU SG_ 2527679780 LCV_Aero_Button_Default 5000;
BA_REL_ "GenSigTimeoutTime" BU_SG_REL_ ZR_LIMU SG_ 2527679780 LCV_Aero_Button_Range 5000;
BA_REL_ "GenSigTimeoutTime" BU_SG_REL_ ZR_LIMU SG_ 2527679780 LCV_Aero_Button_Select 5000;
BA_REL_ "GenSigTimeoutTime" BU_SG_REL_ ZR_LIMU SG_ 2527679780 LCV_Aero_Button_Tunable 5000;
BA_REL_ "GenSigTimeoutTime" BU_SG_REL_ ZR_LIMU SG_ 2527679780 LCV_DR_Button_Default 5000;
BA_REL_ "GenSigTimeoutTime" BU_SG_REL_ ZR_LIMU SG_ 2527679780 LCV_DR_Button_Range 5000;
BA_REL_ "GenSigTimeoutTime" BU_SG_REL_ ZR_LIMU SG_ 2527679780 LCV_DR_Button_Select 5000;
BA_REL_ "GenSigTimeoutTime" BU_SG_REL_ ZR_LIMU SG_ 2527679780 LCV_DR_Button_Tunable 5000;
BA_REL_ "GenSigTimeoutTime" BU_SG_REL_ ZR_LIMU SG_ 2463978684 BTM_BrakeDiscTemp_01 1000;
BA_REL_ "GenSigTimeoutTime" BU_SG_REL_ ZR_LIMU SG_ 2463978684 BTM_BrakeDiscTemp_02 1000;
BA_REL_ "GenSigTimeoutTime" BU_SG_REL_ ZR_LIMU SG_ 2463978684 BTM_BrakeDiscTemp_03 1000;
BA_REL_ "GenSigTimeoutTime" BU_SG_REL_ ZR_LIMU SG_ 2463978684 BTM_BrakeDiscTemp_04 1000;
BA_REL_ "GenSigTimeoutTime" BU_SG_REL_ ZR_LIMU SG_ 2463978684 BTM_BrakeFluidTemp_01 1000;
BA_REL_ "GenSigTimeoutTime" BU_SG_REL_ ZR_LIMU SG_ 2463978684 BTM_BrakeFluidTemp_02 1000;
BA_REL_ "GenSigTimeoutTime" BU_SG_REL_ ZR_LIMU SG_ 2463978684 BTM_BrakeFluidTemp_03 1000;
BA_REL_ "GenSigTimeoutTime" BU_SG_REL_ ZR_LIMU SG_ 2463978684 BTM_BrakeFluidTemp_04 1000;
BA_REL_ "GenSigTimeoutTime" BU_SG_REL_ ZR_LIMU SG_ 548 LCV_Aero_Front_Ratio 500;
BA_REL_ "GenSigTimeoutTime" BU_SG_REL_ ZR_LIMU SG_ 548 LCV_Aero_Long_Ratio 500;
BA_REL_ "GenSigTimeoutTime" BU_SG_REL_ ZR_LIMU SG_ 2589283974 BTM_BrakeDiscColour_01 5000;
BA_REL_ "GenSigTimeoutTime" BU_SG_REL_ ZR_LIMU SG_ 2589283974 BTM_BrakeDiscColour_02 5000;
BA_REL_ "GenSigTimeoutTime" BU_SG_REL_ ZR_LIMU SG_ 2589283974 BTM_BrakeDiscColour_03 5000;
BA_REL_ "GenSigTimeoutTime" BU_SG_REL_ ZR_LIMU SG_ 2589283974 BTM_BrakeDiscColour_04 5000;
BA_REL_ "GenSigTimeoutTime" BU_SG_REL_ ZR_LIMU SG_ 2589283974 BTM_BrakeFluidColour_01 5000;
BA_REL_ "GenSigTimeoutTime" BU_SG_REL_ ZR_LIMU SG_ 2589283974 BTM_BrakeFluidColour_02 5000;
BA_REL_ "GenSigTimeoutTime" BU_SG_REL_ ZR_LIMU SG_ 2589283974 BTM_BrakeFluidColour_03 5000;
BA_REL_ "GenSigTimeoutTime" BU_SG_REL_ ZR_LIMU SG_ 2589283974 BTM_BrakeFluidColour_04 5000;
BA_REL_ "GenSigTimeoutTime" BU_SG_REL_ ZR_MIB_TOP_ab_Gen3 SG_ 2589283621 KL_ZR_Anforderung 5000;
BA_REL_ "GenSigTimeoutTime" BU_SG_REL_ ZR_MIB_TOP_ab_Gen3 SG_ 779 KBI_Tankwarnung 500;
BA_REL_ "GenSigTimeoutTime" BU_SG_REL_ ZR_MIB_TOP_ab_Gen3 SG_ 779 KBI_MFA_v_Einheit_01 500;
BA_REL_ "GenSigTimeoutTime" BU_SG_REL_ ZR_MIB_TOP_ab_Gen3 SG_ 779 KBI_Tankwarnung_ungueltig 500;
BA_REL_ "GenSigTimeoutTime" BU_SG_REL_ ZR_MIB_TOP_ab_Gen3 SG_ 779 KBI_V_Digital 500;
BA_REL_ "GenSigTimeoutTime" BU_SG_REL_ ZR_MIB_TOP_ab_Gen3 SG_ 779 KBI_angez_Geschw 500;
BA_REL_ "GenSigTimeoutTime" BU_SG_REL_ ZR_MIB_TOP_ab_Gen3 SG_ 1719 KBI_Reserve_Warnung_Sek 5000;
BA_REL_ "GenSigTimeoutTime" BU_SG_REL_ ZR_MIB_TOP_ab_Gen3 SG_ 1719 KBI_FStatus_Tank 5000;
BA_REL_ "GenSigTimeoutTime" BU_SG_REL_ ZR_MIB_TOP_ab_Gen3 SG_ 1720 KBI_Nachtanken_erkannt 5000;
BA_REL_ "GenSigTimeoutTime" BU_SG_REL_ ZR_MIB_TOP_ab_Gen3 SG_ 2527679638 KBI_RZ_Nr 5000;
BA_REL_ "GenSigTimeoutTime" BU_SG_REL_ ZR_MIB_TOP_ab_Gen3 SG_ 2527679638 KBI_Status_StoppUhr 5000;
BA_REL_ "GenSigTimeoutTime" BU_SG_REL_ ZR_MIB_TOP_ab_Gen3 SG_ 2527679638 KBI_GZeit_HSek 5000;
BA_REL_ "GenSigTimeoutTime" BU_SG_REL_ ZR_MIB_TOP_ab_Gen3 SG_ 2527679638 KBI_GZeit_Min 5000;
BA_REL_ "GenSigTimeoutTime" BU_SG_REL_ ZR_MIB_TOP_ab_Gen3 SG_ 2527679638 KBI_GZeit_Std 5000;
BA_REL_ "GenSigTimeoutTime" BU_SG_REL_ ZR_MIB_TOP_ab_Gen3 SG_ 2527679638 KBI_GZeit_Sek 5000;
BA_REL_ "GenSigTimeoutTime" BU_SG_REL_ ZR_MIB_TOP_ab_Gen3 SG_ 2527679638 KBI_RZeit_HSek 5000;
BA_REL_ "GenSigTimeoutTime" BU_SG_REL_ ZR_MIB_TOP_ab_Gen3 SG_ 2527679638 KBI_RZeit_Min 5000;
BA_REL_ "GenSigTimeoutTime" BU_SG_REL_ ZR_MIB_TOP_ab_Gen3 SG_ 2527679638 KBI_RZeit_Sek 5000;
BA_REL_ "GenSigTimeoutTime" BU_SG_REL_ ZR_MIB_TOP_ab_Gen3 SG_ 2527679638 KBI_RZeit_Std 5000;
BA_REL_ "GenSigTimeoutTime" BU_SG_REL_ ZR_MIB_TOP_ab_Gen3 SG_ 2527679639 KBI_Weg_Zaehler_F 5000;
BA_REL_ "GenSigTimeoutTime" BU_SG_REL_ ZR_MIB_TOP_ab_Gen3 SG_ 2527679639 KBI_Weg_Zaehler 5000;
BA_REL_ "GenSigTimeoutTime" BU_SG_REL_ ZR_MIB_TOP_ab_Gen3 SG_ 2527679639 KBI_Jokerkey 5000;
BA_REL_ "GenSigTimeoutTime" BU_SG_REL_ ZR_MIB_TOP_ab_Gen3 SG_ 159 EPS_Berechneter_LW 1000;
BA_REL_ "GenSigTimeoutTime" BU_SG_REL_ ZR_MIB_TOP_ab_Gen3 SG_ 981 BCM_Rueckfahrlicht_Anf 1000;
BA_REL_ "GenSigTimeoutTime" BU_SG_REL_ ZR_Standard SG_ 2589283621 KL_Umluft_Connect_status 5000;
BA_REL_ "GenSigTimeoutTime" BU_SG_REL_ ZR_Standard SG_ 2589283621 KL_ZR_Anforderung 5000;
BA_REL_ "GenSigTimeoutTime" BU_SG_REL_ ZR_Standard SG_ 779 KBI_Tankwarnung 500;
BA_REL_ "GenSigTimeoutTime" BU_SG_REL_ ZR_Standard SG_ 779 KBI_MFA_v_Einheit_01 500;
BA_REL_ "GenSigTimeoutTime" BU_SG_REL_ ZR_Standard SG_ 779 KBI_Tankwarnung_ungueltig 500;
BA_REL_ "GenSigTimeoutTime" BU_SG_REL_ ZR_Standard SG_ 779 KBI_V_Digital 500;
BA_REL_ "GenSigTimeoutTime" BU_SG_REL_ ZR_Standard SG_ 779 KBI_angez_Geschw 500;
BA_REL_ "GenSigTimeoutTime" BU_SG_REL_ ZR_Standard SG_ 1719 KBI_Standzeit_02 5000;
BA_REL_ "GenSigTimeoutTime" BU_SG_REL_ ZR_Standard SG_ 1719 KBI_Reserve_Warnung_Sek 5000;
BA_REL_ "GenSigTimeoutTime" BU_SG_REL_ ZR_Standard SG_ 1719 KBI_FStatus_Tank 5000;
BA_REL_ "GenSigTimeoutTime" BU_SG_REL_ ZR_Standard SG_ 1719 KBI_Aussen_Temp_gef 5000;
BA_REL_ "GenSigTimeoutTime" BU_SG_REL_ ZR_Standard SG_ 1720 KBI_Reifenumfang 5000;
BA_REL_ "GenSigTimeoutTime" BU_SG_REL_ ZR_Standard SG_ 2527679653 MXB_LAPP_ZR_Sondermodus_Anf 5000;
BA_REL_ "GenSigTimeoutTime" BU_SG_REL_ ZR_Standard SG_ 981 BCM_Rueckfahrlicht_Anf 1000;
VAL_ 2589283621 KL_NV_Energie_Anf 254 "Init" 255 "Fehler" ;
VAL_ 2589283621 KL_Umluft_Connect_status 0 "Keine_Umluft" 1 "Umluft_Kundenwunsch" 2 "Umluft_AQS" 3 "Umluft_Backend_Empfehlung" 4 "Umluft_Navi_Daten" ;
VAL_ 2589283621 KL_ECO_PRO_Aktiv 0 "inaktiv" 1 "aktiv" ;
VAL_ 2589283621 KL_QBit_Sonnenintensitaet 0 "gueltiger_Wert" 1 "Ersatz_Init_oder_Fehlerwert" ;
VAL_ 2589283621 KL_ZR_Anforderung 0 "init" 1 "inaktiv" 2 "aktiv" 3 "reserviert" ;
VAL_ 2589283621 KL_ACmax_Aktiv 0 "inaktiv" 1 "aktiv" ;
VAL_ 2589283621 KL_Defrost_Aktiv 0 "inaktiv" 1 "aktiv" ;
VAL_ 2589283621 KL_ECO_Aktiv 0 "inaktiv" 1 "aktiv" ;
VAL_ 2589283621 KL_Status_Klimastil 0 "Modus_1" 1 "Modus_2" 2 "Modus_3" 3 "Modus_4" ;
VAL_ 2589283621 KL_Kundeneingriff_Geblaese 0 "Kein_Kundeneingriff_Geblaese" 1 "Kundeneingriff_Geblaese_aktiv" ;
VAL_ 2589283621 KL_Thermischer_Bedarf 0 "Aus" 1 "Heizen" 2 "Nachlauf_Heizen" 3 "Lueften" 4 "Kuehlen" 6 "Init" 7 "Fehler" ;
VAL_ 2589283621 KL_Eps_Innen 254 "Init" 255 "Fehler" ;
VAL_ 2589283621 KL_Sonnenintensitaet 254 "Init" 255 "Fehler" ;
VAL_ 992 KL_Fond_Fuss_Temp_hl 1022 "Init" 1023 "Fehler" ;
VAL_ 992 KL_Fond_Fuss_Temp_hr 1022 "Init" 1023 "Fehler" ;
VAL_ 992 KL_MA_Temp_hl 1022 "Init" 1023 "Fehler" ;
VAL_ 992 KL_SIH_Takt_hl 0 "Aus" 1 "Ein" ;
VAL_ 992 KL_SIH_Takt_hr 0 "Aus" 1 "Ein" ;
VAL_ 992 KL_Fehler_Umluft 0 "Umluftklappe_iO" 1 "Umluftklappe_niO" ;
VAL_ 992 KL_RAB 0 "keine_Auswirkung_auf_Klimasystem" 1 "Fehler_hat_Auswirkung_auf_die_Klimatisierung" ;
VAL_ 992 KL_Fond_Absperrventil 0 "nicht angesteuert" 1 "wird angesteuert" ;
VAL_ 992 KL_Fond_KD_Fehler 0 "kein_KD_Fehler" 1 "KD_Fehler" ;
VAL_ 992 KL_MA_Temp_hr 1022 "Init" 1023 "Fehler" ;
VAL_ 992 KL_Fehler_Fussraum_Klappen 0 "kein_Fehler" 1 "Fehler_Fuss_li" 2 "Fehler_Fuss_re" 3 "Beide_Klappen_defekt" ;
VAL_ 992 KL_Fehler_Temp_Klappen 0 "kein_Fehler" 1 "Fehler_Temp_li" 2 "Fehler_Temp_re" 3 "Beide_Klappen_defekt" ;
VAL_ 992 KL_Fehler_Temp_MA_Klappen 0 "kein_Fehler" 1 "Fehler_MA_li" 2 "Fehler_MA_re" 3 "Beide_Klappen_defekt" ;
VAL_ 1712 FS_Taupunkt 0 "nicht verfuegbar" 1023 "Fehler" ;
VAL_ 1712 FS_ResponseError 0 "normal" 1 "Fehler" ;
VAL_ 1712 FS_Temp_Scheibe 0 "nicht verfuegbar" 1023 "Fehler" ;
VAL_ 1712 FS_Temp_Sensor 0 "nicht verfuegbar" 255 "Fehler" ;
VAL_ 1712 FS_Luftfeuchte_rel 0 "nicht verfuegbar" 255 "Fehler" ;
VAL_ 1505 BCM1_Aussen_Temp_ungef 253 "nicht_verbaut" 254 "Initwert" 255 "Fehler" ;
VAL_ 1505 BCM_Heizungsabsperrventil_Status 0 "HAV_offen" 1 "HAV_geschlossen" 2 "Init_oder_nicht_verbaut" 3 "Fehler" ;
VAL_ 1505 BCM_Heizungspumpe_Status 0 "Pumpe_aus" 1 "Pumpe_aktiv_und_Stauts_iO" 2 "Init_oder_nicht_verbaut" 3 "Fehler" ;
VAL_ 1505 BCM_Kompressorkupplung_Status 0 "Kupplung_offen" 1 "Kupplung_geschlossen" 2 "Init_oder_nicht_verbaut" 3 "Fehler" ;
VAL_ 1505 BCM1_PTC_stufig_Status 0 "Aus" 1 "Stufe_1_aktiv" 2 "Stufe_2_aktiv" 3 "Stufe_3_aktiv" 6 "Init_oder_nicht_verbaut" 7 "Fehler" ;
VAL_ 1505 BCM1_FStatus_Aussentemp_ungef 0 "iO" 1 "niO" ;
VAL_ 1505 BCM1_Kompressorstrom_ist 254 "Init, bzw. nicht verfuegbar" 255 "Fehler" ;
VAL_ 1505 BCM1_OBD_FStatus_ATemp 0 "kein Fehler / Init / nicht verbaut" 1 "KS- (Kurzschluss nach minus)" 2 "KS+ (Kurzschluss nach plus)" 3 "OC (Leitungsunterbrechung)" 4 "OOR+ (Signal zu gross)" 5 "OOR- (Signal zu klein)" 6 "RC+ (Signal unplausibel zu gross)" 7 "RC- (Signal unplausibel zu klein)" 8 "KS+/OC (Kurzschluss nach plus/Unterbrechung)" 9 "KS-/OC  (Kurzschluss nach minus/Unterbrechung)" 10 "KS-/KS+  (Kurzschluss nach minus/plus)" 11 "KS-/KS+/OC (Kurzschluss nach minus/plus/Unterbrechung)" 12 "frei" 13 "frei" 14 "frei" 15 "frei" ;
VAL_ 605 KLR_Fehler 0 "kein_Fehler" 1 "Fehler" ;
VAL_ 605 KLR_ResponseError 0 "normal" 1 "Fehler" ;
VAL_ 605 KLR_Lokalaktiv 0 "war_nicht_lokal_aktiv" 1 "war_lokal_aktiv" ;
VAL_ 605 KLR_Fehler_Codierung 0 "Kein_Fehler" 1 "Fehler" ;
VAL_ 605 KLR_Touchintensitaet_1 251 "Kalibrierung" 252 "nicht_verfuegbar" 253 "res" 254 "Init" 255 "Fehler" ;
VAL_ 605 KLR_Touchintensitaet_2 251 "Kalibrierung" 252 "nicht_verfuegbar" 253 "res" 254 "Init" 255 "Fehler" ;
VAL_ 605 KLR_Touchintensitaet_3 251 "Kalibrierung" 252 "nicht_verfuegbar" 253 "res" 254 "Init" 255 "Fehler" ;
VAL_ 605 KLR_Touchauswertung 0 "Keine_Beruehrung" 1 "Leicht_beruehrt_innen" 2 "Leicht_beruehrt_links" 3 "Leicht_beruehrt_rechts" 4 "Leicht_beruehrt_links_rechts" 5 "Leicht_umgriffen_links" 6 "Leicht_umgriffen_rechts" 7 "Leicht_umgriffen_links_rechts" 8 "Stark_umgriffen_links" 9 "Stark_umgriffen_rechts" 10 "Stark_umgriffen_links_rechts" 11 "res" 12 "res" 13 "Kalibrierung" 14 "Init" 15 "Fehler_Touchauswertung" ;
VAL_ 2549088398 BedienDisp_vo_KompSchutz 0 "inaktiv" 1 "aktiv" ;
VAL_ 2549088398 BedienDisp_vo_Abschaltstufe 0 "keine_Einschraenkung" 1 "Funktionseinschraenkung" ;
VAL_ 2549088398 BedienDisp_vo_Transport_Mode 0 "keine_Einschraenkung" 1 "Funktionseinschraenkung" ;
VAL_ 2549088398 BedienDisp_vo_Nachlauftyp 0 "Komm_bei_KL15_EIN" 1 "Komm_nach_KL15_AUS" 2 "Komm_bei_KL15_AUS" ;
VAL_ 2549088398 BedienDisp_vo_SNI 142 "BedienDisp_vo" ;
VAL_ 2549088398 KN_BedienDisp_v_ECUKnockOutTimer 63 "ECUKnockOut_deaktiviert" ;
VAL_ 2549088398 KN_BedienDisp_v_BusKnockOut 0 "Funktion_nicht_ausgeloest" 1 "Veto_aktiv" 2 "Funktion_ausgeloest" 3 "Funktion_deaktiviert" ;
VAL_ 2549088398 KN_BedienDisp_v_BusKnockOutTimer 255 "BusKnockOut_deaktiviert" ;
VAL_ 2549088398 NM_BedienDisp_vo_Wakeup 0 "Peripherie_Wakeup__Ursache_nicht_bekannt" 1 "Bus_Wakeup" 2 "KL15_HW" 3 "Restwaerme_Menuauswahl" 4 "SAD_Taster" ;
VAL_ 2549088398 KN_BedienDisp_v_ECUKnockOut 0 "Funktion_nicht_ausgeloest" 1 "Veto_war_aktiv" 2 "Funktion_ausgeloest" 3 "Funktion_deaktiviert" ;
VAL_ 2549088398 NMH_BedienDisp_vo_Lokalaktiv 0 "war_nicht_lokal_aktiv" 1 "war_lokal_aktiv" ;
VAL_ 2549088398 NMH_BedienDisp_vo_Subsystemaktiv 0 "Subsystem_war_nicht_lokalaktiv" 1 "war_lokalaktiv" ;
VAL_ 2549088398 BedienDisp_vo_KD_Fehler 0 "kein_KD_Fehler" 1 "KD_Fehler" ;
VAL_ 2549088403 BedienSG_hi_KompSchutz 0 "inaktiv" 1 "aktiv" ;
VAL_ 2549088403 BedienSG_hi_Abschaltstufe 0 "keine_Einschraenkung" 1 "Funktionseinschraenkung" ;
VAL_ 2549088403 BedienSG_hi_Transport_Mode 0 "keine_Einschraenkung" 1 "Funktionseinschraenkung" ;
VAL_ 2549088403 BedienSG_hi_Nachlauftyp 0 "Komm_bei_KL15_EIN" 1 "Komm_nach_KL15_AUS" 2 "Komm_bei_KL15_AUS" ;
VAL_ 2549088403 BedienSG_hi_SNI 147 "BedienSG_hi" ;
VAL_ 2549088403 KN_BedienSG_hi_ECUKnockOutTimer 63 "ECUKnockOut_deaktiviert" ;
VAL_ 2549088403 KN_BedienSG_hi_BusKnockOut 0 "Funktion_nicht_ausgeloest" 1 "Veto_aktiv" 2 "Funktion_ausgeloest" 3 "Funktion_deaktiviert" ;
VAL_ 2549088403 KN_BedienSG_hi_BusKnockOutTimer 255 "BusKnockOut_deaktiviert" ;
VAL_ 2549088403 NMH_BedienSG_hi_Wakeup 0 "Peripherie_Wakeup__Ursache_nicht_bekannt" 1 "Bus_Wakeup" 2 "KL15_HW" ;
VAL_ 2549088403 KN_BedienSG_hi_ECUKnockOut 0 "Funktion_nicht_ausgeloest" 1 "Veto_war_aktiv" 2 "Funktion_ausgeloest" 3 "Funktion_deaktiviert" ;
VAL_ 2549088403 NMH_BedienSG_hi_Lokalaktiv 0 "war_nicht_lokal_aktiv" 1 "war_lokal_aktiv" ;
VAL_ 2549088403 NMH_BedienSG_hi_Subsystemaktiv 0 "Subsystem_war_nicht_lokalaktiv" 1 "war_lokalaktiv" ;
VAL_ 2549088403 BedienSG_hi_KD_Fehler 0 "kein_KD_Fehler" 1 "KD_Fehler" ;
VAL_ 2549088442 DDA_KompSchutz 0 "inaktiv" 1 "aktiv" ;
VAL_ 2549088442 DDA_Abschaltstufe 0 "keine_Einschraenkung" 1 "Funktionseinschraenkung" ;
VAL_ 2549088442 DDA_Transport_Mode 0 "keine_Einschraenkung" 1 "Funktionseinschraenkung" ;
VAL_ 2549088442 DDA_Nachlauftyp 0 "Komm_bei_KL15_EIN" 1 "Komm_nach_KL15_AUS" 2 "Komm_bei_KL15_AUS" ;
VAL_ 2549088442 DDA_SNI 186 "DDA" ;
VAL_ 2549088442 KN_DDA_BusKnockOutTimer 255 "BusKnockOut_deaktiviert" ;
VAL_ 2549088442 NM_DDA_Wakeup 0 "Peripherie_Wakeup__Ursache_nicht_bekannt" 1 "Bus_Wakeup" 2 "KL15_HW" 3 "Bluetoothverbindung_aktiv" ;
VAL_ 2549088442 NM_DDA_Lokalaktiv 0 "war_nicht_Lokalaktiv" 1 "war_Lokalaktiv" ;
VAL_ 2549088442 DDA_KD_Fehler 0 "kein_KD_Fehler" 1 "KD_Fehler" ;
VAL_ 2549088272 Gateway_KompSchutz 0 "inaktiv" 1 "aktiv" ;
VAL_ 2549088272 Gateway_Abschaltstufe 0 "keine_Einschraenkung" 1 "Funktionseinschraenkung" ;
VAL_ 2549088272 Gateway_Transport_Mode 0 "keine_Einschraenkung" 1 "Funktionseinschraenkung" ;
VAL_ 2549088272 Gateway_Nachlauftyp 0 "Komm_bei_KL15_EIN" 1 "Komm_nach_KL15_AUS" 2 "Komm_bei_KL15_AUS" ;
VAL_ 2549088272 Gateway_SNI 16 "Gateway" ;
VAL_ 2549088272 NM_Gateway_Wakeup 0 "Peripherie_Wakeup__Ursache_nicht_bekannt" 1 "Bus_Wakeup" 2 "KL15_HW" 3 "ACAN_Wakeup" 4 "FCAN_Wakeup" 5 "KCAN_Wakeup" 6 "ICAN_Wakeup" 7 "DiagCAN_Wakeup" 8 "ECAN_Wakeup" 9 "Energie_LIN_Wakeup" 10 "Bedien_LIN_Wakeup" 11 "HybridCAN_Wakeup" 12 "Flexray_Wakeup" 13 "MFL_WakeUp" 14 "Ethernet" 15 "DCAN_Wakeup" 16 "K2CAN_Wakeup" 17 "CCAN" 18 "AFSCAN_Wakeup" 32 "FlexRay_Branch1_WakeUp" 33 "FlexRay_Branch2_WakeUp" 34 "FlexRay_Branch3_WakeUp" 35 "FlexRay_Branch4_WakeUp" 36 "FlexRay_Branch5_WakeUp" 37 "FlexRay_Branch6_WakeUp" 38 "FlexRay_Branch7_WakeUp" 39 "FlexRay_Branch8_WakeUp" 40 "FlexRay_Branch9_WakeUp" 41 "FlexRay_Branch10_WakeUp" 42 "FlexRay_Branch11_WakeUp" 43 "FlexRay_Branch12_WakeUp" 44 "FlexRay_Branch13_WakeUp" 45 "FlexRay_Branch14_WakeUp" 46 "FlexRay_Branch15_WakeUp" 47 "FlexRay_Branch16_WakeUp" 128 "Energiemanagement" 129 "Funktionswakeup_OBDC" 130 "Hochvoltenergiemanagement" 131 "CWU_empfangen" 132 "Fuer_Bus_relevanten_FC_empfangen" 133 "OnlineDienst_empfangen" 134 "HV_Aktivieren" 135 "HV_Deaktivieren" 136 "VTS_Suche_DriverCard" 137 "VTS_Hupen_Blinken" 138 "Remote_Vehicle_Status" 139 "Plug_and_Charge" 140 "VTS_Wakeup_Infotainment" 141 "EMHLR" 142 "NFcGW_fordert_OTA_FC_an" 143 "Komponentenschutz" 144 "UserStateServer" 145 "Dimmung" 146 "Kessy" 147 "StandardAussenlicht" 148 "ParkKoordinator" 149 "HVLMDynamicChargingPOI" 150 "HVLMChargingManagementServer" 151 "HVLMExtendedChargingMonitoring" 152 "Zentralverriegelung" 153 "FunctionOnDemand" 154 "IAA" 155 "StandKlimatisierung" 156 "RealTimeMonitor" 157 "Klemmensteuerung" ;
VAL_ 2549088272 NM_Gateway_Lokalaktiv 0 "war_nicht_lokal_aktiv" 1 "war_lokal_aktiv" ;
VAL_ 2549088272 NM_Gateway_Subsystemaktiv 0 "Subsystem_war_nicht_lokalaktiv" 1 "war_lokalaktiv" ;
VAL_ 2549088272 GW_KD_Fehler 0 "kein_KD_Fehler" 1 "KD_Fehler" ;
VAL_ 2549088355 GM_KompSchutz 0 "inaktiv" 1 "aktiv" ;
VAL_ 2549088355 GM_Abschaltstufe 0 "keine_Einschraenkung" 1 "Funktionseinschraenkung" ;
VAL_ 2549088355 GM_Transport_Mode 0 "keine_Einschraenkung" 1 "Funktionseinschraenkung" ;
VAL_ 2549088355 GM_Nachlauftyp 0 "Komm_bei_KL15_EIN" 1 "Komm_nach_KL15_AUS" 2 "Komm_bei_KL15_AUS" ;
VAL_ 2549088355 GM_SNI 99 "GM" ;
VAL_ 2549088355 NM_GM_Wakeup 0 "Peripherie_Wakeup__Ursache_nicht_bekannt" 1 "Bus_Wakeup" 2 "KL15_HW" ;
VAL_ 2549088355 GM_Lokalaktiv 0 "war_nicht_lokal_aktiv" 1 "war_lokal_aktiv" ;
VAL_ 2549088355 GM_Subsystemaktiv 0 "Subsystem_war_nicht_lokalaktiv" 1 "war_lokalaktiv" ;
VAL_ 2549088355 GM_KD_Fehler 0 "kein_KD_Fehler" 1 "KD_Fehler" ;
VAL_ 2549088371 Info_El_KompSchutz 0 "inaktiv" 1 "aktiv" ;
VAL_ 2549088371 Info_El_Abschaltstufe 0 "keine_Einschraenkung" 1 "Funktionseinschraenkung" ;
VAL_ 2549088371 Info_El_Transport_Mode 0 "keine_Einschraenkung" 1 "Funktionseinschraenkung" ;
VAL_ 2549088371 Info_El_Nachlauftyp 0 "Komm_bei_KL15_EIN" 1 "Komm_nach_KL15_AUS" 2 "Komm_bei_KL15_AUS" ;
VAL_ 2549088371 Info_El_SNI 115 "Info_El" ;
VAL_ 2549088371 KN_Info_El_BusKnockOutTimer 255 "BusKnockOut_deaktiviert" ;
VAL_ 2549088371 NM_Info_El_Wakeup 0 "Peripherie_Wakeup__Ursache_nicht_bekannt" 1 "Bus_Wakeup" 2 "KL15_HW" 3 "Eject_Button" 4 "Remote_Lock_Unlock" 5 "Remote_Standheizung" 128 "WakeUp_Lock_Anf" 129 "Display_On_Anf" 130 "HMI_OnlineUpdate" ;
VAL_ 2549088371 NM_Info_El_Lokalaktiv 0 "war_nicht_lokal_aktiv" 1 "war_lokal_aktiv" ;
VAL_ 2549088371 NM_Info_El_Subsystemaktiv 0 "Subsystem_war_nicht_lokalaktiv" 1 "war_lokalaktiv" ;
VAL_ 2549088371 Info_El_KD_Fehler 0 "Kein KD_Fehler" 1 "KD_Fehler" ;
VAL_ 2549088258 Sekundaer_02_KompSchutz 0 "inaktiv" 1 "aktiv" ;
VAL_ 2549088258 Sekundaer_02_Abschaltstufe 0 "keine_Einschraenkung" 1 "Funktionseinschraenkung" ;
VAL_ 2549088258 Sekundaer_02_Transport_Mode 0 "keine_Einschraenkung" 1 "Funktionseinschraenkung" ;
VAL_ 2549088258 Sekundaer_02_Nachlauftyp 0 "Komm_bei_KL15_EIN" 1 "Komm_nach_KL15_AUS" 2 "Komm_bei_KL15_AUS" ;
VAL_ 2549088258 Sekundaer_02_SNI 2 "Sekundaer_02" ;
VAL_ 2549088258 NM_Sekundaer_02_Wakeup 0 "Peripherie_Wakeup__Ursache_nicht_bekannt" 1 "Bus_Wakeup" 2 "KL15_HW" ;
VAL_ 2549088258 NM_Sekundaer_02_Lokalaktiv 0 "war_nicht_lokal_aktiv" 1 "war_lokal_aktiv" ;
VAL_ 2549088258 NM_Sekundaer_02_Subsystemaktiv 0 "Subsystem_war_nicht_lokalaktiv" 1 "war_lokalaktiv" ;
VAL_ 2549088258 Sekundaer_02_KD_Fehler 0 "kein_KD_Fehler" 1 "KD_Fehler" ;
VAL_ 779 KBI_ABS_Lampe 0 "ABS Lampe aus" 1 "ABS Lampe ein" ;
VAL_ 779 KBI_ESP_Lampe 0 "ESP Lampe aus" 1 "ESP Lampe ein" ;
VAL_ 779 KBI_BKL_Lampe 0 "BKL aus" 1 "BKL ein" ;
VAL_ 779 KBI_Airbag_Lampe 0 "Airbag Lampe aus" 1 "Airbag Lampe ein" ;
VAL_ 779 KBI_SILA_gueltig 0 "ungueltig" 1 "gueltig" ;
VAL_ 779 KBI_Vorglueh_System_Lampe 0 "Lampe aus" 1 "Lampe ein" ;
VAL_ 779 KBI_NV_in_Anzeige 0 "NV_nicht_in_Anzeige" 1 "NV_in_Anzeige" ;
VAL_ 779 KBI_Anzeigestatus_ACC 0 "keine_ACC_Anzeige" 1 "ACC_Anzeige_aktiv" ;
VAL_ 779 KBI_Anzeigestatus_GRA 0 "nicht_vorhanden" 1 "Anzeigemoeglichkeit_vorhanden" 2 "reserviert" 3 "Fehler" ;
VAL_ 779 KBI_Tankwarnung 0 "Lampe aus" 1 "Lampe ein" ;
VAL_ 779 KBI_MFA_v_Einheit_01 0 "kmh" 1 "mph" ;
VAL_ 779 KBI_im_Stellgliedtest 0 "kein Stellgliedtest" 1 "Kombi im Stellgliedtest" ;
VAL_ 779 KBI_Anzeigefehler_LDW 0 "nicht vorhanden bzw. unterstützt" 1 "Anzeige iO" 2 "Anzeigefehler" 3 "nicht definiert" ;
VAL_ 779 KBI_Tankwarnung_ungueltig 0 "KBI_Tankwarnung_gueltig" 1 "KBI_Tankwarnung_ungueltig" ;
VAL_ 779 KBI_Handbremse 0 "nicht_angezogen" 1 "angezogen" ;
VAL_ 779 KBI_PLA_in_Anzeige 0 "PLA_nicht_in_Anzeige" 1 "PLA_in_Anzeige" ;
VAL_ 779 KBI_Anzeigefehler_NV 0 "kein_Anzeigefehler" 1 "Anzeigefehler" ;
VAL_ 779 KBI_Anzeigestatus_LIM 0 "nicht_vorhanden" 1 "Anzeigemoeglichkeit_vorhanden" 2 "reserviert" 3 "Fehler" ;
VAL_ 779 KBI_ARA_in_Anzeige 0 "ARA nicht in Anzeige" 1 "ARA in Anzeige" ;
VAL_ 779 KBI_Taster_Lift 0 "nicht_betaetigt" 1 "betaetigt" ;
VAL_ 779 KBI_Taster_Fahrwerk 0 "nicht_betaetigt" 1 "betaetigt" ;
VAL_ 779 KBI_GRA_Hauptschalter 0 "Init" 1 "Hauptschalter_aus" 2 "Hauptschalter_ein" 3 "Fehler" ;
VAL_ 779 KBI_Einheit_Tacho 0 "km/h" 1 "mph" ;
VAL_ 779 KBI_Konsistenz_ACC 0 "ACC Botschaft konsistent" 1 "ACC Botschaft inkonsistent" ;
VAL_ 779 KBI_Fehler_Anzeige_ACC 0 " iO" 1 "Anzeigefehler ACC" ;
VAL_ 779 KBI_Anzeigefehler_SWA 0 "nicht vorhanden bzw. unterstützt" 1 "Anzeige iO" 2 "Anzeigefehler" 3 "nicht definiert" ;
VAL_ 779 KBI_Systemstatus 0 "KBI_IO" 1 "KBI_System_Failure" ;
VAL_ 1719 KBI_Kilometerstand 1048574 "Init" 1048575 "Fehler" ;
VAL_ 1719 KBI_Standzeit_02 131069 "nicht_verfuegbar" 131070 "Init" 131071 "Fehler" ;
VAL_ 1719 KBI_LVDS_Lock 0 "Init_LVDS_nicht_gelockt" 1 "LVDS_gelockt" ;
VAL_ 1719 KBI_Reserve_Warnung_Sek 0 "Keine_Warnung" 1 "Sekundaere_Reservewarnung" ;
VAL_ 1719 KBI_RDK_Kalibrier_Anf 0 "keine_Kalibrieranforderung" 1 "Kalibrieranforderung" ;
VAL_ 1719 KBI_Inhalt_Tank 126 "Init" 127 "Fehler" ;
VAL_ 1719 KBI_FStatus_Tank 0 "Tankfüllstand i.O." 1 "Tankfüllstand n.i.O" ;
VAL_ 1719 KBI_aktive_Laengsfunktion 0 "Init" 1 "Speedlimiter" 2 "GRA_oder_ACC" 3 "PACCh" 4 "HDC" 5 "p_GRA" 6 "p_Lim" 7 "Umschaltung_GRA_Limiter" ;
VAL_ 1719 KBI_TA_gewaehlt_Fahrer 0 "TA_nicht_gewaehlt_Kombi" 1 "TA_gewaehlt_Kombi" ;
VAL_ 1719 KBI_FoD_PopUP_Quittiert 0 "nicht_quittiert" 1 "Meldung_quittiert" ;
VAL_ 1719 KBI_GRA_im_ACC 0 "GRA_im_ACC_nicht_ausgewaehlt" 1 "GRA_im_ACC_ausgewaehlt" ;
VAL_ 1719 KBI_Oelwechsel_durchgefuehrt 0 "Oelwechsel_nicht_durchgefuehrt" 1 "Oelwechsel_durchgefuehrt" ;
VAL_ 1719 KBI_QBit_Aussen_Temp_gef 0 "gueltiger_Wert" 1 "Ersatz_Init_oder_Fehlerwert" ;
VAL_ 1719 KBI_Aussen_Temp_gef 253 "nicht verbaut" 254 "Init" 255 "Fehler" ;
VAL_ 1720 KBI_Variante_USA 0 "keine USA-Variante" 1 "USA-Variante" ;
VAL_ 1720 KBI_Variante 0 "Zeiger Kombiinstrument" 1 "Volldisplay Kombiinstrument" ;
VAL_ 1720 KBI_GAP_Warn_Zeit_abgelaufen 0 "Zaehler_nicht_abgelaufen" 1 "Zaehler_abgelaufen" ;
VAL_ 1720 KBI_Quittierung_Naesse 0 "nicht_quittiert" 1 "quittiert" ;
VAL_ 1720 KBI_BCmE_aktiv 0 "Anzeige_nicht_aktiv" 1 "Anzeige_aktiv" ;
VAL_ 1720 KBI_Sparhinweis_quittiert 0 "nicht_quittiert" 1 "quittiert" ;
VAL_ 1720 KBI_Tankfuellstand_Prozent 126 "Init" 127 "Fehler" ;
VAL_ 1720 KBI_Nachtanken_erkannt 0 "Geberbetrieb" 1 "Nachtankmodus" ;
VAL_ 1720 KBI_Tankinhalt_hochaufl 16382 "Init" 16383 "Fehler" ;
VAL_ 1720 KBI_Max_Tankinhalt 254 "Init" 255 "Fehler" ;
VAL_ 1720 KBI_Quittierung_cAQP 0 "nicht_quittiert" 1 "quittiert" ;
VAL_ 1724 KBI_Oil_dis_status 0 "Funktion nicht verfügbar" 1 "kein Wert berechnet" 2 "Service in ..." 3 "Service seit ... " ;
VAL_ 1724 KBI_Oil_dis_unit 0 "km" 1 "Meilen" ;
VAL_ 1724 KBI_Oil_time_status 0 "Funktion nicht verfügbar" 1 "kein Wert berechnet" 2 "Service in ..." 3 "Service seit ... " ;
VAL_ 1724 KBI_Insp_dis_status 0 "Funktion nicht verfügbar" 1 "kein Wert berechnet" 2 "Service in ..." 3 "Service seit ... " ;
VAL_ 1724 KBI_Insp_dis_unit 0 "km" 1 "Meilen" ;
VAL_ 1724 KBI_Insp_time_status 0 "Funktion nicht verfügbar" 1 "kein Wert berechnet" 2 "Service in ..." 3 "Service seit ... " ;
VAL_ 2527679638 KBI_Status_StoppUhr 0 "init" 1 "not_running_reset" 2 "not_running_no_reset" 3 "running" ;
VAL_ 2527679639 KBI_Weg_Zaehler_F 0 "kein Fehler" 1 "Fehler" ;
VAL_ 2527679639 KBI_Jokerkey 0 "nicht_betaetigt" 1 "betaetigt" ;
VAL_ 2527679639 KBI_RS_Druck_uebernehmen 0 " Druck für Rundstreckenmodue nicht uebernehmen" 1 " Druck für Rundstreckenmodus uebernehmen" ;
VAL_ 2527679639 KBI_RS_Druckauswahl_Aktiv 0 "inaktiv" 1 "aktiv" ;
VAL_ 2527679639 KBI_RS_Mode_fortsetzen 0 "Rundstreckenmodus_nicht_fortsetzen" 1 "Rundstreckenmodus_fortsetzen" ;
VAL_ 2527679639 KBI_Rundstreckenmodus 0 "nicht_angefordert" 1 "angefordert" ;
VAL_ 2527679656 KBI_StartupAnimation 0 "Init" 1 "StartMeasureDelay" 2 "RequestStartAnimation" 3 "RequestCancelAnimation" 4 "CIAnimationStarted" 5 "CIAnimationStopped" ;
VAL_ 701 LAE_BetaSlipAngle_02 32766 "Init" 32767 "Fehler" ;
VAL_ 701 LAE_Vx_VZ 0 "Positive" 1 "Negative" ;
VAL_ 701 LAE_mu_confidence 0 "Factor_0" 1 "Factor_1" 2 "Factor_2" 3 "Factor_3" 4 "Factor_4" 5 "Factor_5" 6 "Factor_6" 7 "Factor_7" ;
VAL_ 701 LAE_mu 62 "Init" 63 "Fehler" ;
VAL_ 701 LAE_Vy 62 "Init" 63 "Fehler" ;
VAL_ 701 LAE_Vy_confidence 0 "Factor_0" 1 "Factor_1" 2 "Factor_2" 3 "Factor_3" 4 "Factor_4" 5 "Factor_5" 6 "Factor_6" 7 "Factor_7" ;
VAL_ 701 LAE_BetaSlipAngle 254 "Init" 255 "Fehler" ;
VAL_ 701 LAE_Beta_VZ 0 "positive_links_von_der_nullst" 1 "negativ" ;
VAL_ 701 LAE_Beta_confidence 0 "Factor_0" 1 "Factor_1" 2 "Factor_2" 3 "Factor_3" 4 "Factor_4" 5 "Factor_5" 6 "Factor_6" 7 "Factor_7" ;
VAL_ 701 LAE_Vx_confidence 0 "Factor_0" 1 "Factor_1" 2 "Factor_2" 3 "Factor_3" 4 "Factor_4" 5 "Factor_5" 6 "Factor_6" 7 "Factor_7" ;
VAL_ 701 LAE_Vx 510 "Init" 511 "Fehler" ;
VAL_ 2527679653 MXB_LAPP_Freigabe 0 "keine_Freigabe" 1 "Freigabe" ;
VAL_ 2527679653 MXB_LAPP_ZR_Sondermodus_Anf 0 "nicht_angefordert" 1 "angefordert" ;
VAL_ 2527679653 MXB_LAPP_Status_FL 0 "MXB_aus" 1 "MXB_regelt" 2 "MXB_volles_Fernlicht" 3 "MXB_und_Laser_aktiv" ;
VAL_ 2463978818 LCV_ESP_Zuschaltung 0 "keine_ESP_Beeinflussung" 1 "ESP_Zwangszuschaltung_gefordert" ;
VAL_ 2463978818 LCV_BrakeGongTemp 0 "Not_Active" 1 "Active" ;
VAL_ 2463978818 BTM_BrakeSystem_Status 0 "Status_1" 1 "Status_2" 2 "Status_3" 3 "Status_4" 4 "Status_5" 5 "Status_6" 6 "Status_7" 7 "Fehler" ;
VAL_ 2463978818 BTM_BrakeSystem_Text 0 "No_text" 1 "Text_1" 2 "Text_2" 3 "Text_3" 4 "Text_4" 5 "Text_5" 6 "Text_6" 7 "Text_7" ;
VAL_ 2463978818 BTM_BrakeSystem_Warnlampe 0 "Lamp_Off" 1 "Lamp_On" ;
VAL_ 2463978818 LCV_Aero_EngineBay_Cooling 0 "Strategy_OFF" 1 "Strategy_ON" ;
VAL_ 2463978818 LCV_Aero_Front_System_Status 0 "Closed" 1 "Position_1" 2 "Position_2" 3 "Opening" 4 "Closing" 5 "Bar_Mode" 6 "Special_Position" 7 "Failure" ;
VAL_ 2463978818 LCV_Aero_Rear_System_Status 0 "Closed" 1 "Position_1" 2 "Position_2" 3 "Opening" 4 "Closing" 5 "Bar_Mode" 6 "Special_Position" 7 "Failure" ;
VAL_ 2463978818 LCV_DR_Systemstatus 0 "Init" 1 "Normal_Operation" 2 "Tune_1" 3 "Tune_2" 4 "Tune_3" 5 "Tune_4" 6 "Function_restriction_active" 7 "Failure" ;
VAL_ 2463978818 LCV_DR_Text 0 "No_Text" 1 "Text_1" 2 "Text_2" 3 "Text_3" 4 "Text_4" 5 "Text_5" 6 "Text_6" 7 "Text_7" ;
VAL_ 2463978818 LCV_DR_Warnlampe 0 "Lamp_Off" 1 "Lamp_On_1" 2 "Lamp_On_2" 3 "Failure_Lamp" ;
VAL_ 2463978818 LCV_Lift_Status 0 "Lowered" 1 "Lifted_front" 2 "Lifting_front" 3 "Lowering_front" 4 "Temporary_unavailable" 5 "Warning" 6 "TBD" 7 "Fehler" 8 "Lifted_four_corner" 9 "Lifting_four_corner" 10 "Lowering_four_corner" ;
VAL_ 2463978818 LCV_Lift_Text 0 "No_Text" 1 "Text_1" 2 "Text_2" 3 "Text_3" 4 "Text_4" 5 "Text_5" 6 "Text_6" 7 "Text_7" ;
VAL_ 2463978818 LCV_Lift_Warnlampe_Status 0 "Lamp_Off" 1 "Lamp_On_Static" 2 "Lamp_On_Blinking" 3 "Failure_Lamp" ;
VAL_ 2463978818 LCV_Aero_Perf_Limit_Speed 254 "init" 255 "Fehler" ;
VAL_ 2463978818 LCV_Aero_Perf_Limit 0 "Strategy_OFF" 1 "Strategy_ON" ;
VAL_ 2463978818 LCV_HD_offen 1 "Heckdeckel_auf" ;
VAL_ 2527679780 LCV_Aero_BarMode_Activation 0 "Not_Active" 1 "Active" ;
VAL_ 2527679780 LCV_BarMode_Allowed 0 "Not_Active" 1 "Active" ;
VAL_ 2527679780 LCV_Aero_Button_Default 0 "None" 1 "Button_1" 2 "Button_2" 3 "Button_3" ;
VAL_ 2527679780 LCV_Aero_Button_Range 0 "none" 1 "first_two" 2 "last_two" 3 "all_three" ;
VAL_ 2527679780 LCV_Aero_Button_Select 0 "None" 1 "Button_1" 2 "Button_2" 3 "Button_3" ;
VAL_ 2527679780 LCV_Aero_Button_Tunable 0 "Not_tunable" 1 "Tunable" ;
VAL_ 2527679780 LCV_DR_Button_Default 0 "None" 1 "Button_1" 2 "Button_2" 3 "Button_3" ;
VAL_ 2527679780 LCV_DR_Button_Range 0 "none" 1 "first_two" 2 "last_two" 3 "all_three" ;
VAL_ 2527679780 LCV_DR_Button_Select 0 "Init" 1 "Button_1" 2 "Button_2" 3 "Button_3" 4 "None" ;
VAL_ 2527679780 LCV_DR_Button_Tunable 0 "Not_tunable" 1 "Tunable" ;
VAL_ 2463978684 BTM_BrakeDiscTemp_01 254 "Init" 255 "Fehler" ;
VAL_ 2463978684 BTM_BrakeDiscTemp_02 254 "Init" 255 "Fehler" ;
VAL_ 2463978684 BTM_BrakeDiscTemp_03 254 "Init" 255 "Fehler" ;
VAL_ 2463978684 BTM_BrakeDiscTemp_04 254 "Init" 255 "Fehler" ;
VAL_ 2463978684 BTM_BrakeFluidTemp_01 254 "Init" 255 "Fehler" ;
VAL_ 2463978684 BTM_BrakeFluidTemp_02 254 "Init" 255 "Fehler" ;
VAL_ 2463978684 BTM_BrakeFluidTemp_03 254 "Init" 255 "Fehler" ;
VAL_ 2463978684 BTM_BrakeFluidTemp_04 254 "Init" 255 "Fehler" ;
VAL_ 548 LCV_Aero_Front_Ratio 126 "init" 127 "Fehler" ;
VAL_ 548 LCV_Aero_Long_Ratio 126 "init" 127 "Fehler" ;
VAL_ 2589283974 BTM_BrakeDiscColour_01 0 "Colour_0" 1 "Colour_1" 2 "Colour_2" 3 "Colour_3" 4 "Colour_4" 5 "Colour_5" 6 "Colour_6" 7 "Fehler" ;
VAL_ 2589283974 BTM_BrakeDiscColour_02 0 "Colour_0" 1 "Colour_1" 2 "Colour_2" 3 "Colour_3" 4 "Colour_4" 5 "Colour_5" 6 "Colour_6" 7 "Fehler" ;
VAL_ 2589283974 BTM_BrakeDiscColour_03 0 "Colour_0" 1 "Colour_1" 2 "Colour_2" 3 "Colour_3" 4 "Colour_4" 5 "Colour_5" 6 "Colour_6" 7 "Fehler" ;
VAL_ 2589283974 BTM_BrakeDiscColour_04 0 "Colour_0" 1 "Colour_1" 2 "Colour_2" 3 "Colour_3" 4 "Colour_4" 5 "Colour_5" 6 "Colour_6" 7 "Fehler" ;
VAL_ 2589283974 BTM_BrakeFluidColour_01 0 "Colour_0" 1 "Colour_1" 2 "Colour_2" 3 "Colour_3" 4 "Colour_4" 5 "Colour_5" 6 "Colour_6" 7 "Fehler" ;
VAL_ 2589283974 BTM_BrakeFluidColour_02 0 "Colour_0" 1 "Colour_1" 2 "Colour_2" 3 "Colour_3" 4 "Colour_4" 5 "Colour_5" 6 "Colour_6" 7 "Fehler" ;
VAL_ 2589283974 BTM_BrakeFluidColour_03 0 "Colour_0" 1 "Colour_1" 2 "Colour_2" 3 "Colour_3" 4 "Colour_4" 5 "Colour_5" 6 "Colour_6" 7 "Fehler" ;
VAL_ 2589283974 BTM_BrakeFluidColour_04 0 "Colour_0" 1 "Colour_1" 2 "Colour_2" 3 "Colour_3" 4 "Colour_4" 5 "Colour_5" 6 "Colour_6" 7 "Fehler" ;
VAL_ 159 EPS_DSR_Status_02 0 "DSR_deaktiviert" 1 "DSR_Anf_nicht_ausfuehrbar" 2 "Kom_ESP_gestoert" 3 "EPS_funktionsbereit" 4 "DSR_Anf_abgew" 5 "ext_Momeingriff_aktiv" 6 "ext_LWeingriff_aktiv" 7 "ext_MomLWeingriff_aktiv" 8 "DSR_abgewiesen_aufgrund_Momentenpriorisierung" 9 "Anf_abgewiesen_Bedienueblich" 14 "Init" ;
VAL_ 159 EPS_Berechneter_LW 4094 "Init" 4095 "Fehler" ;
VAL_ 159 EPS_BLW_QBit 0 "gueltiger_Wert" 1 "Ersatz_Init_oder_Fehlerwert" ;
VAL_ 159 EPS_VZ_BLW 0 "positiv" 1 "negativ" ;
VAL_ 159 EPS_HCA_Status_02 0 "nicht_aktiv" 1 "Anf_nicht_ausfuehrbar" 2 "KomFehler" 3 "bereit" 4 "Anf_abgewiesen_Fehler" 5 "LaneAssist_1_aktiv" 6 "ManoeverAssist_aktiv" 7 "LaneAssist_2_aktiv" 8 "Anf_abgewiesen_Prio" 9 "Anf_abgewiesen_bedienueblich" 10 "bereit_2" 14 "Init" ;
VAL_ 159 EPS_Lenkmoment 1022 "Init" 1023 "Fehler" ;
VAL_ 159 EPS_Lenkmoment_QBit 0 "gueltiger_Wert" 1 "Ersatz_Init_oder_Fehlerwert" ;
VAL_ 159 EPS_VZ_Lenkmoment 0 "positiv" 1 "negativ" ;
VAL_ 159 EPS_Lenkungstyp 0 "RCEPS_Serie" 1 "RCEPS_Dynamiklenkung" 2 "MQB_DP" 3 "MQB_APA" 4 "MQB_Direktlenkung" 15 "unbekannt" ;
VAL_ 981 BCM1_Kurvenlicht_links_Anf 0 "linkes_Kurvenlicht/Abbiegelicht_durch_BCM1_nicht_angesteuert" 1 "linkes_Kurven/Abbiegelicht_durch_BCM1_angesteuert" ;
VAL_ 981 BCM1_Kurvenlicht_rechts_Anf 0 "rechtes_Kurvenlicht/Abbiegelicht_durch_BCM1_nicht_angesteuert" 1 "rechtes_Kurvenlicht/Abbiegelicht_durch_BCM1_angesteuert" ;
VAL_ 981 BCM1_Standlicht_Anf 0 "Licht_nicht_angefordert" 1 "Licht ist einzuschalten" ;
VAL_ 981 BCM1_Abblendlicht_Anf 0 "Licht_nicht_angefordert" 1 "Licht ist einzuschalten" ;
VAL_ 981 BCM1_Fernlicht_Anf 0 "Licht_nicht_angefordert" 1 "Licht ist einzuschalten" ;
VAL_ 981 BCM1_Nebellicht_Anf 0 "Licht_nicht_angefordert" 1 "Licht ist einzuschalten" ;
VAL_ 981 BCM1_Parklicht_li_Anf 0 "Licht_nicht_angefordert" 1 "Licht ist einzuschalten" ;
VAL_ 981 BCM1_Parklicht_re_Anf 0 "Licht_nicht_angefordert" 1 "Licht ist einzuschalten" ;
VAL_ 981 BCM1_Nebelschluss_Ahg_Anf 0 "Licht_nicht_angefordert" 1 "Licht ist einzuschalten" ;
VAL_ 981 BCM1_Nebelschluss_Fzg_Anf 0 "Licht_nicht_angefordert" 1 "Licht ist einzuschalten" ;
VAL_ 981 BCM1_Schlusslicht_Anf 0 "Licht_nicht_angefordert" 1 "Licht ist einzuschalten" ;
VAL_ 981 BCM_Rueckfahrlicht_Anf 0 "Licht_nicht_angefordert" 1 "Licht_angefordert" ;
VAL_ 981 BCM1_Signaturlicht_Anf 0 "Licht_nicht_angefordert" 1 "Licht_ist_einzuschalten" ;
VAL_ 981 BCM1_Umfeldleuchten_Anf 0 "Licht_nicht_angefordert" 1 "Licht_ist_einzuschalten" ;
VAL_ 981 BCM1_Tagfahrlicht_Anf 0 "Licht_nicht_angefordert" 1 "Licht ist einzuschalten" ;
VAL_ 981 BCM1_Regenlicht_Anf 0 "Licht_nicht_angefordert" 1 "Licht ist einzuschalten" ;
VAL_ 981 BCM1_Autobahnlicht_Anf 0 "Licht_nicht_angefordert" 1 "Licht ist einzuschalten" ;
VAL_ 981 BCM1_Touristen_Licht_Anf 0 "Licht_nicht_angefordert" 1 "Anforderung von Touristenlicht" ;
VAL_ 981 BCM1_CH_aktiv 0 "Inaktiv" 1 "Aktiv" ;
VAL_ 981 BCM1_LH_aktiv 0 "Inaktiv" 1 "Aktiv" ;
VAL_ 981 BCM1_Gleitende_Leuchtw_Anf 0 "Aus" 1 "Ein" ;
VAL_ 981 BCM1_GLW_Fernlicht_Anf 0 "Aus" 1 "Ein" ;
VAL_ 981 BCM1_Adaptive_Lichtvert_Anf 0 "Aus" 1 "Ein" ;
VAL_ 981 BCM1_FoD_Sperrung_WiBli 0 "Freigabe_WiBli" 1 "Sperrung_WiBli" 2 "Init" ;
VAL_ 981 BCM1_FOD_Sperrung_Animationen_HL 0 "Freigabe_Animationen" 1 "Sperrung_Animationen" 2 "Init" ;
VAL_ 981 BCM1_Animationssperrung 0 "keine_Sperrung" 1 "Sperrung" ;
VAL_ 981 BCM1_CH_LH_aktiv 0 "Comming_Home_Bzw._Leaving_Home_nicht_aktiv" 1 "Comming Home bzw. Leaving Home aktiv" ;
VAL_ 981 BCM1_Allwetterlicht_Anf 0 "Licht_nicht_angefordert" 1 "Licht_ist_einzuschalten" ;
VAL_ 981 BCM1_Schlusslicht_Signatur 0 "keine_Signatur" 1 "Signatur_1" 2 "Signatur_2" 3 "Signatur_3" 4 "Signatur_4" 5 "Signatur_5" 6 "Signatur_6" 7 "Signatur_7" 8 "Signatur_8" 9 "Signatur_9" 10 "Signatur_10" 11 "Signatur_11" 12 "Signatur_12" 13 "Signatur_13" 14 "Signatur_14" 15 "Signatur_15" ;
